VERSION "created by canmatrix"

NS_ :

BS_:

BU_: IPD

BO_ 840 FDR_ADAS_LocalCANFD3_FrP09: 64 Vector__XXX
 SG_ MRR_Obj_CRC16Checksum_17 : 7|8@0+ (1,0) [0|255] "null" IPD
 SG_ MRR_Obj_MsgCounter_17 : 11|4@0+ (1,0) [0|15] "null" IPD
 SG_ MRR_ObjMovingSts_17 : 23|4@0+ (1,0) [0|15] "null" IPD
 SG_ MRR_ObjID_17 : 31|8@0+ (1,0) [0|255] "null" IPD
 SG_ MRR_ObjObstacleProb_17 : 34|5@0+ (0.03125,0) [0.00000|0.96875] "null" IPD
 SG_ MRR_ObjExistProb_17 : 39|5@0+ (0.03125,0) [0.00000|0.96875] "null" IPD
 SG_ MRR_ObjDistY_17 : 45|14@0+ (0.0078125,-64) [-64.0000000|63.9921875] "null" IPD
 SG_ MRR_ObjDistX_17 : 63|12@0+ (0.0625,0) [0.0000|255.9375] "null" IPD
 SG_ MRR_ObjType_17 : 67|4@0+ (1,0) [0|15] "null" IPD
 SG_ MRR_ObjRelVelX_17 : 79|13@0+ (0.0312,-128) [-128.0000|127.5592] "null" IPD
 SG_ MRR_ObjAccelX_17 : 81|10@0+ (0.03125,-16) [-16.00000|15.96875] "null" IPD
 SG_ MRR_ObjRelVelY_17 : 103|13@0+ (0.0312,-128) [-128.0000|127.5592] "null" IPD
 SG_ MRR_ObjAccelY_17 : 105|10@0+ (0.03125,-16) [-16.00000|15.96875] "null" IPD
 SG_ MRR_ObjDistYStd_17 : 121|6@0+ (0.0625,0) [0.0000|3.9375] "null" IPD
 SG_ MRR_ObjDistXStd_17 : 127|6@0+ (0.0625,0) [0.0000|3.9375] "null" IPD
 SG_ MRR_ObjRelVelXStd_17 : 131|6@0+ (0.0625,0) [0.0000|3.9375] "null" IPD
 SG_ MRR_ObjRelVelYStd_17 : 141|6@0+ (0.0625,0) [0.0000|3.9375] "null" IPD
 SG_ MRR_ObjRAccelYStd_17 : 145|6@0+ (0.0625,0) [0.0000|3.9375] "null" IPD
 SG_ MRR_ObjRAccelXStd_17 : 151|6@0+ (0.0625,0) [0.0000|3.9375] "null" IPD
 SG_ MRR_ObjFolSts_17 : 154|2@0+ (1,0) [0|3] "null" IPD
 SG_ MRR_ObjFusionSig_17 : 155|1@0+ (1,0) [0|1] "null" IPD
 SG_ MRR_ObjFusionCamID_17 : 167|8@0+ (1,0) [0|255] "null" IPD
 SG_ MRR_Obj_CRC16Checksum_18 : 175|8@0+ (1,0) [0|255] "null" IPD
 SG_ MRR_Obj_MsgCounter_18 : 179|4@0+ (1,0) [0|15] "null" IPD
 SG_ MRR_ObjID_18 : 199|8@0+ (1,0) [0|255] "null" IPD
 SG_ MRR_ObjObstacleProb_18 : 202|5@0+ (0.03125,0) [0.00000|0.96875] "null" IPD
 SG_ MRR_ObjExistProb_18 : 207|5@0+ (0.03125,0) [0.00000|0.96875] "null" IPD
 SG_ MRR_ObjDistY_18 : 213|14@0+ (0.0078125,-64) [-64.0000000|63.9921875] "null" IPD
 SG_ MRR_ObjDistX_18 : 231|12@0+ (0.0625,0) [0.0000|255.9375] "null" IPD
 SG_ MRR_ObjType_18 : 235|4@0+ (1,0) [0|15] "null" IPD
 SG_ MRR_ObjRelVelX_18 : 247|13@0+ (0.0312,-128) [-128.0000|127.5592] "null" IPD
 SG_ MRR_ObjAccelX_18 : 249|10@0+ (0.03125,-16) [-16.00000|15.96875] "null" IPD
 SG_ MRR_ObjRelVelY_18 : 271|13@0+ (0.0312,-128) [-128.0000|127.5592] "null" IPD
 SG_ MRR_ObjAccelY_18 : 273|10@0+ (0.03125,-16) [-16.00000|15.96875] "null" IPD
 SG_ MRR_ObjDistYStd_18 : 289|6@0+ (0.0625,0) [0.0000|3.9375] "null" IPD
 SG_ MRR_ObjDistXStd_18 : 295|6@0+ (0.0625,0) [0.0000|3.9375] "null" IPD
 SG_ MRR_ObjRelVelXStd_18 : 299|6@0+ (0.0625,0) [0.0000|3.9375] "null" IPD
 SG_ MRR_ObjRelVelYStd_18 : 309|6@0+ (0.0625,0) [0.0000|3.9375] "null" IPD
 SG_ MRR_ObjRAccelYStd_18 : 313|6@0+ (0.0625,0) [0.0000|3.9375] "null" IPD
 SG_ MRR_ObjRAccelXStd_18 : 319|6@0+ (0.0625,0) [0.0000|3.9375] "null" IPD
 SG_ MRR_ObjFolSts_18 : 322|2@0+ (1,0) [0|3] "null" IPD
 SG_ MRR_ObjFusionSig_18 : 323|1@0+ (1,0) [0|1] "null" IPD
 SG_ MRR_ObjFusionCamID_18 : 335|8@0+ (1,0) [0|255] "null" IPD
 SG_ MRR_ObjMovingSts_18 : 339|4@0+ (1,0) [0|15] "null" IPD

BO_ 841 FDR_ADAS_LocalCANFD3_FrP10: 64 Vector__XXX
 SG_ MRR_Obj_CRC16Checksum_19 : 7|8@0+ (1,0) [0|255] "null" IPD
 SG_ MRR_Obj_MsgCounter_19 : 11|4@0+ (1,0) [0|15] "null" IPD
 SG_ MRR_ObjMovingSts_19 : 23|4@0+ (1,0) [0|15] "null" IPD
 SG_ MRR_ObjID_19 : 31|8@0+ (1,0) [0|255] "null" IPD
 SG_ MRR_ObjObstacleProb_19 : 34|5@0+ (0.03125,0) [0.00000|0.96875] "null" IPD
 SG_ MRR_ObjExistProb_19 : 39|5@0+ (0.03125,0) [0.00000|0.96875] "null" IPD
 SG_ MRR_ObjDistY_19 : 45|14@0+ (0.0078125,-64) [-64.0000000|63.9921875] "null" IPD
 SG_ MRR_ObjDistX_19 : 63|12@0+ (0.0625,0) [0.0000|255.9375] "null" IPD
 SG_ MRR_ObjType_19 : 67|4@0+ (1,0) [0|15] "null" IPD
 SG_ MRR_ObjRelVelX_19 : 79|13@0+ (0.0312,-128) [-128.0000|127.5592] "null" IPD
 SG_ MRR_ObjAccelX_19 : 81|10@0+ (0.03125,-16) [-16.00000|15.96875] "null" IPD
 SG_ MRR_ObjRelVelY_19 : 103|13@0+ (0.0312,-128) [-128.0000|127.5592] "null" IPD
 SG_ MRR_ObjAccelY_19 : 105|10@0+ (0.03125,-16) [-16.00000|15.96875] "null" IPD
 SG_ MRR_ObjDistYStd_19 : 121|6@0+ (0.0625,0) [0.0000|3.9375] "null" IPD
 SG_ MRR_ObjDistXStd_19 : 127|6@0+ (0.0625,0) [0.0000|3.9375] "null" IPD
 SG_ MRR_ObjRelVelXStd_19 : 131|6@0+ (0.0625,0) [0.0000|3.9375] "null" IPD
 SG_ MRR_ObjRelVelYStd_19 : 141|6@0+ (0.0625,0) [0.0000|3.9375] "null" IPD
 SG_ MRR_ObjRAccelYStd_19 : 145|6@0+ (0.0625,0) [0.0000|3.9375] "null" IPD
 SG_ MRR_ObjRAccelXStd_19 : 151|6@0+ (0.0625,0) [0.0000|3.9375] "null" IPD
 SG_ MRR_ObjFolSts_19 : 154|2@0+ (1,0) [0|3] "null" IPD
 SG_ MRR_ObjFusionSig_19 : 155|1@0+ (1,0) [0|1] "null" IPD
 SG_ MRR_ObjFusionCamID_19 : 167|8@0+ (1,0) [0|255] "null" IPD
 SG_ MRR_Obj_CRC16Checksum_20 : 175|8@0+ (1,0) [0|255] "null" IPD
 SG_ MRR_Obj_MsgCounter_20 : 179|4@0+ (1,0) [0|15] "null" IPD
 SG_ MRR_ObjID_20 : 199|8@0+ (1,0) [0|255] "null" IPD
 SG_ MRR_ObjObstacleProb_20 : 202|5@0+ (0.03125,0) [0.00000|0.96875] "null" IPD
 SG_ MRR_ObjExistProb_20 : 207|5@0+ (0.03125,0) [0.00000|0.96875] "null" IPD
 SG_ MRR_ObjDistY_20 : 213|14@0+ (0.0078125,-64) [-64.0000000|63.9921875] "null" IPD
 SG_ MRR_ObjDistX_20 : 231|12@0+ (0.0625,0) [0.0000|255.9375] "null" IPD
 SG_ MRR_ObjType_20 : 235|4@0+ (1,0) [0|15] "null" IPD
 SG_ MRR_ObjRelVelX_20 : 247|13@0+ (0.0312,-128) [-128.0000|127.5592] "null" IPD
 SG_ MRR_ObjAccelX_20 : 249|10@0+ (0.03125,-16) [-16.00000|15.96875] "null" IPD
 SG_ MRR_ObjRelVelY_20 : 271|13@0+ (0.0312,-128) [-128.0000|127.5592] "null" IPD
 SG_ MRR_ObjAccelY_20 : 273|10@0+ (0.03125,-16) [-16.00000|15.96875] "null" IPD
 SG_ MRR_ObjDistYStd_20 : 289|6@0+ (0.0625,0) [0.0000|3.9375] "null" IPD
 SG_ MRR_ObjDistXStd_20 : 295|6@0+ (0.0625,0) [0.0000|3.9375] "null" IPD
 SG_ MRR_ObjRelVelXStd_20 : 299|6@0+ (0.0625,0) [0.0000|3.9375] "null" IPD
 SG_ MRR_ObjRelVelYStd_20 : 309|6@0+ (0.0625,0) [0.0000|3.9375] "null" IPD
 SG_ MRR_ObjRAccelYStd_20 : 313|6@0+ (0.0625,0) [0.0000|3.9375] "null" IPD
 SG_ MRR_ObjRAccelXStd_20 : 319|6@0+ (0.0625,0) [0.0000|3.9375] "null" IPD
 SG_ MRR_ObjFolSts_20 : 322|2@0+ (1,0) [0|3] "null" IPD
 SG_ MRR_ObjFusionSig_20 : 323|1@0+ (1,0) [0|1] "null" IPD
 SG_ MRR_ObjFusionCamID_20 : 335|8@0+ (1,0) [0|255] "null" IPD
 SG_ MRR_ObjMovingSts_20 : 339|4@0+ (1,0) [0|15] "null" IPD

BO_ 842 FDR_ADAS_LocalCANFD3_FrP11: 64 Vector__XXX
 SG_ MRR_Obj_CRC16Checksum_21 : 7|8@0+ (1,0) [0|255] "null" IPD
 SG_ MRR_Obj_MsgCounter_21 : 11|4@0+ (1,0) [0|15] "null" IPD
 SG_ MRR_ObjMovingSts_21 : 23|4@0+ (1,0) [0|15] "null" IPD
 SG_ MRR_ObjID_21 : 31|8@0+ (1,0) [0|255] "null" IPD
 SG_ MRR_ObjObstacleProb_21 : 34|5@0+ (0.03125,0) [0.00000|0.96875] "null" IPD
 SG_ MRR_ObjExistProb_21 : 39|5@0+ (0.03125,0) [0.00000|0.96875] "null" IPD
 SG_ MRR_ObjDistY_21 : 45|14@0+ (0.0078125,-64) [-64.0000000|63.9921875] "null" IPD
 SG_ MRR_ObjDistX_21 : 63|12@0+ (0.0625,0) [0.0000|255.9375] "null" IPD
 SG_ MRR_ObjType_21 : 67|4@0+ (1,0) [0|15] "null" IPD
 SG_ MRR_ObjRelVelX_21 : 79|13@0+ (0.0312,-128) [-128.0000|127.5592] "null" IPD
 SG_ MRR_ObjAccelX_21 : 81|10@0+ (0.03125,-16) [-16.00000|15.96875] "null" IPD
 SG_ MRR_ObjRelVelY_21 : 103|13@0+ (0.0312,-128) [-128.0000|127.5592] "null" IPD
 SG_ MRR_ObjAccelY_21 : 105|10@0+ (0.03125,-16) [-16.00000|15.96875] "null" IPD
 SG_ MRR_ObjDistYStd_21 : 121|6@0+ (0.0625,0) [0.0000|3.9375] "null" IPD
 SG_ MRR_ObjDistXStd_21 : 127|6@0+ (0.0625,0) [0.0000|3.9375] "null" IPD
 SG_ MRR_ObjRelVelXStd_21 : 131|6@0+ (0.0625,0) [0.0000|3.9375] "null" IPD
 SG_ MRR_ObjRelVelYStd_21 : 141|6@0+ (0.0625,0) [0.0000|3.9375] "null" IPD
 SG_ MRR_ObjRAccelYStd_21 : 145|6@0+ (0.0625,0) [0.0000|3.9375] "null" IPD
 SG_ MRR_ObjRAccelXStd_21 : 151|6@0+ (0.0625,0) [0.0000|3.9375] "null" IPD
 SG_ MRR_ObjFolSts_21 : 154|2@0+ (1,0) [0|3] "null" IPD
 SG_ MRR_ObjFusionSig_21 : 155|1@0+ (1,0) [0|1] "null" IPD
 SG_ MRR_ObjFusionCamID_21 : 167|8@0+ (1,0) [0|255] "null" IPD
 SG_ MRR_Obj_CRC16Checksum_22 : 175|8@0+ (1,0) [0|255] "null" IPD
 SG_ MRR_Obj_MsgCounter_22 : 179|4@0+ (1,0) [0|15] "null" IPD
 SG_ MRR_ObjID_22 : 199|8@0+ (1,0) [0|255] "null" IPD
 SG_ MRR_ObjObstacleProb_22 : 202|5@0+ (0.03125,0) [0.00000|0.96875] "null" IPD
 SG_ MRR_ObjExistProb_22 : 207|5@0+ (0.03125,0) [0.00000|0.96875] "null" IPD
 SG_ MRR_ObjDistY_22 : 213|14@0+ (0.0078125,-64) [-64.0000000|63.9921875] "null" IPD
 SG_ MRR_ObjDistX_22 : 231|12@0+ (0.0625,0) [0.0000|255.9375] "null" IPD
 SG_ MRR_ObjType_22 : 235|4@0+ (1,0) [0|15] "null" IPD
 SG_ MRR_ObjRelVelX_22 : 247|13@0+ (0.0312,-128) [-128.0000|127.5592] "null" IPD
 SG_ MRR_ObjAccelX_22 : 249|10@0+ (0.03125,-16) [-16.00000|15.96875] "null" IPD
 SG_ MRR_ObjRelVelY_22 : 271|13@0+ (0.0312,-128) [-128.0000|127.5592] "null" IPD
 SG_ MRR_ObjAccelY_22 : 273|10@0+ (0.03125,-16) [-16.00000|15.96875] "null" IPD
 SG_ MRR_ObjDistYStd_22 : 289|6@0+ (0.0625,0) [0.0000|3.9375] "null" IPD
 SG_ MRR_ObjDistXStd_22 : 295|6@0+ (0.0625,0) [0.0000|3.9375] "null" IPD
 SG_ MRR_ObjRelVelXStd_22 : 299|6@0+ (0.0625,0) [0.0000|3.9375] "null" IPD
 SG_ MRR_ObjRelVelYStd_22 : 309|6@0+ (0.0625,0) [0.0000|3.9375] "null" IPD
 SG_ MRR_ObjRAccelYStd_22 : 313|6@0+ (0.0625,0) [0.0000|3.9375] "null" IPD
 SG_ MRR_ObjRAccelXStd_22 : 319|6@0+ (0.0625,0) [0.0000|3.9375] "null" IPD
 SG_ MRR_ObjFolSts_22 : 322|2@0+ (1,0) [0|3] "null" IPD
 SG_ MRR_ObjFusionSig_22 : 323|1@0+ (1,0) [0|1] "null" IPD
 SG_ MRR_ObjFusionCamID_22 : 335|8@0+ (1,0) [0|255] "null" IPD
 SG_ MRR_ObjMovingSts_22 : 339|4@0+ (1,0) [0|15] "null" IPD

BO_ 843 FDR_ADAS_LocalCANFD3_FrP12: 64 Vector__XXX
 SG_ MRR_Obj_CRC16Checksum_23 : 7|8@0+ (1,0) [0|255] "null" IPD
 SG_ MRR_Obj_MsgCounter_23 : 11|4@0+ (1,0) [0|15] "null" IPD
 SG_ MRR_ObjMovingSts_23 : 23|4@0+ (1,0) [0|15] "null" IPD
 SG_ MRR_ObjID_23 : 31|8@0+ (1,0) [0|255] "null" IPD
 SG_ MRR_ObjObstacleProb_23 : 34|5@0+ (0.03125,0) [0.00000|0.96875] "null" IPD
 SG_ MRR_ObjExistProb_23 : 39|5@0+ (0.03125,0) [0.00000|0.96875] "null" IPD
 SG_ MRR_ObjDistY_23 : 45|14@0+ (0.0078125,-64) [-64.0000000|63.9921875] "null" IPD
 SG_ MRR_ObjDistX_23 : 63|12@0+ (0.0625,0) [0.0000|255.9375] "null" IPD
 SG_ MRR_ObjType_23 : 67|4@0+ (1,0) [0|15] "null" IPD
 SG_ MRR_ObjRelVelX_23 : 79|13@0+ (0.0312,-128) [-128.0000|127.5592] "null" IPD
 SG_ MRR_ObjAccelX_23 : 81|10@0+ (0.03125,-16) [-16.00000|15.96875] "null" IPD
 SG_ MRR_ObjRelVelY_23 : 103|13@0+ (0.0312,-128) [-128.0000|127.5592] "null" IPD
 SG_ MRR_ObjAccelY_23 : 105|10@0+ (0.03125,-16) [-16.00000|15.96875] "null" IPD
 SG_ MRR_ObjDistYStd_23 : 121|6@0+ (0.0625,0) [0.0000|3.9375] "null" IPD
 SG_ MRR_ObjDistXStd_23 : 127|6@0+ (0.0625,0) [0.0000|3.9375] "null" IPD
 SG_ MRR_ObjRelVelXStd_23 : 131|6@0+ (0.0625,0) [0.0000|3.9375] "null" IPD
 SG_ MRR_ObjRelVelYStd_23 : 141|6@0+ (0.0625,0) [0.0000|3.9375] "null" IPD
 SG_ MRR_ObjRAccelYStd_23 : 145|6@0+ (0.0625,0) [0.0000|3.9375] "null" IPD
 SG_ MRR_ObjRAccelXStd_23 : 151|6@0+ (0.0625,0) [0.0000|3.9375] "null" IPD
 SG_ MRR_ObjFolSts_23 : 154|2@0+ (1,0) [0|3] "null" IPD
 SG_ MRR_ObjFusionSig_23 : 155|1@0+ (1,0) [0|1] "null" IPD
 SG_ MRR_ObjFusionCamID_23 : 167|8@0+ (1,0) [0|255] "null" IPD
 SG_ MRR_Obj_CRC16Checksum_24 : 175|8@0+ (1,0) [0|255] "null" IPD
 SG_ MRR_Obj_MsgCounter_24 : 179|4@0+ (1,0) [0|15] "null" IPD
 SG_ MRR_ObjID_24 : 199|8@0+ (1,0) [0|255] "null" IPD
 SG_ MRR_ObjObstacleProb_24 : 202|5@0+ (0.03125,0) [0.00000|0.96875] "null" IPD
 SG_ MRR_ObjExistProb_24 : 207|5@0+ (0.03125,0) [0.00000|0.96875] "null" IPD
 SG_ MRR_ObjDistY_24 : 213|14@0+ (0.0078125,-64) [-64.0000000|63.9921875] "null" IPD
 SG_ MRR_ObjDistX_24 : 231|12@0+ (0.0625,0) [0.0000|255.9375] "null" IPD
 SG_ MRR_ObjType_24 : 235|4@0+ (1,0) [0|15] "null" IPD
 SG_ MRR_ObjRelVelX_24 : 247|13@0+ (0.0312,-128) [-128.0000|127.5592] "null" IPD
 SG_ MRR_ObjAccelX_24 : 249|10@0+ (0.03125,-16) [-16.00000|15.96875] "null" IPD
 SG_ MRR_ObjRelVelY_24 : 271|13@0+ (0.0312,-128) [-128.0000|127.5592] "null" IPD
 SG_ MRR_ObjAccelY_24 : 273|10@0+ (0.03125,-16) [-16.00000|15.96875] "null" IPD
 SG_ MRR_ObjDistYStd_24 : 289|6@0+ (0.0625,0) [0.0000|3.9375] "null" IPD
 SG_ MRR_ObjDistXStd_24 : 295|6@0+ (0.0625,0) [0.0000|3.9375] "null" IPD
 SG_ MRR_ObjRelVelXStd_24 : 299|6@0+ (0.0625,0) [0.0000|3.9375] "null" IPD
 SG_ MRR_ObjRelVelYStd_24 : 309|6@0+ (0.0625,0) [0.0000|3.9375] "null" IPD
 SG_ MRR_ObjRAccelYStd_24 : 313|6@0+ (0.0625,0) [0.0000|3.9375] "null" IPD
 SG_ MRR_ObjRAccelXStd_24 : 319|6@0+ (0.0625,0) [0.0000|3.9375] "null" IPD
 SG_ MRR_ObjFolSts_24 : 322|2@0+ (1,0) [0|3] "null" IPD
 SG_ MRR_ObjFusionSig_24 : 323|1@0+ (1,0) [0|1] "null" IPD
 SG_ MRR_ObjFusionCamID_24 : 335|8@0+ (1,0) [0|255] "null" IPD
 SG_ MRR_ObjMovingSts_24 : 339|4@0+ (1,0) [0|15] "null" IPD

BO_ 844 FDR_ADAS_LocalCANFD3_FrP13: 64 Vector__XXX
 SG_ MRR_Obj_CRC16Checksum_25 : 7|8@0+ (1,0) [0|255] "null" IPD
 SG_ MRR_Obj_MsgCounter_25 : 11|4@0+ (1,0) [0|15] "null" IPD
 SG_ MRR_ObjMovingSts_25 : 23|4@0+ (1,0) [0|15] "null" IPD
 SG_ MRR_ObjID_25 : 31|8@0+ (1,0) [0|255] "null" IPD
 SG_ MRR_ObjObstacleProb_25 : 34|5@0+ (0.03125,0) [0.00000|0.96875] "null" IPD
 SG_ MRR_ObjExistProb_25 : 39|5@0+ (0.03125,0) [0.00000|0.96875] "null" IPD
 SG_ MRR_ObjDistY_25 : 45|14@0+ (0.0078125,-64) [-64.0000000|63.9921875] "null" IPD
 SG_ MRR_ObjDistX_25 : 63|12@0+ (0.0625,0) [0.0000|255.9375] "null" IPD
 SG_ MRR_ObjType_25 : 67|4@0+ (1,0) [0|15] "null" IPD
 SG_ MRR_ObjRelVelX_25 : 79|13@0+ (0.0312,-128) [-128.0000|127.5592] "null" IPD
 SG_ MRR_ObjAccelX_25 : 81|10@0+ (0.03125,-16) [-16.00000|15.96875] "null" IPD
 SG_ MRR_ObjRelVelY_25 : 103|13@0+ (0.0312,-128) [-128.0000|127.5592] "null" IPD
 SG_ MRR_ObjAccelY_25 : 105|10@0+ (0.03125,-16) [-16.00000|15.96875] "null" IPD
 SG_ MRR_ObjDistYStd_25 : 121|6@0+ (0.0625,0) [0.0000|3.9375] "null" IPD
 SG_ MRR_ObjDistXStd_25 : 127|6@0+ (0.0625,0) [0.0000|3.9375] "null" IPD
 SG_ MRR_ObjRelVelXStd_25 : 131|6@0+ (0.0625,0) [0.0000|3.9375] "null" IPD
 SG_ MRR_ObjRelVelYStd_25 : 141|6@0+ (0.0625,0) [0.0000|3.9375] "null" IPD
 SG_ MRR_ObjRAccelYStd_25 : 145|6@0+ (0.0625,0) [0.0000|3.9375] "null" IPD
 SG_ MRR_ObjRAccelXStd_25 : 151|6@0+ (0.0625,0) [0.0000|3.9375] "null" IPD
 SG_ MRR_ObjFolSts_25 : 154|2@0+ (1,0) [0|3] "null" IPD
 SG_ MRR_ObjFusionSig_25 : 155|1@0+ (1,0) [0|1] "null" IPD
 SG_ MRR_ObjFusionCamID_25 : 167|8@0+ (1,0) [0|255] "null" IPD
 SG_ MRR_Obj_CRC16Checksum_26 : 175|8@0+ (1,0) [0|255] "null" IPD
 SG_ MRR_Obj_MsgCounter_26 : 179|4@0+ (1,0) [0|15] "null" IPD
 SG_ MRR_ObjID_26 : 199|8@0+ (1,0) [0|255] "null" IPD
 SG_ MRR_ObjObstacleProb_26 : 202|5@0+ (0.03125,0) [0.00000|0.96875] "null" IPD
 SG_ MRR_ObjExistProb_26 : 207|5@0+ (0.03125,0) [0.00000|0.96875] "null" IPD
 SG_ MRR_ObjDistY_26 : 213|14@0+ (0.0078125,-64) [-64.0000000|63.9921875] "null" IPD
 SG_ MRR_ObjDistX_26 : 231|12@0+ (0.0625,0) [0.0000|255.9375] "null" IPD
 SG_ MRR_ObjType_26 : 235|4@0+ (1,0) [0|15] "null" IPD
 SG_ MRR_ObjRelVelX_26 : 247|13@0+ (0.0312,-128) [-128.0000|127.5592] "null" IPD
 SG_ MRR_ObjAccelX_26 : 249|10@0+ (0.03125,-16) [-16.00000|15.96875] "null" IPD
 SG_ MRR_ObjRelVelY_26 : 271|13@0+ (0.0312,-128) [-128.0000|127.5592] "null" IPD
 SG_ MRR_ObjAccelY_26 : 273|10@0+ (0.03125,-16) [-16.00000|15.96875] "null" IPD
 SG_ MRR_ObjDistYStd_26 : 289|6@0+ (0.0625,0) [0.0000|3.9375] "null" IPD
 SG_ MRR_ObjDistXStd_26 : 295|6@0+ (0.0625,0) [0.0000|3.9375] "null" IPD
 SG_ MRR_ObjRelVelXStd_26 : 299|6@0+ (0.0625,0) [0.0000|3.9375] "null" IPD
 SG_ MRR_ObjRelVelYStd_26 : 309|6@0+ (0.0625,0) [0.0000|3.9375] "null" IPD
 SG_ MRR_ObjRAccelYStd_26 : 313|6@0+ (0.0625,0) [0.0000|3.9375] "null" IPD
 SG_ MRR_ObjRAccelXStd_26 : 319|6@0+ (0.0625,0) [0.0000|3.9375] "null" IPD
 SG_ MRR_ObjFolSts_26 : 322|2@0+ (1,0) [0|3] "null" IPD
 SG_ MRR_ObjFusionSig_26 : 323|1@0+ (1,0) [0|1] "null" IPD
 SG_ MRR_ObjFusionCamID_26 : 335|8@0+ (1,0) [0|255] "null" IPD
 SG_ MRR_ObjMovingSts_26 : 339|4@0+ (1,0) [0|15] "null" IPD

BO_ 845 FDR_ADAS_LocalCANFD3_FrP14: 64 Vector__XXX
 SG_ MRR_Obj_CRC16Checksum_27 : 7|8@0+ (1,0) [0|255] "null" IPD
 SG_ MRR_Obj_MsgCounter_27 : 11|4@0+ (1,0) [0|15] "null" IPD
 SG_ MRR_ObjMovingSts_27 : 23|4@0+ (1,0) [0|15] "null" IPD
 SG_ MRR_ObjID_27 : 31|8@0+ (1,0) [0|255] "null" IPD
 SG_ MRR_ObjObstacleProb_27 : 34|5@0+ (0.03125,0) [0.00000|0.96875] "null" IPD
 SG_ MRR_ObjExistProb_27 : 39|5@0+ (0.03125,0) [0.00000|0.96875] "null" IPD
 SG_ MRR_ObjDistY_27 : 45|14@0+ (0.0078125,-64) [-64.0000000|63.9921875] "null" IPD
 SG_ MRR_ObjDistX_27 : 63|12@0+ (0.0625,0) [0.0000|255.9375] "null" IPD
 SG_ MRR_ObjType_27 : 67|4@0+ (1,0) [0|15] "null" IPD
 SG_ MRR_ObjRelVelX_27 : 79|13@0+ (0.0312,-128) [-128.0000|127.5592] "null" IPD
 SG_ MRR_ObjAccelX_27 : 81|10@0+ (0.03125,-16) [-16.00000|15.96875] "null" IPD
 SG_ MRR_ObjRelVelY_27 : 103|13@0+ (0.0312,-128) [-128.0000|127.5592] "null" IPD
 SG_ MRR_ObjAccelY_27 : 105|10@0+ (0.03125,-16) [-16.00000|15.96875] "null" IPD
 SG_ MRR_ObjDistYStd_27 : 121|6@0+ (0.0625,0) [0.0000|3.9375] "null" IPD
 SG_ MRR_ObjDistXStd_27 : 127|6@0+ (0.0625,0) [0.0000|3.9375] "null" IPD
 SG_ MRR_ObjRelVelXStd_27 : 131|6@0+ (0.0625,0) [0.0000|3.9375] "null" IPD
 SG_ MRR_ObjRelVelYStd_27 : 141|6@0+ (0.0625,0) [0.0000|3.9375] "null" IPD
 SG_ MRR_ObjRAccelYStd_27 : 145|6@0+ (0.0625,0) [0.0000|3.9375] "null" IPD
 SG_ MRR_ObjRAccelXStd_27 : 151|6@0+ (0.0625,0) [0.0000|3.9375] "null" IPD
 SG_ MRR_ObjFolSts_27 : 154|2@0+ (1,0) [0|3] "null" IPD
 SG_ MRR_ObjFusionSig_27 : 155|1@0+ (1,0) [0|1] "null" IPD
 SG_ MRR_ObjFusionCamID_27 : 167|8@0+ (1,0) [0|255] "null" IPD
 SG_ MRR_Obj_CRC16Checksum_28 : 175|8@0+ (1,0) [0|255] "null" IPD
 SG_ MRR_Obj_MsgCounter_28 : 179|4@0+ (1,0) [0|15] "null" IPD
 SG_ MRR_ObjID_28 : 199|8@0+ (1,0) [0|255] "null" IPD
 SG_ MRR_ObjObstacleProb_28 : 202|5@0+ (0.03125,0) [0.00000|0.96875] "null" IPD
 SG_ MRR_ObjExistProb_28 : 207|5@0+ (0.03125,0) [0.00000|0.96875] "null" IPD
 SG_ MRR_ObjDistY_28 : 213|14@0+ (0.0078125,-64) [-64.0000000|63.9921875] "null" IPD
 SG_ MRR_ObjDistX_28 : 231|12@0+ (0.0625,0) [0.0000|255.9375] "null" IPD
 SG_ MRR_ObjType_28 : 235|4@0+ (1,0) [0|15] "null" IPD
 SG_ MRR_ObjRelVelX_28 : 247|13@0+ (0.0312,-128) [-128.0000|127.5592] "null" IPD
 SG_ MRR_ObjAccelX_28 : 249|10@0+ (0.03125,-16) [-16.00000|15.96875] "null" IPD
 SG_ MRR_ObjRelVelY_28 : 271|13@0+ (0.0312,-128) [-128.0000|127.5592] "null" IPD
 SG_ MRR_ObjAccelY_28 : 273|10@0+ (0.03125,-16) [-16.00000|15.96875] "null" IPD
 SG_ MRR_ObjDistYStd_28 : 289|6@0+ (0.0625,0) [0.0000|3.9375] "null" IPD
 SG_ MRR_ObjDistXStd_28 : 295|6@0+ (0.0625,0) [0.0000|3.9375] "null" IPD
 SG_ MRR_ObjRelVelXStd_28 : 299|6@0+ (0.0625,0) [0.0000|3.9375] "null" IPD
 SG_ MRR_ObjRelVelYStd_28 : 309|6@0+ (0.0625,0) [0.0000|3.9375] "null" IPD
 SG_ MRR_ObjRAccelYStd_28 : 313|6@0+ (0.0625,0) [0.0000|3.9375] "null" IPD
 SG_ MRR_ObjRAccelXStd_28 : 319|6@0+ (0.0625,0) [0.0000|3.9375] "null" IPD
 SG_ MRR_ObjFolSts_28 : 322|2@0+ (1,0) [0|3] "null" IPD
 SG_ MRR_ObjFusionSig_28 : 323|1@0+ (1,0) [0|1] "null" IPD
 SG_ MRR_ObjFusionCamID_28 : 335|8@0+ (1,0) [0|255] "null" IPD
 SG_ MRR_ObjMovingSts_28 : 339|4@0+ (1,0) [0|15] "null" IPD

BO_ 846 FDR_ADAS_LocalCANFD3_FrP15: 64 Vector__XXX
 SG_ MRR_Obj_CRC16Checksum_29 : 7|8@0+ (1,0) [0|255] "null" IPD
 SG_ MRR_Obj_MsgCounter_29 : 11|4@0+ (1,0) [0|15] "null" IPD
 SG_ MRR_ObjMovingSts_29 : 23|4@0+ (1,0) [0|15] "null" IPD
 SG_ MRR_ObjID_29 : 31|8@0+ (1,0) [0|255] "null" IPD
 SG_ MRR_ObjObstacleProb_29 : 34|5@0+ (0.03125,0) [0.00000|0.96875] "null" IPD
 SG_ MRR_ObjExistProb_29 : 39|5@0+ (0.03125,0) [0.00000|0.96875] "null" IPD
 SG_ MRR_ObjDistY_29 : 45|14@0+ (0.0078125,-64) [-64.0000000|63.9921875] "null" IPD
 SG_ MRR_ObjDistX_29 : 63|12@0+ (0.0625,0) [0.0000|255.9375] "null" IPD
 SG_ MRR_ObjType_29 : 67|4@0+ (1,0) [0|15] "null" IPD
 SG_ MRR_ObjRelVelX_29 : 79|13@0+ (0.0312,-128) [-128.0000|127.5592] "null" IPD
 SG_ MRR_ObjAccelX_29 : 81|10@0+ (0.03125,-16) [-16.00000|15.96875] "null" IPD
 SG_ MRR_ObjRelVelY_29 : 103|13@0+ (0.0312,-128) [-128.0000|127.5592] "null" IPD
 SG_ MRR_ObjAccelY_29 : 105|10@0+ (0.03125,-16) [-16.00000|15.96875] "null" IPD
 SG_ MRR_ObjDistYStd_29 : 121|6@0+ (0.0625,0) [0.0000|3.9375] "null" IPD
 SG_ MRR_ObjDistXStd_29 : 127|6@0+ (0.0625,0) [0.0000|3.9375] "null" IPD
 SG_ MRR_ObjRelVelXStd_29 : 131|6@0+ (0.0625,0) [0.0000|3.9375] "null" IPD
 SG_ MRR_ObjRelVelYStd_29 : 141|6@0+ (0.0625,0) [0.0000|3.9375] "null" IPD
 SG_ MRR_ObjRAccelYStd_29 : 145|6@0+ (0.0625,0) [0.0000|3.9375] "null" IPD
 SG_ MRR_ObjRAccelXStd_29 : 151|6@0+ (0.0625,0) [0.0000|3.9375] "null" IPD
 SG_ MRR_ObjFolSts_29 : 154|2@0+ (1,0) [0|3] "null" IPD
 SG_ MRR_ObjFusionSig_29 : 155|1@0+ (1,0) [0|1] "null" IPD
 SG_ MRR_ObjFusionCamID_29 : 167|8@0+ (1,0) [0|255] "null" IPD
 SG_ MRR_Obj_CRC16Checksum_30 : 175|8@0+ (1,0) [0|255] "null" IPD
 SG_ MRR_Obj_MsgCounter_30 : 179|4@0+ (1,0) [0|15] "null" IPD
 SG_ MRR_ObjID_30 : 199|8@0+ (1,0) [0|255] "null" IPD
 SG_ MRR_ObjObstacleProb_30 : 202|5@0+ (0.03125,0) [0.00000|0.96875] "null" IPD
 SG_ MRR_ObjExistProb_30 : 207|5@0+ (0.03125,0) [0.00000|0.96875] "null" IPD
 SG_ MRR_ObjDistY_30 : 213|14@0+ (0.0078125,-64) [-64.0000000|63.9921875] "null" IPD
 SG_ MRR_ObjDistX_30 : 231|12@0+ (0.0625,0) [0.0000|255.9375] "null" IPD
 SG_ MRR_ObjType_30 : 235|4@0+ (1,0) [0|15] "null" IPD
 SG_ MRR_ObjRelVelX_30 : 247|13@0+ (0.0312,-128) [-128.0000|127.5592] "null" IPD
 SG_ MRR_ObjAccelX_30 : 249|10@0+ (0.03125,-16) [-16.00000|15.96875] "null" IPD
 SG_ MRR_ObjRelVelY_30 : 271|13@0+ (0.0312,-128) [-128.0000|127.5592] "null" IPD
 SG_ MRR_ObjAccelY_30 : 273|10@0+ (0.03125,-16) [-16.00000|15.96875] "null" IPD
 SG_ MRR_ObjDistYStd_30 : 289|6@0+ (0.0625,0) [0.0000|3.9375] "null" IPD
 SG_ MRR_ObjDistXStd_30 : 295|6@0+ (0.0625,0) [0.0000|3.9375] "null" IPD
 SG_ MRR_ObjRelVelXStd_30 : 299|6@0+ (0.0625,0) [0.0000|3.9375] "null" IPD
 SG_ MRR_ObjRelVelYStd_30 : 309|6@0+ (0.0625,0) [0.0000|3.9375] "null" IPD
 SG_ MRR_ObjRAccelYStd_30 : 313|6@0+ (0.0625,0) [0.0000|3.9375] "null" IPD
 SG_ MRR_ObjRAccelXStd_30 : 319|6@0+ (0.0625,0) [0.0000|3.9375] "null" IPD
 SG_ MRR_ObjFolSts_30 : 322|2@0+ (1,0) [0|3] "null" IPD
 SG_ MRR_ObjFusionSig_30 : 323|1@0+ (1,0) [0|1] "null" IPD
 SG_ MRR_ObjFusionCamID_30 : 335|8@0+ (1,0) [0|255] "null" IPD
 SG_ MRR_ObjMovingSts_30 : 339|4@0+ (1,0) [0|15] "null" IPD

BO_ 847 FDR_ADAS_LocalCANFD3_FrP16: 64 Vector__XXX
 SG_ MRR_Obj_CRC16Checksum_31 : 7|8@0+ (1,0) [0|255] "null" IPD
 SG_ MRR_Obj_MsgCounter_31 : 11|4@0+ (1,0) [0|15] "null" IPD
 SG_ MRR_ObjMovingSts_31 : 23|4@0+ (1,0) [0|15] "null" IPD
 SG_ MRR_ObjID_31 : 31|8@0+ (1,0) [0|255] "null" IPD
 SG_ MRR_ObjObstacleProb_31 : 34|5@0+ (0.03125,0) [0.00000|0.96875] "null" IPD
 SG_ MRR_ObjExistProb_31 : 39|5@0+ (0.03125,0) [0.00000|0.96875] "null" IPD
 SG_ MRR_ObjDistY_31 : 45|14@0+ (0.0078125,-64) [-64.0000000|63.9921875] "null" IPD
 SG_ MRR_ObjDistX_31 : 63|12@0+ (0.0625,0) [0.0000|255.9375] "null" IPD
 SG_ MRR_ObjType_31 : 67|4@0+ (1,0) [0|15] "null" IPD
 SG_ MRR_ObjRelVelX_31 : 79|13@0+ (0.0312,-128) [-128.0000|127.5592] "null" IPD
 SG_ MRR_ObjAccelX_31 : 81|10@0+ (0.03125,-16) [-16.00000|15.96875] "null" IPD
 SG_ MRR_ObjRelVelY_31 : 103|13@0+ (0.0312,-128) [-128.0000|127.5592] "null" IPD
 SG_ MRR_ObjAccelY_31 : 105|10@0+ (0.03125,-16) [-16.00000|15.96875] "null" IPD
 SG_ MRR_ObjDistYStd_31 : 121|6@0+ (0.0625,0) [0.0000|3.9375] "null" IPD
 SG_ MRR_ObjDistXStd_31 : 127|6@0+ (0.0625,0) [0.0000|3.9375] "null" IPD
 SG_ MRR_ObjRelVelXStd_31 : 131|6@0+ (0.0625,0) [0.0000|3.9375] "null" IPD
 SG_ MRR_ObjRelVelYStd_31 : 141|6@0+ (0.0625,0) [0.0000|3.9375] "null" IPD
 SG_ MRR_ObjRAccelYStd_31 : 145|6@0+ (0.0625,0) [0.0000|3.9375] "null" IPD
 SG_ MRR_ObjRAccelXStd_31 : 151|6@0+ (0.0625,0) [0.0000|3.9375] "null" IPD
 SG_ MRR_ObjFolSts_31 : 154|2@0+ (1,0) [0|3] "null" IPD
 SG_ MRR_ObjFusionSig_31 : 155|1@0+ (1,0) [0|1] "null" IPD
 SG_ MRR_ObjFusionCamID_31 : 167|8@0+ (1,0) [0|255] "null" IPD
 SG_ MRR_Obj_CRC16Checksum_32 : 175|8@0+ (1,0) [0|255] "null" IPD
 SG_ MRR_Obj_MsgCounter_32 : 179|4@0+ (1,0) [0|15] "null" IPD
 SG_ MRR_ObjID_32 : 199|8@0+ (1,0) [0|255] "null" IPD
 SG_ MRR_ObjObstacleProb_32 : 202|5@0+ (0.03125,0) [0.00000|0.96875] "null" IPD
 SG_ MRR_ObjExistProb_32 : 207|5@0+ (0.03125,0) [0.00000|0.96875] "null" IPD
 SG_ MRR_ObjDistY_32 : 213|14@0+ (0.0078125,-64) [-64.0000000|63.9921875] "null" IPD
 SG_ MRR_ObjDistX_32 : 231|12@0+ (0.0625,0) [0.0000|255.9375] "null" IPD
 SG_ MRR_ObjType_32 : 235|4@0+ (1,0) [0|15] "null" IPD
 SG_ MRR_ObjRelVelX_32 : 247|13@0+ (0.0312,-128) [-128.0000|127.5592] "null" IPD
 SG_ MRR_ObjAccelX_32 : 249|10@0+ (0.03125,-16) [-16.00000|15.96875] "null" IPD
 SG_ MRR_ObjRelVelY_32 : 271|13@0+ (0.0312,-128) [-128.0000|127.5592] "null" IPD
 SG_ MRR_ObjAccelY_32 : 273|10@0+ (0.03125,-16) [-16.00000|15.96875] "null" IPD
 SG_ MRR_ObjDistYStd_32 : 289|6@0+ (0.0625,0) [0.0000|3.9375] "null" IPD
 SG_ MRR_ObjDistXStd_32 : 295|6@0+ (0.0625,0) [0.0000|3.9375] "null" IPD
 SG_ MRR_ObjRelVelXStd_32 : 299|6@0+ (0.0625,0) [0.0000|3.9375] "null" IPD
 SG_ MRR_ObjRelVelYStd_32 : 309|6@0+ (0.0625,0) [0.0000|3.9375] "null" IPD
 SG_ MRR_ObjRAccelYStd_32 : 313|6@0+ (0.0625,0) [0.0000|3.9375] "null" IPD
 SG_ MRR_ObjRAccelXStd_32 : 319|6@0+ (0.0625,0) [0.0000|3.9375] "null" IPD
 SG_ MRR_ObjFolSts_32 : 322|2@0+ (1,0) [0|3] "null" IPD
 SG_ MRR_ObjFusionSig_32 : 323|1@0+ (1,0) [0|1] "null" IPD
 SG_ MRR_ObjFusionCamID_32 : 335|8@0+ (1,0) [0|255] "null" IPD
 SG_ MRR_ObjMovingSts_32 : 339|4@0+ (1,0) [0|15] "null" IPD

BO_ 848 FDR_ADAS_LocalCANFD3_FrP17: 16 Vector__XXX
 SG_ FDR_ADAS_LocalCANFD3_PDU17_CRC : 7|8@0+ (1,0) [0|255] "null" IPD
 SG_ FDR_ADAS_LocalCANFD3_PDU17_RC : 11|4@0+ (1,0) [0|15] "null" IPD
 SG_ FDR_ADAS_LocalCANFD3_Group33_Res0 : 15|4@0+ (1,0) [0|15] "null" IPD
 SG_ FDR_ADAS_LocalCANFD3_Group33_Res1 : 23|8@0+ (1,0) [0|255] "null" IPD
 SG_ FDR_AEB_TargDx : 31|12@0+ (0.0625,0) [0.0000|255.9375] "null" IPD
 SG_ FDR_AEB_TargAx : 35|10@0+ (0.03125,-16) [-16.00000|15.96875] "null" IPD
 SG_ FDR_AEB_TargAy : 41|10@0+ (0.03125,-16) [-16.00000|15.96875] "null" IPD
 SG_ FDR_AEB_TargVy : 60|13@0+ (0.0312,-128) [-128.0000|127.5592] "null" IPD
 SG_ FDR_ADAS_LocalCANFD3_Group33_Res2 : 63|3@0+ (1,0) [0|7] "null" IPD
 SG_ FDR_ADAS_LocalCANFD3_Group33_Res3 : 74|3@0+ (1,0) [0|7] "null" IPD
 SG_ FDR_AEB_TargExistProb : 79|5@0+ (0.03125,0) [0.00000|0.96875] "null" IPD
 SG_ FDR_AEB_TargDy : 87|11@0+ (0.0625,-64) [-64.0000|63.9375] "null" IPD
 SG_ FDR_AEB_TargVx : 92|13@0+ (0.0312,-128) [-128.0000|127.5592] "null" IPD
 SG_ FDR_ADAS_LocalCANFD3_Group33_Res4 : 111|8@0+ (1,0) [0|255] "null" IPD
 SG_ FDR_ADAS_LocalCANFD3_Group33_Res5 : 119|8@0+ (1,0) [0|255] "null" IPD
 SG_ FDR_ADAS_LocalCANFD3_Group33_Res6 : 127|8@0+ (1,0) [0|255] "null" IPD

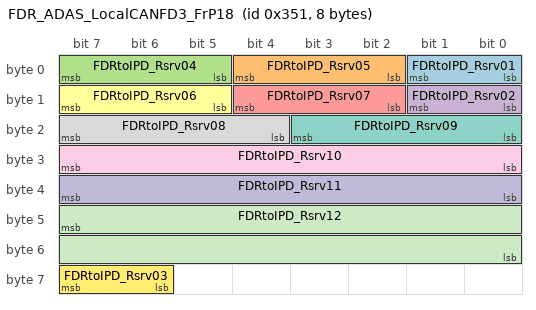
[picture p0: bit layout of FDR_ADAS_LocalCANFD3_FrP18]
BO_ 849 FDR_ADAS_LocalCANFD3_FrP18: 8 Vector__XXX
 SG_ FDRtoIPD_Rsrv01 : 1|2@0+ (1,0) [0|3] "null" IPD
 SG_ FDRtoIPD_Rsrv05 : 4|3@0+ (1,0) [0|7] "null" IPD
 SG_ FDRtoIPD_Rsrv04 : 7|3@0+ (1,0) [0|7] "null" IPD
 SG_ FDRtoIPD_Rsrv02 : 9|2@0+ (1,0) [0|3] "null" IPD
 SG_ FDRtoIPD_Rsrv07 : 12|3@0+ (1,0) [0|7] "null" IPD
 SG_ FDRtoIPD_Rsrv06 : 15|3@0+ (1,0) [0|7] "null" IPD
 SG_ FDRtoIPD_Rsrv09 : 19|4@0+ (1,0) [0|15] "null" IPD
 SG_ FDRtoIPD_Rsrv08 : 23|4@0+ (1,0) [0|15] "null" IPD
 SG_ FDRtoIPD_Rsrv10 : 31|8@0+ (1,0) [0|255] "null" IPD
 SG_ FDRtoIPD_Rsrv11 : 39|8@0+ (1,0) [0|255] "null" IPD
 SG_ FDRtoIPD_Rsrv12 : 47|16@0+ (1,0) [0|65535] "null" IPD
 SG_ FDRtoIPD_Rsrv03 : 63|2@0+ (1,0) [0|3] "null" IPD

BA_DEF_ BO_ "FrameTriggeringName" STRING;
BA_DEF_ BO_ "GenMsgCycleTime" INT 0 65535;
BA_DEF_ BO_ "GenMsgSendType" ENUM  "cyclicX","spontanX","cyclicIfActiveX","spontanWithDelay","cyclicAndSpontanX","cyclicAndSpontanWithDelay","spontanWithRepitition","cyclicIfActiveAndSpontanWD","cyclicIfActiveFast","cyclicWithRepeatOnDemand","none";
BA_DEF_ BO_ "GenMsgStartValue" STRING;
BA_DEF_ BO_ "PduName" STRING;
BA_DEF_ BO_ "VFrameFormat" ENUM  "StandardCAN","ExtendedCAN","reserved","reserved","reserved","reserved","reserved","reserved","reserved","reserved","reserved","reserved","reserved","reserved","StandardCAN_FD","ExtendedCAN_FD";
BA_DEF_ SG_ "CompuMethodName" STRING;
BA_DEF_ SG_ "GenSigStartValue" FLOAT 0 100000000000;
BA_DEF_ SG_ "ISignalName" STRING;
BA_DEF_ SG_ "LongName" STRING;
BA_DEF_ SG_ "SysSignalName" STRING;
BA_DEF_ SG_ "SystemSignalLongSymbol" STRING;
BA_ "FrameTriggeringName" BO_ 840 "FDR_ADAS_LocalCANFD3_FrP09";
BA_ "GenMsgCycleTime" BO_ 840 100;
BA_ "GenMsgSendType" BO_ 840 0;
BA_ "GenMsgStartValue" BO_ 840 "00000000000000000000000000000000000000000000000000000000000000000000000000000000000000000000000000000000000000000000000000000000";
BA_ "PduName" BO_ 840 "FDR_ADAS_LocalCANFD3_PDU09";
BA_ "VFrameFormat" BO_ 840 14;
BA_ "FrameTriggeringName" BO_ 841 "FDR_ADAS_LocalCANFD3_FrP10";
BA_ "GenMsgCycleTime" BO_ 841 100;
BA_ "GenMsgSendType" BO_ 841 0;
BA_ "GenMsgStartValue" BO_ 841 "00000000000000000000000000000000000000000000000000000000000000000000000000000000000000000000000000000000000000000000000000000000";
BA_ "PduName" BO_ 841 "FDR_ADAS_LocalCANFD3_PDU10";
BA_ "VFrameFormat" BO_ 841 14;
BA_ "FrameTriggeringName" BO_ 842 "FDR_ADAS_LocalCANFD3_FrP11";
BA_ "GenMsgCycleTime" BO_ 842 100;
BA_ "GenMsgSendType" BO_ 842 0;
BA_ "GenMsgStartValue" BO_ 842 "00000000000000000000000000000000000000000000000000000000000000000000000000000000000000000000000000000000000000000000000000000000";
BA_ "PduName" BO_ 842 "FDR_ADAS_LocalCANFD3_PDU11";
BA_ "VFrameFormat" BO_ 842 14;
BA_ "FrameTriggeringName" BO_ 843 "FDR_ADAS_LocalCANFD3_FrP12";
BA_ "GenMsgCycleTime" BO_ 843 100;
BA_ "GenMsgSendType" BO_ 843 0;
BA_ "GenMsgStartValue" BO_ 843 "00000000000000000000000000000000000000000000000000000000000000000000000000000000000000000000000000000000000000000000000000000000";
BA_ "PduName" BO_ 843 "FDR_ADAS_LocalCANFD3_PDU12";
BA_ "VFrameFormat" BO_ 843 14;
BA_ "FrameTriggeringName" BO_ 844 "FDR_ADAS_LocalCANFD3_FrP13";
BA_ "GenMsgCycleTime" BO_ 844 100;
BA_ "GenMsgSendType" BO_ 844 0;
BA_ "GenMsgStartValue" BO_ 844 "00000000000000000000000000000000000000000000000000000000000000000000000000000000000000000000000000000000000000000000000000000000";
BA_ "PduName" BO_ 844 "FDR_ADAS_LocalCANFD3_PDU13";
BA_ "VFrameFormat" BO_ 844 14;
BA_ "FrameTriggeringName" BO_ 845 "FDR_ADAS_LocalCANFD3_FrP14";
BA_ "GenMsgCycleTime" BO_ 845 100;
BA_ "GenMsgSendType" BO_ 845 0;
BA_ "GenMsgStartValue" BO_ 845 "00000000000000000000000000000000000000000000000000000000000000000000000000000000000000000000000000000000000000000000000000000000";
BA_ "PduName" BO_ 845 "FDR_ADAS_LocalCANFD3_PDU14";
BA_ "VFrameFormat" BO_ 845 14;
BA_ "FrameTriggeringName" BO_ 846 "FDR_ADAS_LocalCANFD3_FrP15";
BA_ "GenMsgCycleTime" BO_ 846 100;
BA_ "GenMsgSendType" BO_ 846 0;
BA_ "GenMsgStartValue" BO_ 846 "00000000000000000000000000000000000000000000000000000000000000000000000000000000000000000000000000000000000000000000000000000000";
BA_ "PduName" BO_ 846 "FDR_ADAS_LocalCANFD3_PDU15";
BA_ "VFrameFormat" BO_ 846 14;
BA_ "FrameTriggeringName" BO_ 847 "FDR_ADAS_LocalCANFD3_FrP16";
BA_ "GenMsgCycleTime" BO_ 847 100;
BA_ "GenMsgSendType" BO_ 847 0;
BA_ "GenMsgStartValue" BO_ 847 "00000000000000000000000000000000000000000000000000000000000000000000000000000000000000000000000000000000000000000000000000000000";
BA_ "PduName" BO_ 847 "FDR_ADAS_LocalCANFD3_PDU16";
BA_ "VFrameFormat" BO_ 847 14;
BA_ "FrameTriggeringName" BO_ 848 "FDR_ADAS_LocalCANFD3_FrP17";
BA_ "GenMsgCycleTime" BO_ 848 100;
BA_ "GenMsgSendType" BO_ 848 0;
BA_ "GenMsgStartValue" BO_ 848 "00f0ff00000000e00007000000ffffff";
BA_ "PduName" BO_ 848 "FDR_ADAS_LocalCANFD3_PDU17";
BA_ "VFrameFormat" BO_ 848 14;
BA_ "FrameTriggeringName" BO_ 849 "FDR_ADAS_LocalCANFD3_FrP18";
BA_ "GenMsgCycleTime" BO_ 849 100;
BA_ "GenMsgSendType" BO_ 849 0;
BA_ "GenMsgStartValue" BO_ 849 "0000000000000000";
BA_ "PduName" BO_ 849 "FDR_ADAS_LocalCANFD3_PDU18";
BA_ "VFrameFormat" BO_ 849 14;
BA_ "CompuMethodName" SG_ 840 MRR_Obj_CRC16Checksum_17 "MRR_Obj_CRC16Checksum_17";
BA_ "ISignalName" SG_ 840 MRR_Obj_CRC16Checksum_17 "IMRR_Obj_CRC16Checksum_17";
BA_ "LongName" SG_ 840 MRR_Obj_CRC16Checksum_17 "CRC80byte";
BA_ "SysSignalName" SG_ 840 MRR_Obj_CRC16Checksum_17 "MRR_Obj_CRC16Checksum_17";
BA_ "CompuMethodName" SG_ 840 MRR_Obj_MsgCounter_17 "MRR_Obj_MsgCounter_17";
BA_ "ISignalName" SG_ 840 MRR_Obj_MsgCounter_17 "IMRR_Obj_MsgCounter_17";
BA_ "LongName" SG_ 840 MRR_Obj_MsgCounter_17 "Alive counter 1byte4bit";
BA_ "SysSignalName" SG_ 840 MRR_Obj_MsgCounter_17 "MRR_Obj_MsgCounter_17";
BA_ "CompuMethodName" SG_ 840 MRR_ObjMovingSts_17 "MRR_ObjMovingSts_17";
BA_ "ISignalName" SG_ 840 MRR_ObjMovingSts_17 "IMRR_ObjMovingSts_17";
BA_ "LongName" SG_ 840 MRR_ObjMovingSts_17 "Object Moving Status";
BA_ "SysSignalName" SG_ 840 MRR_ObjMovingSts_17 "MRR_ObjMovingSts_17";
BA_ "CompuMethodName" SG_ 840 MRR_ObjID_17 "MRR_ObjID_17";
BA_ "ISignalName" SG_ 840 MRR_ObjID_17 "IMRR_ObjID_17";
BA_ "LongName" SG_ 840 MRR_ObjID_17 "Id Is An Identifier Number That Allows For Tracking Of Persistent Objects Over Time";
BA_ "SysSignalName" SG_ 840 MRR_ObjID_17 "MRR_ObjID_17";
BA_ "CompuMethodName" SG_ 840 MRR_ObjObstacleProb_17 "MRR_ObjObstacleProb_17";
BA_ "ISignalName" SG_ 840 MRR_ObjObstacleProb_17 "IMRR_ObjObstacleProb_17";
BA_ "LongName" SG_ 840 MRR_ObjObstacleProb_17 "The Probability Of An Object Being An Obstacle";
BA_ "SysSignalName" SG_ 840 MRR_ObjObstacleProb_17 "MRR_ObjObstacleProb_17";
BA_ "CompuMethodName" SG_ 840 MRR_ObjExistProb_17 "MRR_ObjExistProb_17";
BA_ "ISignalName" SG_ 840 MRR_ObjExistProb_17 "IMRR_ObjExistProb_17";
BA_ "LongName" SG_ 840 MRR_ObjExistProb_17 "The Probability Of An Object To Exist In Reality";
BA_ "SysSignalName" SG_ 840 MRR_ObjExistProb_17 "MRR_ObjExistProb_17";
BA_ "CompuMethodName" SG_ 840 MRR_ObjDistY_17 "MRR_ObjDistY_17";
BA_ "ISignalName" SG_ 840 MRR_ObjDistY_17 "IMRR_ObjDistY_17";
BA_ "LongName" SG_ 840 MRR_ObjDistY_17 "Position Of Target Vehicle In Y Direction";
BA_ "SysSignalName" SG_ 840 MRR_ObjDistY_17 "MRR_ObjDistY_17";
BA_ "CompuMethodName" SG_ 840 MRR_ObjDistX_17 "MRR_ObjDistX_17";
BA_ "ISignalName" SG_ 840 MRR_ObjDistX_17 "IMRR_ObjDistX_17";
BA_ "LongName" SG_ 840 MRR_ObjDistX_17 "Position Of Target Vehicle In X Direction";
BA_ "SysSignalName" SG_ 840 MRR_ObjDistX_17 "MRR_ObjDistX_17";
BA_ "CompuMethodName" SG_ 840 MRR_ObjType_17 "MRR_ObjType_17";
BA_ "ISignalName" SG_ 840 MRR_ObjType_17 "IMRR_ObjType_17";
BA_ "LongName" SG_ 840 MRR_ObjType_17 "Class Of Object Type";
BA_ "SysSignalName" SG_ 840 MRR_ObjType_17 "MRR_ObjType_17";
BA_ "CompuMethodName" SG_ 840 MRR_ObjRelVelX_17 "MRR_ObjRelVelX_17";
BA_ "ISignalName" SG_ 840 MRR_ObjRelVelX_17 "IMRR_ObjRelVelX_17";
BA_ "LongName" SG_ 840 MRR_ObjRelVelX_17 "Relative Target Object Velocity In X Direction";
BA_ "SysSignalName" SG_ 840 MRR_ObjRelVelX_17 "MRR_ObjRelVelX_17";
BA_ "CompuMethodName" SG_ 840 MRR_ObjAccelX_17 "MRR_ObjAccelX_17";
BA_ "ISignalName" SG_ 840 MRR_ObjAccelX_17 "IMRR_ObjAccelX_17";
BA_ "LongName" SG_ 840 MRR_ObjAccelX_17 "Relative Target Object Acceleration In X Direction";
BA_ "SysSignalName" SG_ 840 MRR_ObjAccelX_17 "MRR_ObjAccelX_17";
BA_ "CompuMethodName" SG_ 840 MRR_ObjRelVelY_17 "MRR_ObjRelVelY_17";
BA_ "ISignalName" SG_ 840 MRR_ObjRelVelY_17 "IMRR_ObjRelVelY_17";
BA_ "LongName" SG_ 840 MRR_ObjRelVelY_17 "Relative Target Object Velocity In Y Direction";
BA_ "SysSignalName" SG_ 840 MRR_ObjRelVelY_17 "MRR_ObjRelVelY_17";
BA_ "CompuMethodName" SG_ 840 MRR_ObjAccelY_17 "MRR_ObjAccelY_17";
BA_ "ISignalName" SG_ 840 MRR_ObjAccelY_17 "IMRR_ObjAccelY_17";
BA_ "LongName" SG_ 840 MRR_ObjAccelY_17 "Relative Target Object Acceleration In Y Direction";
BA_ "SysSignalName" SG_ 840 MRR_ObjAccelY_17 "MRR_ObjAccelY_17";
BA_ "CompuMethodName" SG_ 840 MRR_ObjDistYStd_17 "MRR_ObjDistYStd_17";
BA_ "ISignalName" SG_ 840 MRR_ObjDistYStd_17 "IMRR_ObjDistYStd_17";
BA_ "LongName" SG_ 840 MRR_ObjDistYStd_17 "Standard Deviation Of Distance Y";
BA_ "SysSignalName" SG_ 840 MRR_ObjDistYStd_17 "MRR_ObjDistYStd_17";
BA_ "CompuMethodName" SG_ 840 MRR_ObjDistXStd_17 "MRR_ObjDistXStd_17";
BA_ "ISignalName" SG_ 840 MRR_ObjDistXStd_17 "IMRR_ObjDistXStd_17";
BA_ "LongName" SG_ 840 MRR_ObjDistXStd_17 "Standard Deviation Of Distance X";
BA_ "SysSignalName" SG_ 840 MRR_ObjDistXStd_17 "MRR_ObjDistXStd_17";
BA_ "CompuMethodName" SG_ 840 MRR_ObjRelVelXStd_17 "MRR_ObjRelVelXStd_17";
BA_ "ISignalName" SG_ 840 MRR_ObjRelVelXStd_17 "IMRR_ObjRelVelXStd_17";
BA_ "LongName" SG_ 840 MRR_ObjRelVelXStd_17 "Standard Deviation Of Relative Velocity X";
BA_ "SysSignalName" SG_ 840 MRR_ObjRelVelXStd_17 "MRR_ObjRelVelXStd_17";
BA_ "CompuMethodName" SG_ 840 MRR_ObjRelVelYStd_17 "MRR_ObjRelVelYStd_17";
BA_ "ISignalName" SG_ 840 MRR_ObjRelVelYStd_17 "IMRR_ObjRelVelYStd_17";
BA_ "LongName" SG_ 840 MRR_ObjRelVelYStd_17 "Standard Deviation Of Relative Velocity Y";
BA_ "SysSignalName" SG_ 840 MRR_ObjRelVelYStd_17 "MRR_ObjRelVelYStd_17";
BA_ "CompuMethodName" SG_ 840 MRR_ObjRAccelYStd_17 "MRR_ObjRAccelYStd_17";
BA_ "ISignalName" SG_ 840 MRR_ObjRAccelYStd_17 "IMRR_ObjRAccelYStd_17";
BA_ "LongName" SG_ 840 MRR_ObjRAccelYStd_17 "Standard Deviation Of Relative Acceleration Y";
BA_ "SysSignalName" SG_ 840 MRR_ObjRAccelYStd_17 "MRR_ObjRAccelYStd_17";
BA_ "CompuMethodName" SG_ 840 MRR_ObjRAccelXStd_17 "MRR_ObjRAccelXStd_17";
BA_ "ISignalName" SG_ 840 MRR_ObjRAccelXStd_17 "IMRR_ObjRAccelXStd_17";
BA_ "LongName" SG_ 840 MRR_ObjRAccelXStd_17 "Standard Deviation Of Relative Acceleration X";
BA_ "SysSignalName" SG_ 840 MRR_ObjRAccelXStd_17 "MRR_ObjRAccelXStd_17";
BA_ "CompuMethodName" SG_ 840 MRR_ObjFolSts_17 "MRR_ObjFolSts_17";
BA_ "ISignalName" SG_ 840 MRR_ObjFolSts_17 "IMRR_ObjFolSts_17";
BA_ "LongName" SG_ 840 MRR_ObjFolSts_17 "Object tracking status";
BA_ "SysSignalName" SG_ 840 MRR_ObjFolSts_17 "MRR_ObjFolSts_17";
BA_ "CompuMethodName" SG_ 840 MRR_ObjFusionSig_17 "MRR_ObjFusionSig_17";
BA_ "ISignalName" SG_ 840 MRR_ObjFusionSig_17 "IMRR_ObjFusionSig_17";
BA_ "LongName" SG_ 840 MRR_ObjFusionSig_17 "Signal To Indicate Fusion With Camera Or Not";
BA_ "SysSignalName" SG_ 840 MRR_ObjFusionSig_17 "MRR_ObjFusionSig_17";
BA_ "CompuMethodName" SG_ 840 MRR_ObjFusionCamID_17 "MRR_ObjFusionCamID_17";
BA_ "ISignalName" SG_ 840 MRR_ObjFusionCamID_17 "IMRR_ObjFusionCamID_17";
BA_ "LongName" SG_ 840 MRR_ObjFusionCamID_17 "Camera Object Id";
BA_ "SysSignalName" SG_ 840 MRR_ObjFusionCamID_17 "MRR_ObjFusionCamID_17";
BA_ "CompuMethodName" SG_ 840 MRR_Obj_CRC16Checksum_18 "MRR_Obj_CRC16Checksum_18";
BA_ "ISignalName" SG_ 840 MRR_Obj_CRC16Checksum_18 "IMRR_Obj_CRC16Checksum_18";
BA_ "LongName" SG_ 840 MRR_Obj_CRC16Checksum_18 "CRC80byte";
BA_ "SysSignalName" SG_ 840 MRR_Obj_CRC16Checksum_18 "MRR_Obj_CRC16Checksum_18";
BA_ "CompuMethodName" SG_ 840 MRR_Obj_MsgCounter_18 "MRR_Obj_MsgCounter_18";
BA_ "ISignalName" SG_ 840 MRR_Obj_MsgCounter_18 "IMRR_Obj_MsgCounter_18";
BA_ "LongName" SG_ 840 MRR_Obj_MsgCounter_18 "Alive counter 1byte4bit";
BA_ "SysSignalName" SG_ 840 MRR_Obj_MsgCounter_18 "MRR_Obj_MsgCounter_18";
BA_ "CompuMethodName" SG_ 840 MRR_ObjID_18 "MRR_ObjID_18";
BA_ "ISignalName" SG_ 840 MRR_ObjID_18 "IMRR_ObjID_18";
BA_ "LongName" SG_ 840 MRR_ObjID_18 "Id Is An Identifier Number That Allows For Tracking Of Persistent Objects Over Time";
BA_ "SysSignalName" SG_ 840 MRR_ObjID_18 "MRR_ObjID_18";
BA_ "CompuMethodName" SG_ 840 MRR_ObjObstacleProb_18 "MRR_ObjObstacleProb_18";
BA_ "ISignalName" SG_ 840 MRR_ObjObstacleProb_18 "IMRR_ObjObstacleProb_18";
BA_ "LongName" SG_ 840 MRR_ObjObstacleProb_18 "The Probability Of An Object Being An Obstacle";
BA_ "SysSignalName" SG_ 840 MRR_ObjObstacleProb_18 "MRR_ObjObstacleProb_18";
BA_ "CompuMethodName" SG_ 840 MRR_ObjExistProb_18 "MRR_ObjExistProb_18";
BA_ "ISignalName" SG_ 840 MRR_ObjExistProb_18 "IMRR_ObjExistProb_18";
BA_ "LongName" SG_ 840 MRR_ObjExistProb_18 "The Probability Of An Object To Exist In Reality";
BA_ "SysSignalName" SG_ 840 MRR_ObjExistProb_18 "MRR_ObjExistProb_18";
BA_ "CompuMethodName" SG_ 840 MRR_ObjDistY_18 "MRR_ObjDistY_18";
BA_ "ISignalName" SG_ 840 MRR_ObjDistY_18 "IMRR_ObjDistY_18";
BA_ "LongName" SG_ 840 MRR_ObjDistY_18 "Position Of Target Vehicle In Y Direction";
BA_ "SysSignalName" SG_ 840 MRR_ObjDistY_18 "MRR_ObjDistY_18";
BA_ "CompuMethodName" SG_ 840 MRR_ObjDistX_18 "MRR_ObjDistX_18";
BA_ "ISignalName" SG_ 840 MRR_ObjDistX_18 "IMRR_ObjDistX_18";
BA_ "LongName" SG_ 840 MRR_ObjDistX_18 "Position Of Target Vehicle In X Direction";
BA_ "SysSignalName" SG_ 840 MRR_ObjDistX_18 "MRR_ObjDistX_18";
BA_ "CompuMethodName" SG_ 840 MRR_ObjType_18 "MRR_ObjType_18";
BA_ "ISignalName" SG_ 840 MRR_ObjType_18 "IMRR_ObjType_18";
BA_ "LongName" SG_ 840 MRR_ObjType_18 "Class Of Object Type";
BA_ "SysSignalName" SG_ 840 MRR_ObjType_18 "MRR_ObjType_18";
BA_ "CompuMethodName" SG_ 840 MRR_ObjRelVelX_18 "MRR_ObjRelVelX_18";
BA_ "ISignalName" SG_ 840 MRR_ObjRelVelX_18 "IMRR_ObjRelVelX_18";
BA_ "LongName" SG_ 840 MRR_ObjRelVelX_18 "Relative Target Object Velocity In X Direction";
BA_ "SysSignalName" SG_ 840 MRR_ObjRelVelX_18 "MRR_ObjRelVelX_18";
BA_ "CompuMethodName" SG_ 840 MRR_ObjAccelX_18 "MRR_ObjAccelX_18";
BA_ "ISignalName" SG_ 840 MRR_ObjAccelX_18 "IMRR_ObjAccelX_18";
BA_ "LongName" SG_ 840 MRR_ObjAccelX_18 "Relative Target Object Acceleration In X Direction";
BA_ "SysSignalName" SG_ 840 MRR_ObjAccelX_18 "MRR_ObjAccelX_18";
BA_ "CompuMethodName" SG_ 840 MRR_ObjRelVelY_18 "MRR_ObjRelVelY_18";
BA_ "ISignalName" SG_ 840 MRR_ObjRelVelY_18 "IMRR_ObjRelVelY_18";
BA_ "LongName" SG_ 840 MRR_ObjRelVelY_18 "Relative Target Object Velocity In Y Direction";
BA_ "SysSignalName" SG_ 840 MRR_ObjRelVelY_18 "MRR_ObjRelVelY_18";
BA_ "CompuMethodName" SG_ 840 MRR_ObjAccelY_18 "MRR_ObjAccelY_18";
BA_ "ISignalName" SG_ 840 MRR_ObjAccelY_18 "IMRR_ObjAccelY_18";
BA_ "LongName" SG_ 840 MRR_ObjAccelY_18 "Relative Target Object Acceleration In Y Direction";
BA_ "SysSignalName" SG_ 840 MRR_ObjAccelY_18 "MRR_ObjAccelY_18";
BA_ "CompuMethodName" SG_ 840 MRR_ObjDistYStd_18 "MRR_ObjDistYStd_18";
BA_ "ISignalName" SG_ 840 MRR_ObjDistYStd_18 "IMRR_ObjDistYStd_18";
BA_ "LongName" SG_ 840 MRR_ObjDistYStd_18 "Standard Deviation Of Distance Y";
BA_ "SysSignalName" SG_ 840 MRR_ObjDistYStd_18 "MRR_ObjDistYStd_18";
BA_ "CompuMethodName" SG_ 840 MRR_ObjDistXStd_18 "MRR_ObjDistXStd_18";
BA_ "ISignalName" SG_ 840 MRR_ObjDistXStd_18 "IMRR_ObjDistXStd_18";
BA_ "LongName" SG_ 840 MRR_ObjDistXStd_18 "Standard Deviation Of Distance X";
BA_ "SysSignalName" SG_ 840 MRR_ObjDistXStd_18 "MRR_ObjDistXStd_18";
BA_ "CompuMethodName" SG_ 840 MRR_ObjRelVelXStd_18 "MRR_ObjRelVelXStd_18";
BA_ "ISignalName" SG_ 840 MRR_ObjRelVelXStd_18 "IMRR_ObjRelVelXStd_18";
BA_ "LongName" SG_ 840 MRR_ObjRelVelXStd_18 "Standard Deviation Of Relative Velocity X";
BA_ "SysSignalName" SG_ 840 MRR_ObjRelVelXStd_18 "MRR_ObjRelVelXStd_18";
BA_ "CompuMethodName" SG_ 840 MRR_ObjRelVelYStd_18 "MRR_ObjRelVelYStd_18";
BA_ "ISignalName" SG_ 840 MRR_ObjRelVelYStd_18 "IMRR_ObjRelVelYStd_18";
BA_ "LongName" SG_ 840 MRR_ObjRelVelYStd_18 "Standard Deviation Of Relative Velocity Y";
BA_ "SysSignalName" SG_ 840 MRR_ObjRelVelYStd_18 "MRR_ObjRelVelYStd_18";
BA_ "CompuMethodName" SG_ 840 MRR_ObjRAccelYStd_18 "MRR_ObjRAccelYStd_18";
BA_ "ISignalName" SG_ 840 MRR_ObjRAccelYStd_18 "IMRR_ObjRAccelYStd_18";
BA_ "LongName" SG_ 840 MRR_ObjRAccelYStd_18 "Standard Deviation Of Relative Acceleration Y";
BA_ "SysSignalName" SG_ 840 MRR_ObjRAccelYStd_18 "MRR_ObjRAccelYStd_18";
BA_ "CompuMethodName" SG_ 840 MRR_ObjRAccelXStd_18 "MRR_ObjRAccelXStd_18";
BA_ "ISignalName" SG_ 840 MRR_ObjRAccelXStd_18 "IMRR_ObjRAccelXStd_18";
BA_ "LongName" SG_ 840 MRR_ObjRAccelXStd_18 "Standard Deviation Of Relative Acceleration X";
BA_ "SysSignalName" SG_ 840 MRR_ObjRAccelXStd_18 "MRR_ObjRAccelXStd_18";
BA_ "CompuMethodName" SG_ 840 MRR_ObjFolSts_18 "MRR_ObjFolSts_18";
BA_ "ISignalName" SG_ 840 MRR_ObjFolSts_18 "IMRR_ObjFolSts_18";
BA_ "LongName" SG_ 840 MRR_ObjFolSts_18 "Object tracking status";
BA_ "SysSignalName" SG_ 840 MRR_ObjFolSts_18 "MRR_ObjFolSts_18";
BA_ "CompuMethodName" SG_ 840 MRR_ObjFusionSig_18 "MRR_ObjFusionSig_18";
BA_ "ISignalName" SG_ 840 MRR_ObjFusionSig_18 "IMRR_ObjFusionSig_18";
BA_ "LongName" SG_ 840 MRR_ObjFusionSig_18 "Signal To Indicate Fusion With Camera Or Not";
BA_ "SysSignalName" SG_ 840 MRR_ObjFusionSig_18 "MRR_ObjFusionSig_18";
BA_ "CompuMethodName" SG_ 840 MRR_ObjFusionCamID_18 "MRR_ObjFusionCamID_18";
BA_ "ISignalName" SG_ 840 MRR_ObjFusionCamID_18 "IMRR_ObjFusionCamID_18";
BA_ "LongName" SG_ 840 MRR_ObjFusionCamID_18 "Camera Object Id";
BA_ "SysSignalName" SG_ 840 MRR_ObjFusionCamID_18 "MRR_ObjFusionCamID_18";
BA_ "CompuMethodName" SG_ 840 MRR_ObjMovingSts_18 "MRR_ObjMovingSts_18";
BA_ "ISignalName" SG_ 840 MRR_ObjMovingSts_18 "IMRR_ObjMovingSts_18";
BA_ "LongName" SG_ 840 MRR_ObjMovingSts_18 "Object Moving Status";
BA_ "SysSignalName" SG_ 840 MRR_ObjMovingSts_18 "MRR_ObjMovingSts_18";
BA_ "CompuMethodName" SG_ 841 MRR_Obj_CRC16Checksum_19 "MRR_Obj_CRC16Checksum_19";
BA_ "ISignalName" SG_ 841 MRR_Obj_CRC16Checksum_19 "IMRR_Obj_CRC16Checksum_19";
BA_ "LongName" SG_ 841 MRR_Obj_CRC16Checksum_19 "CRC80byte";
BA_ "SysSignalName" SG_ 841 MRR_Obj_CRC16Checksum_19 "MRR_Obj_CRC16Checksum_19";
BA_ "CompuMethodName" SG_ 841 MRR_Obj_MsgCounter_19 "MRR_Obj_MsgCounter_19";
BA_ "ISignalName" SG_ 841 MRR_Obj_MsgCounter_19 "IMRR_Obj_MsgCounter_19";
BA_ "LongName" SG_ 841 MRR_Obj_MsgCounter_19 "Alive counter 1byte4bit";
BA_ "SysSignalName" SG_ 841 MRR_Obj_MsgCounter_19 "MRR_Obj_MsgCounter_19";
BA_ "CompuMethodName" SG_ 841 MRR_ObjMovingSts_19 "MRR_ObjMovingSts_19";
BA_ "ISignalName" SG_ 841 MRR_ObjMovingSts_19 "IMRR_ObjMovingSts_19";
BA_ "LongName" SG_ 841 MRR_ObjMovingSts_19 "Object Moving Status";
BA_ "SysSignalName" SG_ 841 MRR_ObjMovingSts_19 "MRR_ObjMovingSts_19";
BA_ "CompuMethodName" SG_ 841 MRR_ObjID_19 "MRR_ObjID_19";
BA_ "ISignalName" SG_ 841 MRR_ObjID_19 "IMRR_ObjID_19";
BA_ "LongName" SG_ 841 MRR_ObjID_19 "Id Is An Identifier Number That Allows For Tracking Of Persistent Objects Over Time";
BA_ "SysSignalName" SG_ 841 MRR_ObjID_19 "MRR_ObjID_19";
BA_ "CompuMethodName" SG_ 841 MRR_ObjObstacleProb_19 "MRR_ObjObstacleProb_19";
BA_ "ISignalName" SG_ 841 MRR_ObjObstacleProb_19 "IMRR_ObjObstacleProb_19";
BA_ "LongName" SG_ 841 MRR_ObjObstacleProb_19 "The Probability Of An Object Being An Obstacle";
BA_ "SysSignalName" SG_ 841 MRR_ObjObstacleProb_19 "MRR_ObjObstacleProb_19";
BA_ "CompuMethodName" SG_ 841 MRR_ObjExistProb_19 "MRR_ObjExistProb_19";
BA_ "ISignalName" SG_ 841 MRR_ObjExistProb_19 "IMRR_ObjExistProb_19";
BA_ "LongName" SG_ 841 MRR_ObjExistProb_19 "The Probability Of An Object To Exist In Reality";
BA_ "SysSignalName" SG_ 841 MRR_ObjExistProb_19 "MRR_ObjExistProb_19";
BA_ "CompuMethodName" SG_ 841 MRR_ObjDistY_19 "MRR_ObjDistY_19";
BA_ "ISignalName" SG_ 841 MRR_ObjDistY_19 "IMRR_ObjDistY_19";
BA_ "LongName" SG_ 841 MRR_ObjDistY_19 "Position Of Target Vehicle In Y Direction";
BA_ "SysSignalName" SG_ 841 MRR_ObjDistY_19 "MRR_ObjDistY_19";
BA_ "CompuMethodName" SG_ 841 MRR_ObjDistX_19 "MRR_ObjDistX_19";
BA_ "ISignalName" SG_ 841 MRR_ObjDistX_19 "IMRR_ObjDistX_19";
BA_ "LongName" SG_ 841 MRR_ObjDistX_19 "Position Of Target Vehicle In X Direction";
BA_ "SysSignalName" SG_ 841 MRR_ObjDistX_19 "MRR_ObjDistX_19";
BA_ "CompuMethodName" SG_ 841 MRR_ObjType_19 "MRR_ObjType_19";
BA_ "ISignalName" SG_ 841 MRR_ObjType_19 "IMRR_ObjType_19";
BA_ "LongName" SG_ 841 MRR_ObjType_19 "Class Of Object Type";
BA_ "SysSignalName" SG_ 841 MRR_ObjType_19 "MRR_ObjType_19";
BA_ "CompuMethodName" SG_ 841 MRR_ObjRelVelX_19 "MRR_ObjRelVelX_19";
BA_ "ISignalName" SG_ 841 MRR_ObjRelVelX_19 "IMRR_ObjRelVelX_19";
BA_ "LongName" SG_ 841 MRR_ObjRelVelX_19 "Relative Target Object Velocity In X Direction";
BA_ "SysSignalName" SG_ 841 MRR_ObjRelVelX_19 "MRR_ObjRelVelX_19";
BA_ "CompuMethodName" SG_ 841 MRR_ObjAccelX_19 "MRR_ObjAccelX_19";
BA_ "ISignalName" SG_ 841 MRR_ObjAccelX_19 "IMRR_ObjAccelX_19";
BA_ "LongName" SG_ 841 MRR_ObjAccelX_19 "Relative Target Object Acceleration In X Direction";
BA_ "SysSignalName" SG_ 841 MRR_ObjAccelX_19 "MRR_ObjAccelX_19";
BA_ "CompuMethodName" SG_ 841 MRR_ObjRelVelY_19 "MRR_ObjRelVelY_19";
BA_ "ISignalName" SG_ 841 MRR_ObjRelVelY_19 "IMRR_ObjRelVelY_19";
BA_ "LongName" SG_ 841 MRR_ObjRelVelY_19 "Relative Target Object Velocity In Y Direction";
BA_ "SysSignalName" SG_ 841 MRR_ObjRelVelY_19 "MRR_ObjRelVelY_19";
BA_ "CompuMethodName" SG_ 841 MRR_ObjAccelY_19 "MRR_ObjAccelY_19";
BA_ "ISignalName" SG_ 841 MRR_ObjAccelY_19 "IMRR_ObjAccelY_19";
BA_ "LongName" SG_ 841 MRR_ObjAccelY_19 "Relative Target Object Acceleration In Y Direction";
BA_ "SysSignalName" SG_ 841 MRR_ObjAccelY_19 "MRR_ObjAccelY_19";
BA_ "CompuMethodName" SG_ 841 MRR_ObjDistYStd_19 "MRR_ObjDistYStd_19";
BA_ "ISignalName" SG_ 841 MRR_ObjDistYStd_19 "IMRR_ObjDistYStd_19";
BA_ "LongName" SG_ 841 MRR_ObjDistYStd_19 "Standard Deviation Of Distance Y";
BA_ "SysSignalName" SG_ 841 MRR_ObjDistYStd_19 "MRR_ObjDistYStd_19";
BA_ "CompuMethodName" SG_ 841 MRR_ObjDistXStd_19 "MRR_ObjDistXStd_19";
BA_ "ISignalName" SG_ 841 MRR_ObjDistXStd_19 "IMRR_ObjDistXStd_19";
BA_ "LongName" SG_ 841 MRR_ObjDistXStd_19 "Standard Deviation Of Distance X";
BA_ "SysSignalName" SG_ 841 MRR_ObjDistXStd_19 "MRR_ObjDistXStd_19";
BA_ "CompuMethodName" SG_ 841 MRR_ObjRelVelXStd_19 "MRR_ObjRelVelXStd_19";
BA_ "ISignalName" SG_ 841 MRR_ObjRelVelXStd_19 "IMRR_ObjRelVelXStd_19";
BA_ "LongName" SG_ 841 MRR_ObjRelVelXStd_19 "Standard Deviation Of Relative Velocity X";
BA_ "SysSignalName" SG_ 841 MRR_ObjRelVelXStd_19 "MRR_ObjRelVelXStd_19";
BA_ "CompuMethodName" SG_ 841 MRR_ObjRelVelYStd_19 "MRR_ObjRelVelYStd_19";
BA_ "ISignalName" SG_ 841 MRR_ObjRelVelYStd_19 "IMRR_ObjRelVelYStd_19";
BA_ "LongName" SG_ 841 MRR_ObjRelVelYStd_19 "Standard Deviation Of Relative Velocity Y";
BA_ "SysSignalName" SG_ 841 MRR_ObjRelVelYStd_19 "MRR_ObjRelVelYStd_19";
BA_ "CompuMethodName" SG_ 841 MRR_ObjRAccelYStd_19 "MRR_ObjRAccelYStd_19";
BA_ "ISignalName" SG_ 841 MRR_ObjRAccelYStd_19 "IMRR_ObjRAccelYStd_19";
BA_ "LongName" SG_ 841 MRR_ObjRAccelYStd_19 "Standard Deviation Of Relative Acceleration Y";
BA_ "SysSignalName" SG_ 841 MRR_ObjRAccelYStd_19 "MRR_ObjRAccelYStd_19";
BA_ "CompuMethodName" SG_ 841 MRR_ObjRAccelXStd_19 "MRR_ObjRAccelXStd_19";
BA_ "ISignalName" SG_ 841 MRR_ObjRAccelXStd_19 "IMRR_ObjRAccelXStd_19";
BA_ "LongName" SG_ 841 MRR_ObjRAccelXStd_19 "Standard Deviation Of Relative Acceleration X";
BA_ "SysSignalName" SG_ 841 MRR_ObjRAccelXStd_19 "MRR_ObjRAccelXStd_19";
BA_ "CompuMethodName" SG_ 841 MRR_ObjFolSts_19 "MRR_ObjFolSts_19";
BA_ "ISignalName" SG_ 841 MRR_ObjFolSts_19 "IMRR_ObjFolSts_19";
BA_ "LongName" SG_ 841 MRR_ObjFolSts_19 "Object tracking status";
BA_ "SysSignalName" SG_ 841 MRR_ObjFolSts_19 "MRR_ObjFolSts_19";
BA_ "CompuMethodName" SG_ 841 MRR_ObjFusionSig_19 "MRR_ObjFusionSig_19";
BA_ "ISignalName" SG_ 841 MRR_ObjFusionSig_19 "IMRR_ObjFusionSig_19";
BA_ "LongName" SG_ 841 MRR_ObjFusionSig_19 "Signal To Indicate Fusion With Camera Or Not";
BA_ "SysSignalName" SG_ 841 MRR_ObjFusionSig_19 "MRR_ObjFusionSig_19";
BA_ "CompuMethodName" SG_ 841 MRR_ObjFusionCamID_19 "MRR_ObjFusionCamID_19";
BA_ "ISignalName" SG_ 841 MRR_ObjFusionCamID_19 "IMRR_ObjFusionCamID_19";
BA_ "LongName" SG_ 841 MRR_ObjFusionCamID_19 "Camera Object Id";
BA_ "SysSignalName" SG_ 841 MRR_ObjFusionCamID_19 "MRR_ObjFusionCamID_19";
BA_ "CompuMethodName" SG_ 841 MRR_Obj_CRC16Checksum_20 "MRR_Obj_CRC16Checksum_20";
BA_ "ISignalName" SG_ 841 MRR_Obj_CRC16Checksum_20 "IMRR_Obj_CRC16Checksum_20";
BA_ "LongName" SG_ 841 MRR_Obj_CRC16Checksum_20 "CRC80byte";
BA_ "SysSignalName" SG_ 841 MRR_Obj_CRC16Checksum_20 "MRR_Obj_CRC16Checksum_20";
BA_ "CompuMethodName" SG_ 841 MRR_Obj_MsgCounter_20 "MRR_Obj_MsgCounter_20";
BA_ "ISignalName" SG_ 841 MRR_Obj_MsgCounter_20 "IMRR_Obj_MsgCounter_20";
BA_ "LongName" SG_ 841 MRR_Obj_MsgCounter_20 "Alive counter 1byte4bit";
BA_ "SysSignalName" SG_ 841 MRR_Obj_MsgCounter_20 "MRR_Obj_MsgCounter_20";
BA_ "CompuMethodName" SG_ 841 MRR_ObjID_20 "MRR_ObjID_20";
BA_ "ISignalName" SG_ 841 MRR_ObjID_20 "IMRR_ObjID_20";
BA_ "LongName" SG_ 841 MRR_ObjID_20 "Id Is An Identifier Number That Allows For Tracking Of Persistent Objects Over Time";
BA_ "SysSignalName" SG_ 841 MRR_ObjID_20 "MRR_ObjID_20";
BA_ "CompuMethodName" SG_ 841 MRR_ObjObstacleProb_20 "MRR_ObjObstacleProb_20";
BA_ "ISignalName" SG_ 841 MRR_ObjObstacleProb_20 "IMRR_ObjObstacleProb_20";
BA_ "LongName" SG_ 841 MRR_ObjObstacleProb_20 "The Probability Of An Object Being An Obstacle";
BA_ "SysSignalName" SG_ 841 MRR_ObjObstacleProb_20 "MRR_ObjObstacleProb_20";
BA_ "CompuMethodName" SG_ 841 MRR_ObjExistProb_20 "MRR_ObjExistProb_20";
BA_ "ISignalName" SG_ 841 MRR_ObjExistProb_20 "IMRR_ObjExistProb_20";
BA_ "LongName" SG_ 841 MRR_ObjExistProb_20 "The Probability Of An Object To Exist In Reality";
BA_ "SysSignalName" SG_ 841 MRR_ObjExistProb_20 "MRR_ObjExistProb_20";
BA_ "CompuMethodName" SG_ 841 MRR_ObjDistY_20 "MRR_ObjDistY_20";
BA_ "ISignalName" SG_ 841 MRR_ObjDistY_20 "IMRR_ObjDistY_20";
BA_ "LongName" SG_ 841 MRR_ObjDistY_20 "Position Of Target Vehicle In Y Direction";
BA_ "SysSignalName" SG_ 841 MRR_ObjDistY_20 "MRR_ObjDistY_20";
BA_ "CompuMethodName" SG_ 841 MRR_ObjDistX_20 "MRR_ObjDistX_20";
BA_ "ISignalName" SG_ 841 MRR_ObjDistX_20 "IMRR_ObjDistX_20";
BA_ "LongName" SG_ 841 MRR_ObjDistX_20 "Position Of Target Vehicle In X Direction";
BA_ "SysSignalName" SG_ 841 MRR_ObjDistX_20 "MRR_ObjDistX_20";
BA_ "CompuMethodName" SG_ 841 MRR_ObjType_20 "MRR_ObjType_20";
BA_ "ISignalName" SG_ 841 MRR_ObjType_20 "IMRR_ObjType_20";
BA_ "LongName" SG_ 841 MRR_ObjType_20 "Class Of Object Type";
BA_ "SysSignalName" SG_ 841 MRR_ObjType_20 "MRR_ObjType_20";
BA_ "CompuMethodName" SG_ 841 MRR_ObjRelVelX_20 "MRR_ObjRelVelX_20";
BA_ "ISignalName" SG_ 841 MRR_ObjRelVelX_20 "IMRR_ObjRelVelX_20";
BA_ "LongName" SG_ 841 MRR_ObjRelVelX_20 "Relative Target Object Velocity In X Direction";
BA_ "SysSignalName" SG_ 841 MRR_ObjRelVelX_20 "MRR_ObjRelVelX_20";
BA_ "CompuMethodName" SG_ 841 MRR_ObjAccelX_20 "MRR_ObjAccelX_20";
BA_ "ISignalName" SG_ 841 MRR_ObjAccelX_20 "IMRR_ObjAccelX_20";
BA_ "LongName" SG_ 841 MRR_ObjAccelX_20 "Relative Target Object Acceleration In X Direction";
BA_ "SysSignalName" SG_ 841 MRR_ObjAccelX_20 "MRR_ObjAccelX_20";
BA_ "CompuMethodName" SG_ 841 MRR_ObjRelVelY_20 "MRR_ObjRelVelY_20";
BA_ "ISignalName" SG_ 841 MRR_ObjRelVelY_20 "IMRR_ObjRelVelY_20";
BA_ "LongName" SG_ 841 MRR_ObjRelVelY_20 "Relative Target Object Velocity In Y Direction";
BA_ "SysSignalName" SG_ 841 MRR_ObjRelVelY_20 "MRR_ObjRelVelY_20";
BA_ "CompuMethodName" SG_ 841 MRR_ObjAccelY_20 "MRR_ObjAccelY_20";
BA_ "ISignalName" SG_ 841 MRR_ObjAccelY_20 "IMRR_ObjAccelY_20";
BA_ "LongName" SG_ 841 MRR_ObjAccelY_20 "Relative Target Object Acceleration In Y Direction";
BA_ "SysSignalName" SG_ 841 MRR_ObjAccelY_20 "MRR_ObjAccelY_20";
BA_ "CompuMethodName" SG_ 841 MRR_ObjDistYStd_20 "MRR_ObjDistYStd_20";
BA_ "ISignalName" SG_ 841 MRR_ObjDistYStd_20 "IMRR_ObjDistYStd_20";
BA_ "LongName" SG_ 841 MRR_ObjDistYStd_20 "Standard Deviation Of Distance Y";
BA_ "SysSignalName" SG_ 841 MRR_ObjDistYStd_20 "MRR_ObjDistYStd_20";
BA_ "CompuMethodName" SG_ 841 MRR_ObjDistXStd_20 "MRR_ObjDistXStd_20";
BA_ "ISignalName" SG_ 841 MRR_ObjDistXStd_20 "IMRR_ObjDistXStd_20";
BA_ "LongName" SG_ 841 MRR_ObjDistXStd_20 "Standard Deviation Of Distance X";
BA_ "SysSignalName" SG_ 841 MRR_ObjDistXStd_20 "MRR_ObjDistXStd_20";
BA_ "CompuMethodName" SG_ 841 MRR_ObjRelVelXStd_20 "MRR_ObjRelVelXStd_20";
BA_ "ISignalName" SG_ 841 MRR_ObjRelVelXStd_20 "IMRR_ObjRelVelXStd_20";
BA_ "LongName" SG_ 841 MRR_ObjRelVelXStd_20 "Standard Deviation Of Relative Velocity X";
BA_ "SysSignalName" SG_ 841 MRR_ObjRelVelXStd_20 "MRR_ObjRelVelXStd_20";
BA_ "CompuMethodName" SG_ 841 MRR_ObjRelVelYStd_20 "MRR_ObjRelVelYStd_20";
BA_ "ISignalName" SG_ 841 MRR_ObjRelVelYStd_20 "IMRR_ObjRelVelYStd_20";
BA_ "LongName" SG_ 841 MRR_ObjRelVelYStd_20 "Standard Deviation Of Relative Velocity Y";
BA_ "SysSignalName" SG_ 841 MRR_ObjRelVelYStd_20 "MRR_ObjRelVelYStd_20";
BA_ "CompuMethodName" SG_ 841 MRR_ObjRAccelYStd_20 "MRR_ObjRAccelYStd_20";
BA_ "ISignalName" SG_ 841 MRR_ObjRAccelYStd_20 "IMRR_ObjRAccelYStd_20";
BA_ "LongName" SG_ 841 MRR_ObjRAccelYStd_20 "Standard Deviation Of Relative Acceleration Y";
BA_ "SysSignalName" SG_ 841 MRR_ObjRAccelYStd_20 "MRR_ObjRAccelYStd_20";
BA_ "CompuMethodName" SG_ 841 MRR_ObjRAccelXStd_20 "MRR_ObjRAccelXStd_20";
BA_ "ISignalName" SG_ 841 MRR_ObjRAccelXStd_20 "IMRR_ObjRAccelXStd_20";
BA_ "LongName" SG_ 841 MRR_ObjRAccelXStd_20 "Standard Deviation Of Relative Acceleration X";
BA_ "SysSignalName" SG_ 841 MRR_ObjRAccelXStd_20 "MRR_ObjRAccelXStd_20";
BA_ "CompuMethodName" SG_ 841 MRR_ObjFolSts_20 "MRR_ObjFolSts_20";
BA_ "ISignalName" SG_ 841 MRR_ObjFolSts_20 "IMRR_ObjFolSts_20";
BA_ "LongName" SG_ 841 MRR_ObjFolSts_20 "Object tracking status";
BA_ "SysSignalName" SG_ 841 MRR_ObjFolSts_20 "MRR_ObjFolSts_20";
BA_ "CompuMethodName" SG_ 841 MRR_ObjFusionSig_20 "MRR_ObjFusionSig_20";
BA_ "ISignalName" SG_ 841 MRR_ObjFusionSig_20 "IMRR_ObjFusionSig_20";
BA_ "LongName" SG_ 841 MRR_ObjFusionSig_20 "Signal To Indicate Fusion With Camera Or Not";
BA_ "SysSignalName" SG_ 841 MRR_ObjFusionSig_20 "MRR_ObjFusionSig_20";
BA_ "CompuMethodName" SG_ 841 MRR_ObjFusionCamID_20 "MRR_ObjFusionCamID_20";
BA_ "ISignalName" SG_ 841 MRR_ObjFusionCamID_20 "IMRR_ObjFusionCamID_20";
BA_ "LongName" SG_ 841 MRR_ObjFusionCamID_20 "Camera Object Id";
BA_ "SysSignalName" SG_ 841 MRR_ObjFusionCamID_20 "MRR_ObjFusionCamID_20";
BA_ "CompuMethodName" SG_ 841 MRR_ObjMovingSts_20 "MRR_ObjMovingSts_20";
BA_ "ISignalName" SG_ 841 MRR_ObjMovingSts_20 "IMRR_ObjMovingSts_20";
BA_ "LongName" SG_ 841 MRR_ObjMovingSts_20 "Object Moving Status";
BA_ "SysSignalName" SG_ 841 MRR_ObjMovingSts_20 "MRR_ObjMovingSts_20";
BA_ "CompuMethodName" SG_ 842 MRR_Obj_CRC16Checksum_21 "MRR_Obj_CRC16Checksum_21";
BA_ "ISignalName" SG_ 842 MRR_Obj_CRC16Checksum_21 "IMRR_Obj_CRC16Checksum_21";
BA_ "LongName" SG_ 842 MRR_Obj_CRC16Checksum_21 "CRC80byte";
BA_ "SysSignalName" SG_ 842 MRR_Obj_CRC16Checksum_21 "MRR_Obj_CRC16Checksum_21";
BA_ "CompuMethodName" SG_ 842 MRR_Obj_MsgCounter_21 "MRR_Obj_MsgCounter_21";
BA_ "ISignalName" SG_ 842 MRR_Obj_MsgCounter_21 "IMRR_Obj_MsgCounter_21";
BA_ "LongName" SG_ 842 MRR_Obj_MsgCounter_21 "Alive counter 1byte4bit";
BA_ "SysSignalName" SG_ 842 MRR_Obj_MsgCounter_21 "MRR_Obj_MsgCounter_21";
BA_ "CompuMethodName" SG_ 842 MRR_ObjMovingSts_21 "MRR_ObjMovingSts_21";
BA_ "ISignalName" SG_ 842 MRR_ObjMovingSts_21 "IMRR_ObjMovingSts_21";
BA_ "LongName" SG_ 842 MRR_ObjMovingSts_21 "Object Moving Status";
BA_ "SysSignalName" SG_ 842 MRR_ObjMovingSts_21 "MRR_ObjMovingSts_21";
BA_ "CompuMethodName" SG_ 842 MRR_ObjID_21 "MRR_ObjID_21";
BA_ "ISignalName" SG_ 842 MRR_ObjID_21 "IMRR_ObjID_21";
BA_ "LongName" SG_ 842 MRR_ObjID_21 "Id Is An Identifier Number That Allows For Tracking Of Persistent Objects Over Time";
BA_ "SysSignalName" SG_ 842 MRR_ObjID_21 "MRR_ObjID_21";
BA_ "CompuMethodName" SG_ 842 MRR_ObjObstacleProb_21 "MRR_ObjObstacleProb_21";
BA_ "ISignalName" SG_ 842 MRR_ObjObstacleProb_21 "IMRR_ObjObstacleProb_21";
BA_ "LongName" SG_ 842 MRR_ObjObstacleProb_21 "The Probability Of An Object Being An Obstacle";
BA_ "SysSignalName" SG_ 842 MRR_ObjObstacleProb_21 "MRR_ObjObstacleProb_21";
BA_ "CompuMethodName" SG_ 842 MRR_ObjExistProb_21 "MRR_ObjExistProb_21";
BA_ "ISignalName" SG_ 842 MRR_ObjExistProb_21 "IMRR_ObjExistProb_21";
BA_ "LongName" SG_ 842 MRR_ObjExistProb_21 "The Probability Of An Object To Exist In Reality";
BA_ "SysSignalName" SG_ 842 MRR_ObjExistProb_21 "MRR_ObjExistProb_21";
BA_ "CompuMethodName" SG_ 842 MRR_ObjDistY_21 "MRR_ObjDistY_21";
BA_ "ISignalName" SG_ 842 MRR_ObjDistY_21 "IMRR_ObjDistY_21";
BA_ "LongName" SG_ 842 MRR_ObjDistY_21 "Position Of Target Vehicle In Y Direction";
BA_ "SysSignalName" SG_ 842 MRR_ObjDistY_21 "MRR_ObjDistY_21";
BA_ "CompuMethodName" SG_ 842 MRR_ObjDistX_21 "MRR_ObjDistX_21";
BA_ "ISignalName" SG_ 842 MRR_ObjDistX_21 "IMRR_ObjDistX_21";
BA_ "LongName" SG_ 842 MRR_ObjDistX_21 "Position Of Target Vehicle In X Direction";
BA_ "SysSignalName" SG_ 842 MRR_ObjDistX_21 "MRR_ObjDistX_21";
BA_ "CompuMethodName" SG_ 842 MRR_ObjType_21 "MRR_ObjType_21";
BA_ "ISignalName" SG_ 842 MRR_ObjType_21 "IMRR_ObjType_21";
BA_ "LongName" SG_ 842 MRR_ObjType_21 "Class Of Object Type";
BA_ "SysSignalName" SG_ 842 MRR_ObjType_21 "MRR_ObjType_21";
BA_ "CompuMethodName" SG_ 842 MRR_ObjRelVelX_21 "MRR_ObjRelVelX_21";
BA_ "ISignalName" SG_ 842 MRR_ObjRelVelX_21 "IMRR_ObjRelVelX_21";
BA_ "LongName" SG_ 842 MRR_ObjRelVelX_21 "Relative Target Object Velocity In X Direction";
BA_ "SysSignalName" SG_ 842 MRR_ObjRelVelX_21 "MRR_ObjRelVelX_21";
BA_ "CompuMethodName" SG_ 842 MRR_ObjAccelX_21 "MRR_ObjAccelX_21";
BA_ "ISignalName" SG_ 842 MRR_ObjAccelX_21 "IMRR_ObjAccelX_21";
BA_ "LongName" SG_ 842 MRR_ObjAccelX_21 "Relative Target Object Acceleration In X Direction";
BA_ "SysSignalName" SG_ 842 MRR_ObjAccelX_21 "MRR_ObjAccelX_21";
BA_ "CompuMethodName" SG_ 842 MRR_ObjRelVelY_21 "MRR_ObjRelVelY_21";
BA_ "ISignalName" SG_ 842 MRR_ObjRelVelY_21 "IMRR_ObjRelVelY_21";
BA_ "LongName" SG_ 842 MRR_ObjRelVelY_21 "Relative Target Object Velocity In Y Direction";
BA_ "SysSignalName" SG_ 842 MRR_ObjRelVelY_21 "MRR_ObjRelVelY_21";
BA_ "CompuMethodName" SG_ 842 MRR_ObjAccelY_21 "MRR_ObjAccelY_21";
BA_ "ISignalName" SG_ 842 MRR_ObjAccelY_21 "IMRR_ObjAccelY_21";
BA_ "LongName" SG_ 842 MRR_ObjAccelY_21 "Relative Target Object Acceleration In Y Direction";
BA_ "SysSignalName" SG_ 842 MRR_ObjAccelY_21 "MRR_ObjAccelY_21";
BA_ "CompuMethodName" SG_ 842 MRR_ObjDistYStd_21 "MRR_ObjDistYStd_21";
BA_ "ISignalName" SG_ 842 MRR_ObjDistYStd_21 "IMRR_ObjDistYStd_21";
BA_ "LongName" SG_ 842 MRR_ObjDistYStd_21 "Standard Deviation Of Distance Y";
BA_ "SysSignalName" SG_ 842 MRR_ObjDistYStd_21 "MRR_ObjDistYStd_21";
BA_ "CompuMethodName" SG_ 842 MRR_ObjDistXStd_21 "MRR_ObjDistXStd_21";
BA_ "ISignalName" SG_ 842 MRR_ObjDistXStd_21 "IMRR_ObjDistXStd_21";
BA_ "LongName" SG_ 842 MRR_ObjDistXStd_21 "Standard Deviation Of Distance X";
BA_ "SysSignalName" SG_ 842 MRR_ObjDistXStd_21 "MRR_ObjDistXStd_21";
BA_ "CompuMethodName" SG_ 842 MRR_ObjRelVelXStd_21 "MRR_ObjRelVelXStd_21";
BA_ "ISignalName" SG_ 842 MRR_ObjRelVelXStd_21 "IMRR_ObjRelVelXStd_21";
BA_ "LongName" SG_ 842 MRR_ObjRelVelXStd_21 "Standard Deviation Of Relative Velocity X";
BA_ "SysSignalName" SG_ 842 MRR_ObjRelVelXStd_21 "MRR_ObjRelVelXStd_21";
BA_ "CompuMethodName" SG_ 842 MRR_ObjRelVelYStd_21 "MRR_ObjRelVelYStd_21";
BA_ "ISignalName" SG_ 842 MRR_ObjRelVelYStd_21 "IMRR_ObjRelVelYStd_21";
BA_ "LongName" SG_ 842 MRR_ObjRelVelYStd_21 "Standard Deviation Of Relative Velocity Y";
BA_ "SysSignalName" SG_ 842 MRR_ObjRelVelYStd_21 "MRR_ObjRelVelYStd_21";
BA_ "CompuMethodName" SG_ 842 MRR_ObjRAccelYStd_21 "MRR_ObjRAccelYStd_21";
BA_ "ISignalName" SG_ 842 MRR_ObjRAccelYStd_21 "IMRR_ObjRAccelYStd_21";
BA_ "LongName" SG_ 842 MRR_ObjRAccelYStd_21 "Standard Deviation Of Relative Acceleration Y";
BA_ "SysSignalName" SG_ 842 MRR_ObjRAccelYStd_21 "MRR_ObjRAccelYStd_21";
BA_ "CompuMethodName" SG_ 842 MRR_ObjRAccelXStd_21 "MRR_ObjRAccelXStd_21";
BA_ "ISignalName" SG_ 842 MRR_ObjRAccelXStd_21 "IMRR_ObjRAccelXStd_21";
BA_ "LongName" SG_ 842 MRR_ObjRAccelXStd_21 "Standard Deviation Of Relative Acceleration X";
BA_ "SysSignalName" SG_ 842 MRR_ObjRAccelXStd_21 "MRR_ObjRAccelXStd_21";
BA_ "CompuMethodName" SG_ 842 MRR_ObjFolSts_21 "MRR_ObjFolSts_21";
BA_ "ISignalName" SG_ 842 MRR_ObjFolSts_21 "IMRR_ObjFolSts_21";
BA_ "LongName" SG_ 842 MRR_ObjFolSts_21 "Object tracking status";
BA_ "SysSignalName" SG_ 842 MRR_ObjFolSts_21 "MRR_ObjFolSts_21";
BA_ "CompuMethodName" SG_ 842 MRR_ObjFusionSig_21 "MRR_ObjFusionSig_21";
BA_ "ISignalName" SG_ 842 MRR_ObjFusionSig_21 "IMRR_ObjFusionSig_21";
BA_ "LongName" SG_ 842 MRR_ObjFusionSig_21 "Signal To Indicate Fusion With Camera Or Not";
BA_ "SysSignalName" SG_ 842 MRR_ObjFusionSig_21 "MRR_ObjFusionSig_21";
BA_ "CompuMethodName" SG_ 842 MRR_ObjFusionCamID_21 "MRR_ObjFusionCamID_21";
BA_ "ISignalName" SG_ 842 MRR_ObjFusionCamID_21 "IMRR_ObjFusionCamID_21";
BA_ "LongName" SG_ 842 MRR_ObjFusionCamID_21 "Camera Object Id";
BA_ "SysSignalName" SG_ 842 MRR_ObjFusionCamID_21 "MRR_ObjFusionCamID_21";
BA_ "CompuMethodName" SG_ 842 MRR_Obj_CRC16Checksum_22 "MRR_Obj_CRC16Checksum_22";
BA_ "ISignalName" SG_ 842 MRR_Obj_CRC16Checksum_22 "IMRR_Obj_CRC16Checksum_22";
BA_ "LongName" SG_ 842 MRR_Obj_CRC16Checksum_22 "CRC80byte";
BA_ "SysSignalName" SG_ 842 MRR_Obj_CRC16Checksum_22 "MRR_Obj_CRC16Checksum_22";
BA_ "CompuMethodName" SG_ 842 MRR_Obj_MsgCounter_22 "MRR_Obj_MsgCounter_22";
BA_ "ISignalName" SG_ 842 MRR_Obj_MsgCounter_22 "IMRR_Obj_MsgCounter_22";
BA_ "LongName" SG_ 842 MRR_Obj_MsgCounter_22 "Alive counter 1byte4bit";
BA_ "SysSignalName" SG_ 842 MRR_Obj_MsgCounter_22 "MRR_Obj_MsgCounter_22";
BA_ "CompuMethodName" SG_ 842 MRR_ObjID_22 "MRR_ObjID_22";
BA_ "ISignalName" SG_ 842 MRR_ObjID_22 "IMRR_ObjID_22";
BA_ "LongName" SG_ 842 MRR_ObjID_22 "Id Is An Identifier Number That Allows For Tracking Of Persistent Objects Over Time";
BA_ "SysSignalName" SG_ 842 MRR_ObjID_22 "MRR_ObjID_22";
BA_ "CompuMethodName" SG_ 842 MRR_ObjObstacleProb_22 "MRR_ObjObstacleProb_22";
BA_ "ISignalName" SG_ 842 MRR_ObjObstacleProb_22 "IMRR_ObjObstacleProb_22";
BA_ "LongName" SG_ 842 MRR_ObjObstacleProb_22 "The Probability Of An Object Being An Obstacle";
BA_ "SysSignalName" SG_ 842 MRR_ObjObstacleProb_22 "MRR_ObjObstacleProb_22";
BA_ "CompuMethodName" SG_ 842 MRR_ObjExistProb_22 "MRR_ObjExistProb_22";
BA_ "ISignalName" SG_ 842 MRR_ObjExistProb_22 "IMRR_ObjExistProb_22";
BA_ "LongName" SG_ 842 MRR_ObjExistProb_22 "The Probability Of An Object To Exist In Reality";
BA_ "SysSignalName" SG_ 842 MRR_ObjExistProb_22 "MRR_ObjExistProb_22";
BA_ "CompuMethodName" SG_ 842 MRR_ObjDistY_22 "MRR_ObjDistY_22";
BA_ "ISignalName" SG_ 842 MRR_ObjDistY_22 "IMRR_ObjDistY_22";
BA_ "LongName" SG_ 842 MRR_ObjDistY_22 "Position Of Target Vehicle In Y Direction";
BA_ "SysSignalName" SG_ 842 MRR_ObjDistY_22 "MRR_ObjDistY_22";
BA_ "CompuMethodName" SG_ 842 MRR_ObjDistX_22 "MRR_ObjDistX_22";
BA_ "ISignalName" SG_ 842 MRR_ObjDistX_22 "IMRR_ObjDistX_22";
BA_ "LongName" SG_ 842 MRR_ObjDistX_22 "Position Of Target Vehicle In X Direction";
BA_ "SysSignalName" SG_ 842 MRR_ObjDistX_22 "MRR_ObjDistX_22";
BA_ "CompuMethodName" SG_ 842 MRR_ObjType_22 "MRR_ObjType_22";
BA_ "ISignalName" SG_ 842 MRR_ObjType_22 "IMRR_ObjType_22";
BA_ "LongName" SG_ 842 MRR_ObjType_22 "Class Of Object Type";
BA_ "SysSignalName" SG_ 842 MRR_ObjType_22 "MRR_ObjType_22";
BA_ "CompuMethodName" SG_ 842 MRR_ObjRelVelX_22 "MRR_ObjRelVelX_22";
BA_ "ISignalName" SG_ 842 MRR_ObjRelVelX_22 "IMRR_ObjRelVelX_22";
BA_ "LongName" SG_ 842 MRR_ObjRelVelX_22 "Relative Target Object Velocity In X Direction";
BA_ "SysSignalName" SG_ 842 MRR_ObjRelVelX_22 "MRR_ObjRelVelX_22";
BA_ "CompuMethodName" SG_ 842 MRR_ObjAccelX_22 "MRR_ObjAccelX_22";
BA_ "ISignalName" SG_ 842 MRR_ObjAccelX_22 "IMRR_ObjAccelX_22";
BA_ "LongName" SG_ 842 MRR_ObjAccelX_22 "Relative Target Object Acceleration In X Direction";
BA_ "SysSignalName" SG_ 842 MRR_ObjAccelX_22 "MRR_ObjAccelX_22";
BA_ "CompuMethodName" SG_ 842 MRR_ObjRelVelY_22 "MRR_ObjRelVelY_22";
BA_ "ISignalName" SG_ 842 MRR_ObjRelVelY_22 "IMRR_ObjRelVelY_22";
BA_ "LongName" SG_ 842 MRR_ObjRelVelY_22 "Relative Target Object Velocity In Y Direction";
BA_ "SysSignalName" SG_ 842 MRR_ObjRelVelY_22 "MRR_ObjRelVelY_22";
BA_ "CompuMethodName" SG_ 842 MRR_ObjAccelY_22 "MRR_ObjAccelY_22";
BA_ "ISignalName" SG_ 842 MRR_ObjAccelY_22 "IMRR_ObjAccelY_22";
BA_ "LongName" SG_ 842 MRR_ObjAccelY_22 "Relative Target Object Acceleration In Y Direction";
BA_ "SysSignalName" SG_ 842 MRR_ObjAccelY_22 "MRR_ObjAccelY_22";
BA_ "CompuMethodName" SG_ 842 MRR_ObjDistYStd_22 "MRR_ObjDistYStd_22";
BA_ "ISignalName" SG_ 842 MRR_ObjDistYStd_22 "IMRR_ObjDistYStd_22";
BA_ "LongName" SG_ 842 MRR_ObjDistYStd_22 "Standard Deviation Of Distance Y";
BA_ "SysSignalName" SG_ 842 MRR_ObjDistYStd_22 "MRR_ObjDistYStd_22";
BA_ "CompuMethodName" SG_ 842 MRR_ObjDistXStd_22 "MRR_ObjDistXStd_22";
BA_ "ISignalName" SG_ 842 MRR_ObjDistXStd_22 "IMRR_ObjDistXStd_22";
BA_ "LongName" SG_ 842 MRR_ObjDistXStd_22 "Standard Deviation Of Distance X";
BA_ "SysSignalName" SG_ 842 MRR_ObjDistXStd_22 "MRR_ObjDistXStd_22";
BA_ "CompuMethodName" SG_ 842 MRR_ObjRelVelXStd_22 "MRR_ObjRelVelXStd_22";
BA_ "ISignalName" SG_ 842 MRR_ObjRelVelXStd_22 "IMRR_ObjRelVelXStd_22";
BA_ "LongName" SG_ 842 MRR_ObjRelVelXStd_22 "Standard Deviation Of Relative Velocity X";
BA_ "SysSignalName" SG_ 842 MRR_ObjRelVelXStd_22 "MRR_ObjRelVelXStd_22";
BA_ "CompuMethodName" SG_ 842 MRR_ObjRelVelYStd_22 "MRR_ObjRelVelYStd_22";
BA_ "ISignalName" SG_ 842 MRR_ObjRelVelYStd_22 "IMRR_ObjRelVelYStd_22";
BA_ "LongName" SG_ 842 MRR_ObjRelVelYStd_22 "Standard Deviation Of Relative Velocity Y";
BA_ "SysSignalName" SG_ 842 MRR_ObjRelVelYStd_22 "MRR_ObjRelVelYStd_22";
BA_ "CompuMethodName" SG_ 842 MRR_ObjRAccelYStd_22 "MRR_ObjRAccelYStd_22";
BA_ "ISignalName" SG_ 842 MRR_ObjRAccelYStd_22 "IMRR_ObjRAccelYStd_22";
BA_ "LongName" SG_ 842 MRR_ObjRAccelYStd_22 "Standard Deviation Of Relative Acceleration Y";
BA_ "SysSignalName" SG_ 842 MRR_ObjRAccelYStd_22 "MRR_ObjRAccelYStd_22";
BA_ "CompuMethodName" SG_ 842 MRR_ObjRAccelXStd_22 "MRR_ObjRAccelXStd_22";
BA_ "ISignalName" SG_ 842 MRR_ObjRAccelXStd_22 "IMRR_ObjRAccelXStd_22";
BA_ "LongName" SG_ 842 MRR_ObjRAccelXStd_22 "Standard Deviation Of Relative Acceleration X";
BA_ "SysSignalName" SG_ 842 MRR_ObjRAccelXStd_22 "MRR_ObjRAccelXStd_22";
BA_ "CompuMethodName" SG_ 842 MRR_ObjFolSts_22 "MRR_ObjFolSts_22";
BA_ "ISignalName" SG_ 842 MRR_ObjFolSts_22 "IMRR_ObjFolSts_22";
BA_ "LongName" SG_ 842 MRR_ObjFolSts_22 "Object tracking status";
BA_ "SysSignalName" SG_ 842 MRR_ObjFolSts_22 "MRR_ObjFolSts_22";
BA_ "CompuMethodName" SG_ 842 MRR_ObjFusionSig_22 "MRR_ObjFusionSig_22";
BA_ "ISignalName" SG_ 842 MRR_ObjFusionSig_22 "IMRR_ObjFusionSig_22";
BA_ "LongName" SG_ 842 MRR_ObjFusionSig_22 "Signal To Indicate Fusion With Camera Or Not";
BA_ "SysSignalName" SG_ 842 MRR_ObjFusionSig_22 "MRR_ObjFusionSig_22";
BA_ "CompuMethodName" SG_ 842 MRR_ObjFusionCamID_22 "MRR_ObjFusionCamID_22";
BA_ "ISignalName" SG_ 842 MRR_ObjFusionCamID_22 "IMRR_ObjFusionCamID_22";
BA_ "LongName" SG_ 842 MRR_ObjFusionCamID_22 "Camera Object Id";
BA_ "SysSignalName" SG_ 842 MRR_ObjFusionCamID_22 "MRR_ObjFusionCamID_22";
BA_ "CompuMethodName" SG_ 842 MRR_ObjMovingSts_22 "MRR_ObjMovingSts_22";
BA_ "ISignalName" SG_ 842 MRR_ObjMovingSts_22 "IMRR_ObjMovingSts_22";
BA_ "LongName" SG_ 842 MRR_ObjMovingSts_22 "Object Moving Status";
BA_ "SysSignalName" SG_ 842 MRR_ObjMovingSts_22 "MRR_ObjMovingSts_22";
BA_ "CompuMethodName" SG_ 843 MRR_Obj_CRC16Checksum_23 "MRR_Obj_CRC16Checksum_23";
BA_ "ISignalName" SG_ 843 MRR_Obj_CRC16Checksum_23 "IMRR_Obj_CRC16Checksum_23";
BA_ "LongName" SG_ 843 MRR_Obj_CRC16Checksum_23 "CRC80byte";
BA_ "SysSignalName" SG_ 843 MRR_Obj_CRC16Checksum_23 "MRR_Obj_CRC16Checksum_23";
BA_ "CompuMethodName" SG_ 843 MRR_Obj_MsgCounter_23 "MRR_Obj_MsgCounter_23";
BA_ "ISignalName" SG_ 843 MRR_Obj_MsgCounter_23 "IMRR_Obj_MsgCounter_23";
BA_ "LongName" SG_ 843 MRR_Obj_MsgCounter_23 "Alive counter 1byte4bit";
BA_ "SysSignalName" SG_ 843 MRR_Obj_MsgCounter_23 "MRR_Obj_MsgCounter_23";
BA_ "CompuMethodName" SG_ 843 MRR_ObjMovingSts_23 "MRR_ObjMovingSts_23";
BA_ "ISignalName" SG_ 843 MRR_ObjMovingSts_23 "IMRR_ObjMovingSts_23";
BA_ "LongName" SG_ 843 MRR_ObjMovingSts_23 "Object Moving Status";
BA_ "SysSignalName" SG_ 843 MRR_ObjMovingSts_23 "MRR_ObjMovingSts_23";
BA_ "CompuMethodName" SG_ 843 MRR_ObjID_23 "MRR_ObjID_23";
BA_ "ISignalName" SG_ 843 MRR_ObjID_23 "IMRR_ObjID_23";
BA_ "LongName" SG_ 843 MRR_ObjID_23 "Id Is An Identifier Number That Allows For Tracking Of Persistent Objects Over Time";
BA_ "SysSignalName" SG_ 843 MRR_ObjID_23 "MRR_ObjID_23";
BA_ "CompuMethodName" SG_ 843 MRR_ObjObstacleProb_23 "MRR_ObjObstacleProb_23";
BA_ "ISignalName" SG_ 843 MRR_ObjObstacleProb_23 "IMRR_ObjObstacleProb_23";
BA_ "LongName" SG_ 843 MRR_ObjObstacleProb_23 "The Probability Of An Object Being An Obstacle";
BA_ "SysSignalName" SG_ 843 MRR_ObjObstacleProb_23 "MRR_ObjObstacleProb_23";
BA_ "CompuMethodName" SG_ 843 MRR_ObjExistProb_23 "MRR_ObjExistProb_23";
BA_ "ISignalName" SG_ 843 MRR_ObjExistProb_23 "IMRR_ObjExistProb_23";
BA_ "LongName" SG_ 843 MRR_ObjExistProb_23 "The Probability Of An Object To Exist In Reality";
BA_ "SysSignalName" SG_ 843 MRR_ObjExistProb_23 "MRR_ObjExistProb_23";
BA_ "CompuMethodName" SG_ 843 MRR_ObjDistY_23 "MRR_ObjDistY_23";
BA_ "ISignalName" SG_ 843 MRR_ObjDistY_23 "IMRR_ObjDistY_23";
BA_ "LongName" SG_ 843 MRR_ObjDistY_23 "Position Of Target Vehicle In Y Direction";
BA_ "SysSignalName" SG_ 843 MRR_ObjDistY_23 "MRR_ObjDistY_23";
BA_ "CompuMethodName" SG_ 843 MRR_ObjDistX_23 "MRR_ObjDistX_23";
BA_ "ISignalName" SG_ 843 MRR_ObjDistX_23 "IMRR_ObjDistX_23";
BA_ "LongName" SG_ 843 MRR_ObjDistX_23 "Position Of Target Vehicle In X Direction";
BA_ "SysSignalName" SG_ 843 MRR_ObjDistX_23 "MRR_ObjDistX_23";
BA_ "CompuMethodName" SG_ 843 MRR_ObjType_23 "MRR_ObjType_23";
BA_ "ISignalName" SG_ 843 MRR_ObjType_23 "IMRR_ObjType_23";
BA_ "LongName" SG_ 843 MRR_ObjType_23 "Class Of Object Type";
BA_ "SysSignalName" SG_ 843 MRR_ObjType_23 "MRR_ObjType_23";
BA_ "CompuMethodName" SG_ 843 MRR_ObjRelVelX_23 "MRR_ObjRelVelX_23";
BA_ "ISignalName" SG_ 843 MRR_ObjRelVelX_23 "IMRR_ObjRelVelX_23";
BA_ "LongName" SG_ 843 MRR_ObjRelVelX_23 "Relative Target Object Velocity In X Direction";
BA_ "SysSignalName" SG_ 843 MRR_ObjRelVelX_23 "MRR_ObjRelVelX_23";
BA_ "CompuMethodName" SG_ 843 MRR_ObjAccelX_23 "MRR_ObjAccelX_23";
BA_ "ISignalName" SG_ 843 MRR_ObjAccelX_23 "IMRR_ObjAccelX_23";
BA_ "LongName" SG_ 843 MRR_ObjAccelX_23 "Relative Target Object Acceleration In X Direction";
BA_ "SysSignalName" SG_ 843 MRR_ObjAccelX_23 "MRR_ObjAccelX_23";
BA_ "CompuMethodName" SG_ 843 MRR_ObjRelVelY_23 "MRR_ObjRelVelY_23";
BA_ "ISignalName" SG_ 843 MRR_ObjRelVelY_23 "IMRR_ObjRelVelY_23";
BA_ "LongName" SG_ 843 MRR_ObjRelVelY_23 "Relative Target Object Velocity In Y Direction";
BA_ "SysSignalName" SG_ 843 MRR_ObjRelVelY_23 "MRR_ObjRelVelY_23";
BA_ "CompuMethodName" SG_ 843 MRR_ObjAccelY_23 "MRR_ObjAccelY_23";
BA_ "ISignalName" SG_ 843 MRR_ObjAccelY_23 "IMRR_ObjAccelY_23";
BA_ "LongName" SG_ 843 MRR_ObjAccelY_23 "Relative Target Object Acceleration In Y Direction";
BA_ "SysSignalName" SG_ 843 MRR_ObjAccelY_23 "MRR_ObjAccelY_23";
BA_ "CompuMethodName" SG_ 843 MRR_ObjDistYStd_23 "MRR_ObjDistYStd_23";
BA_ "ISignalName" SG_ 843 MRR_ObjDistYStd_23 "IMRR_ObjDistYStd_23";
BA_ "LongName" SG_ 843 MRR_ObjDistYStd_23 "Standard Deviation Of Distance Y";
BA_ "SysSignalName" SG_ 843 MRR_ObjDistYStd_23 "MRR_ObjDistYStd_23";
BA_ "CompuMethodName" SG_ 843 MRR_ObjDistXStd_23 "MRR_ObjDistXStd_23";
BA_ "ISignalName" SG_ 843 MRR_ObjDistXStd_23 "IMRR_ObjDistXStd_23";
BA_ "LongName" SG_ 843 MRR_ObjDistXStd_23 "Standard Deviation Of Distance X";
BA_ "SysSignalName" SG_ 843 MRR_ObjDistXStd_23 "MRR_ObjDistXStd_23";
BA_ "CompuMethodName" SG_ 843 MRR_ObjRelVelXStd_23 "MRR_ObjRelVelXStd_23";
BA_ "ISignalName" SG_ 843 MRR_ObjRelVelXStd_23 "IMRR_ObjRelVelXStd_23";
BA_ "LongName" SG_ 843 MRR_ObjRelVelXStd_23 "Standard Deviation Of Relative Velocity X";
BA_ "SysSignalName" SG_ 843 MRR_ObjRelVelXStd_23 "MRR_ObjRelVelXStd_23";
BA_ "CompuMethodName" SG_ 843 MRR_ObjRelVelYStd_23 "MRR_ObjRelVelYStd_23";
BA_ "ISignalName" SG_ 843 MRR_ObjRelVelYStd_23 "IMRR_ObjRelVelYStd_23";
BA_ "LongName" SG_ 843 MRR_ObjRelVelYStd_23 "Standard Deviation Of Relative Velocity Y";
BA_ "SysSignalName" SG_ 843 MRR_ObjRelVelYStd_23 "MRR_ObjRelVelYStd_23";
BA_ "CompuMethodName" SG_ 843 MRR_ObjRAccelYStd_23 "MRR_ObjRAccelYStd_23";
BA_ "ISignalName" SG_ 843 MRR_ObjRAccelYStd_23 "IMRR_ObjRAccelYStd_23";
BA_ "LongName" SG_ 843 MRR_ObjRAccelYStd_23 "Standard Deviation Of Relative Acceleration Y";
BA_ "SysSignalName" SG_ 843 MRR_ObjRAccelYStd_23 "MRR_ObjRAccelYStd_23";
BA_ "CompuMethodName" SG_ 843 MRR_ObjRAccelXStd_23 "MRR_ObjRAccelXStd_23";
BA_ "ISignalName" SG_ 843 MRR_ObjRAccelXStd_23 "IMRR_ObjRAccelXStd_23";
BA_ "LongName" SG_ 843 MRR_ObjRAccelXStd_23 "Standard Deviation Of Relative Acceleration X";
BA_ "SysSignalName" SG_ 843 MRR_ObjRAccelXStd_23 "MRR_ObjRAccelXStd_23";
BA_ "CompuMethodName" SG_ 843 MRR_ObjFolSts_23 "MRR_ObjFolSts_23";
BA_ "ISignalName" SG_ 843 MRR_ObjFolSts_23 "IMRR_ObjFolSts_23";
BA_ "LongName" SG_ 843 MRR_ObjFolSts_23 "Object tracking status";
BA_ "SysSignalName" SG_ 843 MRR_ObjFolSts_23 "MRR_ObjFolSts_23";
BA_ "CompuMethodName" SG_ 843 MRR_ObjFusionSig_23 "MRR_ObjFusionSig_23";
BA_ "ISignalName" SG_ 843 MRR_ObjFusionSig_23 "IMRR_ObjFusionSig_23";
BA_ "LongName" SG_ 843 MRR_ObjFusionSig_23 "Signal To Indicate Fusion With Camera Or Not";
BA_ "SysSignalName" SG_ 843 MRR_ObjFusionSig_23 "MRR_ObjFusionSig_23";
BA_ "CompuMethodName" SG_ 843 MRR_ObjFusionCamID_23 "MRR_ObjFusionCamID_23";
BA_ "ISignalName" SG_ 843 MRR_ObjFusionCamID_23 "IMRR_ObjFusionCamID_23";
BA_ "LongName" SG_ 843 MRR_ObjFusionCamID_23 "Camera Object Id";
BA_ "SysSignalName" SG_ 843 MRR_ObjFusionCamID_23 "MRR_ObjFusionCamID_23";
BA_ "CompuMethodName" SG_ 843 MRR_Obj_CRC16Checksum_24 "MRR_Obj_CRC16Checksum_24";
BA_ "ISignalName" SG_ 843 MRR_Obj_CRC16Checksum_24 "IMRR_Obj_CRC16Checksum_24";
BA_ "LongName" SG_ 843 MRR_Obj_CRC16Checksum_24 "CRC80byte";
BA_ "SysSignalName" SG_ 843 MRR_Obj_CRC16Checksum_24 "MRR_Obj_CRC16Checksum_24";
BA_ "CompuMethodName" SG_ 843 MRR_Obj_MsgCounter_24 "MRR_Obj_MsgCounter_24";
BA_ "ISignalName" SG_ 843 MRR_Obj_MsgCounter_24 "IMRR_Obj_MsgCounter_24";
BA_ "LongName" SG_ 843 MRR_Obj_MsgCounter_24 "Alive counter 1byte4bit";
BA_ "SysSignalName" SG_ 843 MRR_Obj_MsgCounter_24 "MRR_Obj_MsgCounter_24";
BA_ "CompuMethodName" SG_ 843 MRR_ObjID_24 "MRR_ObjID_24";
BA_ "ISignalName" SG_ 843 MRR_ObjID_24 "IMRR_ObjID_24";
BA_ "LongName" SG_ 843 MRR_ObjID_24 "Id Is An Identifier Number That Allows For Tracking Of Persistent Objects Over Time";
BA_ "SysSignalName" SG_ 843 MRR_ObjID_24 "MRR_ObjID_24";
BA_ "CompuMethodName" SG_ 843 MRR_ObjObstacleProb_24 "MRR_ObjObstacleProb_24";
BA_ "ISignalName" SG_ 843 MRR_ObjObstacleProb_24 "IMRR_ObjObstacleProb_24";
BA_ "LongName" SG_ 843 MRR_ObjObstacleProb_24 "The Probability Of An Object Being An Obstacle";
BA_ "SysSignalName" SG_ 843 MRR_ObjObstacleProb_24 "MRR_ObjObstacleProb_24";
BA_ "CompuMethodName" SG_ 843 MRR_ObjExistProb_24 "MRR_ObjExistProb_24";
BA_ "ISignalName" SG_ 843 MRR_ObjExistProb_24 "IMRR_ObjExistProb_24";
BA_ "LongName" SG_ 843 MRR_ObjExistProb_24 "The Probability Of An Object To Exist In Reality";
BA_ "SysSignalName" SG_ 843 MRR_ObjExistProb_24 "MRR_ObjExistProb_24";
BA_ "CompuMethodName" SG_ 843 MRR_ObjDistY_24 "MRR_ObjDistY_24";
BA_ "ISignalName" SG_ 843 MRR_ObjDistY_24 "IMRR_ObjDistY_24";
BA_ "LongName" SG_ 843 MRR_ObjDistY_24 "Position Of Target Vehicle In Y Direction";
BA_ "SysSignalName" SG_ 843 MRR_ObjDistY_24 "MRR_ObjDistY_24";
BA_ "CompuMethodName" SG_ 843 MRR_ObjDistX_24 "MRR_ObjDistX_24";
BA_ "ISignalName" SG_ 843 MRR_ObjDistX_24 "IMRR_ObjDistX_24";
BA_ "LongName" SG_ 843 MRR_ObjDistX_24 "Position Of Target Vehicle In X Direction";
BA_ "SysSignalName" SG_ 843 MRR_ObjDistX_24 "MRR_ObjDistX_24";
BA_ "CompuMethodName" SG_ 843 MRR_ObjType_24 "MRR_ObjType_24";
BA_ "ISignalName" SG_ 843 MRR_ObjType_24 "IMRR_ObjType_24";
BA_ "LongName" SG_ 843 MRR_ObjType_24 "Class Of Object Type";
BA_ "SysSignalName" SG_ 843 MRR_ObjType_24 "MRR_ObjType_24";
BA_ "CompuMethodName" SG_ 843 MRR_ObjRelVelX_24 "MRR_ObjRelVelX_24";
BA_ "ISignalName" SG_ 843 MRR_ObjRelVelX_24 "IMRR_ObjRelVelX_24";
BA_ "LongName" SG_ 843 MRR_ObjRelVelX_24 "Relative Target Object Velocity In X Direction";
BA_ "SysSignalName" SG_ 843 MRR_ObjRelVelX_24 "MRR_ObjRelVelX_24";
BA_ "CompuMethodName" SG_ 843 MRR_ObjAccelX_24 "MRR_ObjAccelX_24";
BA_ "ISignalName" SG_ 843 MRR_ObjAccelX_24 "IMRR_ObjAccelX_24";
BA_ "LongName" SG_ 843 MRR_ObjAccelX_24 "Relative Target Object Acceleration In X Direction";
BA_ "SysSignalName" SG_ 843 MRR_ObjAccelX_24 "MRR_ObjAccelX_24";
BA_ "CompuMethodName" SG_ 843 MRR_ObjRelVelY_24 "MRR_ObjRelVelY_24";
BA_ "ISignalName" SG_ 843 MRR_ObjRelVelY_24 "IMRR_ObjRelVelY_24";
BA_ "LongName" SG_ 843 MRR_ObjRelVelY_24 "Relative Target Object Velocity In Y Direction";
BA_ "SysSignalName" SG_ 843 MRR_ObjRelVelY_24 "MRR_ObjRelVelY_24";
BA_ "CompuMethodName" SG_ 843 MRR_ObjAccelY_24 "MRR_ObjAccelY_24";
BA_ "ISignalName" SG_ 843 MRR_ObjAccelY_24 "IMRR_ObjAccelY_24";
BA_ "LongName" SG_ 843 MRR_ObjAccelY_24 "Relative Target Object Acceleration In Y Direction";
BA_ "SysSignalName" SG_ 843 MRR_ObjAccelY_24 "MRR_ObjAccelY_24";
BA_ "CompuMethodName" SG_ 843 MRR_ObjDistYStd_24 "MRR_ObjDistYStd_24";
BA_ "ISignalName" SG_ 843 MRR_ObjDistYStd_24 "IMRR_ObjDistYStd_24";
BA_ "LongName" SG_ 843 MRR_ObjDistYStd_24 "Standard Deviation Of Distance Y";
BA_ "SysSignalName" SG_ 843 MRR_ObjDistYStd_24 "MRR_ObjDistYStd_24";
BA_ "CompuMethodName" SG_ 843 MRR_ObjDistXStd_24 "MRR_ObjDistXStd_24";
BA_ "ISignalName" SG_ 843 MRR_ObjDistXStd_24 "IMRR_ObjDistXStd_24";
BA_ "LongName" SG_ 843 MRR_ObjDistXStd_24 "Standard Deviation Of Distance X";
BA_ "SysSignalName" SG_ 843 MRR_ObjDistXStd_24 "MRR_ObjDistXStd_24";
BA_ "CompuMethodName" SG_ 843 MRR_ObjRelVelXStd_24 "MRR_ObjRelVelXStd_24";
BA_ "ISignalName" SG_ 843 MRR_ObjRelVelXStd_24 "IMRR_ObjRelVelXStd_24";
BA_ "LongName" SG_ 843 MRR_ObjRelVelXStd_24 "Standard Deviation Of Relative Velocity X";
BA_ "SysSignalName" SG_ 843 MRR_ObjRelVelXStd_24 "MRR_ObjRelVelXStd_24";
BA_ "CompuMethodName" SG_ 843 MRR_ObjRelVelYStd_24 "MRR_ObjRelVelYStd_24";
BA_ "ISignalName" SG_ 843 MRR_ObjRelVelYStd_24 "IMRR_ObjRelVelYStd_24";
BA_ "LongName" SG_ 843 MRR_ObjRelVelYStd_24 "Standard Deviation Of Relative Velocity Y";
BA_ "SysSignalName" SG_ 843 MRR_ObjRelVelYStd_24 "MRR_ObjRelVelYStd_24";
BA_ "CompuMethodName" SG_ 843 MRR_ObjRAccelYStd_24 "MRR_ObjRAccelYStd_24";
BA_ "ISignalName" SG_ 843 MRR_ObjRAccelYStd_24 "IMRR_ObjRAccelYStd_24";
BA_ "LongName" SG_ 843 MRR_ObjRAccelYStd_24 "Standard Deviation Of Relative Acceleration Y";
BA_ "SysSignalName" SG_ 843 MRR_ObjRAccelYStd_24 "MRR_ObjRAccelYStd_24";
BA_ "CompuMethodName" SG_ 843 MRR_ObjRAccelXStd_24 "MRR_ObjRAccelXStd_24";
BA_ "ISignalName" SG_ 843 MRR_ObjRAccelXStd_24 "IMRR_ObjRAccelXStd_24";
BA_ "LongName" SG_ 843 MRR_ObjRAccelXStd_24 "Standard Deviation Of Relative Acceleration X";
BA_ "SysSignalName" SG_ 843 MRR_ObjRAccelXStd_24 "MRR_ObjRAccelXStd_24";
BA_ "CompuMethodName" SG_ 843 MRR_ObjFolSts_24 "MRR_ObjFolSts_24";
BA_ "ISignalName" SG_ 843 MRR_ObjFolSts_24 "IMRR_ObjFolSts_24";
BA_ "LongName" SG_ 843 MRR_ObjFolSts_24 "Object tracking status";
BA_ "SysSignalName" SG_ 843 MRR_ObjFolSts_24 "MRR_ObjFolSts_24";
BA_ "CompuMethodName" SG_ 843 MRR_ObjFusionSig_24 "MRR_ObjFusionSig_24";
BA_ "ISignalName" SG_ 843 MRR_ObjFusionSig_24 "IMRR_ObjFusionSig_24";
BA_ "LongName" SG_ 843 MRR_ObjFusionSig_24 "Signal To Indicate Fusion With Camera Or Not";
BA_ "SysSignalName" SG_ 843 MRR_ObjFusionSig_24 "MRR_ObjFusionSig_24";
BA_ "CompuMethodName" SG_ 843 MRR_ObjFusionCamID_24 "MRR_ObjFusionCamID_24";
BA_ "ISignalName" SG_ 843 MRR_ObjFusionCamID_24 "IMRR_ObjFusionCamID_24";
BA_ "LongName" SG_ 843 MRR_ObjFusionCamID_24 "Camera Object Id";
BA_ "SysSignalName" SG_ 843 MRR_ObjFusionCamID_24 "MRR_ObjFusionCamID_24";
BA_ "CompuMethodName" SG_ 843 MRR_ObjMovingSts_24 "MRR_ObjMovingSts_24";
BA_ "ISignalName" SG_ 843 MRR_ObjMovingSts_24 "IMRR_ObjMovingSts_24";
BA_ "LongName" SG_ 843 MRR_ObjMovingSts_24 "Object Moving Status";
BA_ "SysSignalName" SG_ 843 MRR_ObjMovingSts_24 "MRR_ObjMovingSts_24";
BA_ "CompuMethodName" SG_ 844 MRR_Obj_CRC16Checksum_25 "MRR_Obj_CRC16Checksum_25";
BA_ "ISignalName" SG_ 844 MRR_Obj_CRC16Checksum_25 "IMRR_Obj_CRC16Checksum_25";
BA_ "LongName" SG_ 844 MRR_Obj_CRC16Checksum_25 "CRC80byte";
BA_ "SysSignalName" SG_ 844 MRR_Obj_CRC16Checksum_25 "MRR_Obj_CRC16Checksum_25";
BA_ "CompuMethodName" SG_ 844 MRR_Obj_MsgCounter_25 "MRR_Obj_MsgCounter_25";
BA_ "ISignalName" SG_ 844 MRR_Obj_MsgCounter_25 "IMRR_Obj_MsgCounter_25";
BA_ "LongName" SG_ 844 MRR_Obj_MsgCounter_25 "Alive counter 1byte4bit";
BA_ "SysSignalName" SG_ 844 MRR_Obj_MsgCounter_25 "MRR_Obj_MsgCounter_25";
BA_ "CompuMethodName" SG_ 844 MRR_ObjMovingSts_25 "MRR_ObjMovingSts_25";
BA_ "ISignalName" SG_ 844 MRR_ObjMovingSts_25 "IMRR_ObjMovingSts_25";
BA_ "LongName" SG_ 844 MRR_ObjMovingSts_25 "Object Moving Status";
BA_ "SysSignalName" SG_ 844 MRR_ObjMovingSts_25 "MRR_ObjMovingSts_25";
BA_ "CompuMethodName" SG_ 844 MRR_ObjID_25 "MRR_ObjID_25";
BA_ "ISignalName" SG_ 844 MRR_ObjID_25 "IMRR_ObjID_25";
BA_ "LongName" SG_ 844 MRR_ObjID_25 "Id Is An Identifier Number That Allows For Tracking Of Persistent Objects Over Time";
BA_ "SysSignalName" SG_ 844 MRR_ObjID_25 "MRR_ObjID_25";
BA_ "CompuMethodName" SG_ 844 MRR_ObjObstacleProb_25 "MRR_ObjObstacleProb_25";
BA_ "ISignalName" SG_ 844 MRR_ObjObstacleProb_25 "IMRR_ObjObstacleProb_25";
BA_ "LongName" SG_ 844 MRR_ObjObstacleProb_25 "The Probability Of An Object Being An Obstacle";
BA_ "SysSignalName" SG_ 844 MRR_ObjObstacleProb_25 "MRR_ObjObstacleProb_25";
BA_ "CompuMethodName" SG_ 844 MRR_ObjExistProb_25 "MRR_ObjExistProb_25";
BA_ "ISignalName" SG_ 844 MRR_ObjExistProb_25 "IMRR_ObjExistProb_25";
BA_ "LongName" SG_ 844 MRR_ObjExistProb_25 "The Probability Of An Object To Exist In Reality";
BA_ "SysSignalName" SG_ 844 MRR_ObjExistProb_25 "MRR_ObjExistProb_25";
BA_ "CompuMethodName" SG_ 844 MRR_ObjDistY_25 "MRR_ObjDistY_25";
BA_ "ISignalName" SG_ 844 MRR_ObjDistY_25 "IMRR_ObjDistY_25";
BA_ "LongName" SG_ 844 MRR_ObjDistY_25 "Position Of Target Vehicle In Y Direction";
BA_ "SysSignalName" SG_ 844 MRR_ObjDistY_25 "MRR_ObjDistY_25";
BA_ "CompuMethodName" SG_ 844 MRR_ObjDistX_25 "MRR_ObjDistX_25";
BA_ "ISignalName" SG_ 844 MRR_ObjDistX_25 "IMRR_ObjDistX_25";
BA_ "LongName" SG_ 844 MRR_ObjDistX_25 "Position Of Target Vehicle In X Direction";
BA_ "SysSignalName" SG_ 844 MRR_ObjDistX_25 "MRR_ObjDistX_25";
BA_ "CompuMethodName" SG_ 844 MRR_ObjType_25 "MRR_ObjType_25";
BA_ "ISignalName" SG_ 844 MRR_ObjType_25 "IMRR_ObjType_25";
BA_ "LongName" SG_ 844 MRR_ObjType_25 "Class Of Object Type";
BA_ "SysSignalName" SG_ 844 MRR_ObjType_25 "MRR_ObjType_25";
BA_ "CompuMethodName" SG_ 844 MRR_ObjRelVelX_25 "MRR_ObjRelVelX_25";
BA_ "ISignalName" SG_ 844 MRR_ObjRelVelX_25 "IMRR_ObjRelVelX_25";
BA_ "LongName" SG_ 844 MRR_ObjRelVelX_25 "Relative Target Object Velocity In X Direction";
BA_ "SysSignalName" SG_ 844 MRR_ObjRelVelX_25 "MRR_ObjRelVelX_25";
BA_ "CompuMethodName" SG_ 844 MRR_ObjAccelX_25 "MRR_ObjAccelX_25";
BA_ "ISignalName" SG_ 844 MRR_ObjAccelX_25 "IMRR_ObjAccelX_25";
BA_ "LongName" SG_ 844 MRR_ObjAccelX_25 "Relative Target Object Acceleration In X Direction";
BA_ "SysSignalName" SG_ 844 MRR_ObjAccelX_25 "MRR_ObjAccelX_25";
BA_ "CompuMethodName" SG_ 844 MRR_ObjRelVelY_25 "MRR_ObjRelVelY_25";
BA_ "ISignalName" SG_ 844 MRR_ObjRelVelY_25 "IMRR_ObjRelVelY_25";
BA_ "LongName" SG_ 844 MRR_ObjRelVelY_25 "Relative Target Object Velocity In Y Direction";
BA_ "SysSignalName" SG_ 844 MRR_ObjRelVelY_25 "MRR_ObjRelVelY_25";
BA_ "CompuMethodName" SG_ 844 MRR_ObjAccelY_25 "MRR_ObjAccelY_25";
BA_ "ISignalName" SG_ 844 MRR_ObjAccelY_25 "IMRR_ObjAccelY_25";
BA_ "LongName" SG_ 844 MRR_ObjAccelY_25 "Relative Target Object Acceleration In Y Direction";
BA_ "SysSignalName" SG_ 844 MRR_ObjAccelY_25 "MRR_ObjAccelY_25";
BA_ "CompuMethodName" SG_ 844 MRR_ObjDistYStd_25 "MRR_ObjDistYStd_25";
BA_ "ISignalName" SG_ 844 MRR_ObjDistYStd_25 "IMRR_ObjDistYStd_25";
BA_ "LongName" SG_ 844 MRR_ObjDistYStd_25 "Standard Deviation Of Distance Y";
BA_ "SysSignalName" SG_ 844 MRR_ObjDistYStd_25 "MRR_ObjDistYStd_25";
BA_ "CompuMethodName" SG_ 844 MRR_ObjDistXStd_25 "MRR_ObjDistXStd_25";
BA_ "ISignalName" SG_ 844 MRR_ObjDistXStd_25 "IMRR_ObjDistXStd_25";
BA_ "LongName" SG_ 844 MRR_ObjDistXStd_25 "Standard Deviation Of Distance X";
BA_ "SysSignalName" SG_ 844 MRR_ObjDistXStd_25 "MRR_ObjDistXStd_25";
BA_ "CompuMethodName" SG_ 844 MRR_ObjRelVelXStd_25 "MRR_ObjRelVelXStd_25";
BA_ "ISignalName" SG_ 844 MRR_ObjRelVelXStd_25 "IMRR_ObjRelVelXStd_25";
BA_ "LongName" SG_ 844 MRR_ObjRelVelXStd_25 "Standard Deviation Of Relative Velocity X";
BA_ "SysSignalName" SG_ 844 MRR_ObjRelVelXStd_25 "MRR_ObjRelVelXStd_25";
BA_ "CompuMethodName" SG_ 844 MRR_ObjRelVelYStd_25 "MRR_ObjRelVelYStd_25";
BA_ "ISignalName" SG_ 844 MRR_ObjRelVelYStd_25 "IMRR_ObjRelVelYStd_25";
BA_ "LongName" SG_ 844 MRR_ObjRelVelYStd_25 "Standard Deviation Of Relative Velocity Y";
BA_ "SysSignalName" SG_ 844 MRR_ObjRelVelYStd_25 "MRR_ObjRelVelYStd_25";
BA_ "CompuMethodName" SG_ 844 MRR_ObjRAccelYStd_25 "MRR_ObjRAccelYStd_25";
BA_ "ISignalName" SG_ 844 MRR_ObjRAccelYStd_25 "IMRR_ObjRAccelYStd_25";
BA_ "LongName" SG_ 844 MRR_ObjRAccelYStd_25 "Standard Deviation Of Relative Acceleration Y";
BA_ "SysSignalName" SG_ 844 MRR_ObjRAccelYStd_25 "MRR_ObjRAccelYStd_25";
BA_ "CompuMethodName" SG_ 844 MRR_ObjRAccelXStd_25 "MRR_ObjRAccelXStd_25";
BA_ "ISignalName" SG_ 844 MRR_ObjRAccelXStd_25 "IMRR_ObjRAccelXStd_25";
BA_ "LongName" SG_ 844 MRR_ObjRAccelXStd_25 "Standard Deviation Of Relative Acceleration X";
BA_ "SysSignalName" SG_ 844 MRR_ObjRAccelXStd_25 "MRR_ObjRAccelXStd_25";
BA_ "CompuMethodName" SG_ 844 MRR_ObjFolSts_25 "MRR_ObjFolSts_25";
BA_ "ISignalName" SG_ 844 MRR_ObjFolSts_25 "IMRR_ObjFolSts_25";
BA_ "LongName" SG_ 844 MRR_ObjFolSts_25 "Object tracking status";
BA_ "SysSignalName" SG_ 844 MRR_ObjFolSts_25 "MRR_ObjFolSts_25";
BA_ "CompuMethodName" SG_ 844 MRR_ObjFusionSig_25 "MRR_ObjFusionSig_25";
BA_ "ISignalName" SG_ 844 MRR_ObjFusionSig_25 "IMRR_ObjFusionSig_25";
BA_ "LongName" SG_ 844 MRR_ObjFusionSig_25 "Signal To Indicate Fusion With Camera Or Not";
BA_ "SysSignalName" SG_ 844 MRR_ObjFusionSig_25 "MRR_ObjFusionSig_25";
BA_ "CompuMethodName" SG_ 844 MRR_ObjFusionCamID_25 "MRR_ObjFusionCamID_25";
BA_ "ISignalName" SG_ 844 MRR_ObjFusionCamID_25 "IMRR_ObjFusionCamID_25";
BA_ "LongName" SG_ 844 MRR_ObjFusionCamID_25 "Camera Object Id";
BA_ "SysSignalName" SG_ 844 MRR_ObjFusionCamID_25 "MRR_ObjFusionCamID_25";
BA_ "CompuMethodName" SG_ 844 MRR_Obj_CRC16Checksum_26 "MRR_Obj_CRC16Checksum_26";
BA_ "ISignalName" SG_ 844 MRR_Obj_CRC16Checksum_26 "IMRR_Obj_CRC16Checksum_26";
BA_ "LongName" SG_ 844 MRR_Obj_CRC16Checksum_26 "CRC80byte";
BA_ "SysSignalName" SG_ 844 MRR_Obj_CRC16Checksum_26 "MRR_Obj_CRC16Checksum_26";
BA_ "CompuMethodName" SG_ 844 MRR_Obj_MsgCounter_26 "MRR_Obj_MsgCounter_26";
BA_ "ISignalName" SG_ 844 MRR_Obj_MsgCounter_26 "IMRR_Obj_MsgCounter_26";
BA_ "LongName" SG_ 844 MRR_Obj_MsgCounter_26 "Alive counter 1byte4bit";
BA_ "SysSignalName" SG_ 844 MRR_Obj_MsgCounter_26 "MRR_Obj_MsgCounter_26";
BA_ "CompuMethodName" SG_ 844 MRR_ObjID_26 "MRR_ObjID_26";
BA_ "ISignalName" SG_ 844 MRR_ObjID_26 "IMRR_ObjID_26";
BA_ "LongName" SG_ 844 MRR_ObjID_26 "Id Is An Identifier Number That Allows For Tracking Of Persistent Objects Over Time";
BA_ "SysSignalName" SG_ 844 MRR_ObjID_26 "MRR_ObjID_26";
BA_ "CompuMethodName" SG_ 844 MRR_ObjObstacleProb_26 "MRR_ObjObstacleProb_26";
BA_ "ISignalName" SG_ 844 MRR_ObjObstacleProb_26 "IMRR_ObjObstacleProb_26";
BA_ "LongName" SG_ 844 MRR_ObjObstacleProb_26 "The Probability Of An Object Being An Obstacle";
BA_ "SysSignalName" SG_ 844 MRR_ObjObstacleProb_26 "MRR_ObjObstacleProb_26";
BA_ "CompuMethodName" SG_ 844 MRR_ObjExistProb_26 "MRR_ObjExistProb_26";
BA_ "ISignalName" SG_ 844 MRR_ObjExistProb_26 "IMRR_ObjExistProb_26";
BA_ "LongName" SG_ 844 MRR_ObjExistProb_26 "The Probability Of An Object To Exist In Reality";
BA_ "SysSignalName" SG_ 844 MRR_ObjExistProb_26 "MRR_ObjExistProb_26";
BA_ "CompuMethodName" SG_ 844 MRR_ObjDistY_26 "MRR_ObjDistY_26";
BA_ "ISignalName" SG_ 844 MRR_ObjDistY_26 "IMRR_ObjDistY_26";
BA_ "LongName" SG_ 844 MRR_ObjDistY_26 "Position Of Target Vehicle In Y Direction";
BA_ "SysSignalName" SG_ 844 MRR_ObjDistY_26 "MRR_ObjDistY_26";
BA_ "CompuMethodName" SG_ 844 MRR_ObjDistX_26 "MRR_ObjDistX_26";
BA_ "ISignalName" SG_ 844 MRR_ObjDistX_26 "IMRR_ObjDistX_26";
BA_ "LongName" SG_ 844 MRR_ObjDistX_26 "Position Of Target Vehicle In X Direction";
BA_ "SysSignalName" SG_ 844 MRR_ObjDistX_26 "MRR_ObjDistX_26";
BA_ "CompuMethodName" SG_ 844 MRR_ObjType_26 "MRR_ObjType_26";
BA_ "ISignalName" SG_ 844 MRR_ObjType_26 "IMRR_ObjType_26";
BA_ "LongName" SG_ 844 MRR_ObjType_26 "Class Of Object Type";
BA_ "SysSignalName" SG_ 844 MRR_ObjType_26 "MRR_ObjType_26";
BA_ "CompuMethodName" SG_ 844 MRR_ObjRelVelX_26 "MRR_ObjRelVelX_26";
BA_ "ISignalName" SG_ 844 MRR_ObjRelVelX_26 "IMRR_ObjRelVelX_26";
BA_ "LongName" SG_ 844 MRR_ObjRelVelX_26 "Relative Target Object Velocity In X Direction";
BA_ "SysSignalName" SG_ 844 MRR_ObjRelVelX_26 "MRR_ObjRelVelX_26";
BA_ "CompuMethodName" SG_ 844 MRR_ObjAccelX_26 "MRR_ObjAccelX_26";
BA_ "ISignalName" SG_ 844 MRR_ObjAccelX_26 "IMRR_ObjAccelX_26";
BA_ "LongName" SG_ 844 MRR_ObjAccelX_26 "Relative Target Object Acceleration In X Direction";
BA_ "SysSignalName" SG_ 844 MRR_ObjAccelX_26 "MRR_ObjAccelX_26";
BA_ "CompuMethodName" SG_ 844 MRR_ObjRelVelY_26 "MRR_ObjRelVelY_26";
BA_ "ISignalName" SG_ 844 MRR_ObjRelVelY_26 "IMRR_ObjRelVelY_26";
BA_ "LongName" SG_ 844 MRR_ObjRelVelY_26 "Relative Target Object Velocity In Y Direction";
BA_ "SysSignalName" SG_ 844 MRR_ObjRelVelY_26 "MRR_ObjRelVelY_26";
BA_ "CompuMethodName" SG_ 844 MRR_ObjAccelY_26 "MRR_ObjAccelY_26";
BA_ "ISignalName" SG_ 844 MRR_ObjAccelY_26 "IMRR_ObjAccelY_26";
BA_ "LongName" SG_ 844 MRR_ObjAccelY_26 "Relative Target Object Acceleration In Y Direction";
BA_ "SysSignalName" SG_ 844 MRR_ObjAccelY_26 "MRR_ObjAccelY_26";
BA_ "CompuMethodName" SG_ 844 MRR_ObjDistYStd_26 "MRR_ObjDistYStd_26";
BA_ "ISignalName" SG_ 844 MRR_ObjDistYStd_26 "IMRR_ObjDistYStd_26";
BA_ "LongName" SG_ 844 MRR_ObjDistYStd_26 "Standard Deviation Of Distance Y";
BA_ "SysSignalName" SG_ 844 MRR_ObjDistYStd_26 "MRR_ObjDistYStd_26";
BA_ "CompuMethodName" SG_ 844 MRR_ObjDistXStd_26 "MRR_ObjDistXStd_26";
BA_ "ISignalName" SG_ 844 MRR_ObjDistXStd_26 "IMRR_ObjDistXStd_26";
BA_ "LongName" SG_ 844 MRR_ObjDistXStd_26 "Standard Deviation Of Distance X";
BA_ "SysSignalName" SG_ 844 MRR_ObjDistXStd_26 "MRR_ObjDistXStd_26";
BA_ "CompuMethodName" SG_ 844 MRR_ObjRelVelXStd_26 "MRR_ObjRelVelXStd_26";
BA_ "ISignalName" SG_ 844 MRR_ObjRelVelXStd_26 "IMRR_ObjRelVelXStd_26";
BA_ "LongName" SG_ 844 MRR_ObjRelVelXStd_26 "Standard Deviation Of Relative Velocity X";
BA_ "SysSignalName" SG_ 844 MRR_ObjRelVelXStd_26 "MRR_ObjRelVelXStd_26";
BA_ "CompuMethodName" SG_ 844 MRR_ObjRelVelYStd_26 "MRR_ObjRelVelYStd_26";
BA_ "ISignalName" SG_ 844 MRR_ObjRelVelYStd_26 "IMRR_ObjRelVelYStd_26";
BA_ "LongName" SG_ 844 MRR_ObjRelVelYStd_26 "Standard Deviation Of Relative Velocity Y";
BA_ "SysSignalName" SG_ 844 MRR_ObjRelVelYStd_26 "MRR_ObjRelVelYStd_26";
BA_ "CompuMethodName" SG_ 844 MRR_ObjRAccelYStd_26 "MRR_ObjRAccelYStd_26";
BA_ "ISignalName" SG_ 844 MRR_ObjRAccelYStd_26 "IMRR_ObjRAccelYStd_26";
BA_ "LongName" SG_ 844 MRR_ObjRAccelYStd_26 "Standard Deviation Of Relative Acceleration Y";
BA_ "SysSignalName" SG_ 844 MRR_ObjRAccelYStd_26 "MRR_ObjRAccelYStd_26";
BA_ "CompuMethodName" SG_ 844 MRR_ObjRAccelXStd_26 "MRR_ObjRAccelXStd_26";
BA_ "ISignalName" SG_ 844 MRR_ObjRAccelXStd_26 "IMRR_ObjRAccelXStd_26";
BA_ "LongName" SG_ 844 MRR_ObjRAccelXStd_26 "Standard Deviation Of Relative Acceleration X";
BA_ "SysSignalName" SG_ 844 MRR_ObjRAccelXStd_26 "MRR_ObjRAccelXStd_26";
BA_ "CompuMethodName" SG_ 844 MRR_ObjFolSts_26 "MRR_ObjFolSts_26";
BA_ "ISignalName" SG_ 844 MRR_ObjFolSts_26 "IMRR_ObjFolSts_26";
BA_ "LongName" SG_ 844 MRR_ObjFolSts_26 "Object tracking status";
BA_ "SysSignalName" SG_ 844 MRR_ObjFolSts_26 "MRR_ObjFolSts_26";
BA_ "CompuMethodName" SG_ 844 MRR_ObjFusionSig_26 "MRR_ObjFusionSig_26";
BA_ "ISignalName" SG_ 844 MRR_ObjFusionSig_26 "IMRR_ObjFusionSig_26";
BA_ "LongName" SG_ 844 MRR_ObjFusionSig_26 "Signal To Indicate Fusion With Camera Or Not";
BA_ "SysSignalName" SG_ 844 MRR_ObjFusionSig_26 "MRR_ObjFusionSig_26";
BA_ "CompuMethodName" SG_ 844 MRR_ObjFusionCamID_26 "MRR_ObjFusionCamID_26";
BA_ "ISignalName" SG_ 844 MRR_ObjFusionCamID_26 "IMRR_ObjFusionCamID_26";
BA_ "LongName" SG_ 844 MRR_ObjFusionCamID_26 "Camera Object Id";
BA_ "SysSignalName" SG_ 844 MRR_ObjFusionCamID_26 "MRR_ObjFusionCamID_26";
BA_ "CompuMethodName" SG_ 844 MRR_ObjMovingSts_26 "MRR_ObjMovingSts_26";
BA_ "ISignalName" SG_ 844 MRR_ObjMovingSts_26 "IMRR_ObjMovingSts_26";
BA_ "LongName" SG_ 844 MRR_ObjMovingSts_26 "Object Moving Status";
BA_ "SysSignalName" SG_ 844 MRR_ObjMovingSts_26 "MRR_ObjMovingSts_26";
BA_ "CompuMethodName" SG_ 845 MRR_Obj_CRC16Checksum_27 "MRR_Obj_CRC16Checksum_27";
BA_ "ISignalName" SG_ 845 MRR_Obj_CRC16Checksum_27 "IMRR_Obj_CRC16Checksum_27";
BA_ "LongName" SG_ 845 MRR_Obj_CRC16Checksum_27 "CRC80byte";
BA_ "SysSignalName" SG_ 845 MRR_Obj_CRC16Checksum_27 "MRR_Obj_CRC16Checksum_27";
BA_ "CompuMethodName" SG_ 845 MRR_Obj_MsgCounter_27 "MRR_Obj_MsgCounter_27";
BA_ "ISignalName" SG_ 845 MRR_Obj_MsgCounter_27 "IMRR_Obj_MsgCounter_27";
BA_ "LongName" SG_ 845 MRR_Obj_MsgCounter_27 "Alive counter 1byte4bit";
BA_ "SysSignalName" SG_ 845 MRR_Obj_MsgCounter_27 "MRR_Obj_MsgCounter_27";
BA_ "CompuMethodName" SG_ 845 MRR_ObjMovingSts_27 "MRR_ObjMovingSts_27";
BA_ "ISignalName" SG_ 845 MRR_ObjMovingSts_27 "IMRR_ObjMovingSts_27";
BA_ "LongName" SG_ 845 MRR_ObjMovingSts_27 "Object Moving Status";
BA_ "SysSignalName" SG_ 845 MRR_ObjMovingSts_27 "MRR_ObjMovingSts_27";
BA_ "CompuMethodName" SG_ 845 MRR_ObjID_27 "MRR_ObjID_27";
BA_ "ISignalName" SG_ 845 MRR_ObjID_27 "IMRR_ObjID_27";
BA_ "LongName" SG_ 845 MRR_ObjID_27 "Id Is An Identifier Number That Allows For Tracking Of Persistent Objects Over Time";
BA_ "SysSignalName" SG_ 845 MRR_ObjID_27 "MRR_ObjID_27";
BA_ "CompuMethodName" SG_ 845 MRR_ObjObstacleProb_27 "MRR_ObjObstacleProb_27";
BA_ "ISignalName" SG_ 845 MRR_ObjObstacleProb_27 "IMRR_ObjObstacleProb_27";
BA_ "LongName" SG_ 845 MRR_ObjObstacleProb_27 "The Probability Of An Object Being An Obstacle";
BA_ "SysSignalName" SG_ 845 MRR_ObjObstacleProb_27 "MRR_ObjObstacleProb_27";
BA_ "CompuMethodName" SG_ 845 MRR_ObjExistProb_27 "MRR_ObjExistProb_27";
BA_ "ISignalName" SG_ 845 MRR_ObjExistProb_27 "IMRR_ObjExistProb_27";
BA_ "LongName" SG_ 845 MRR_ObjExistProb_27 "The Probability Of An Object To Exist In Reality";
BA_ "SysSignalName" SG_ 845 MRR_ObjExistProb_27 "MRR_ObjExistProb_27";
BA_ "CompuMethodName" SG_ 845 MRR_ObjDistY_27 "MRR_ObjDistY_27";
BA_ "ISignalName" SG_ 845 MRR_ObjDistY_27 "IMRR_ObjDistY_27";
BA_ "LongName" SG_ 845 MRR_ObjDistY_27 "Position Of Target Vehicle In Y Direction";
BA_ "SysSignalName" SG_ 845 MRR_ObjDistY_27 "MRR_ObjDistY_27";
BA_ "CompuMethodName" SG_ 845 MRR_ObjDistX_27 "MRR_ObjDistX_27";
BA_ "ISignalName" SG_ 845 MRR_ObjDistX_27 "IMRR_ObjDistX_27";
BA_ "LongName" SG_ 845 MRR_ObjDistX_27 "Position Of Target Vehicle In X Direction";
BA_ "SysSignalName" SG_ 845 MRR_ObjDistX_27 "MRR_ObjDistX_27";
BA_ "CompuMethodName" SG_ 845 MRR_ObjType_27 "MRR_ObjType_27";
BA_ "ISignalName" SG_ 845 MRR_ObjType_27 "IMRR_ObjType_27";
BA_ "LongName" SG_ 845 MRR_ObjType_27 "Class Of Object Type";
BA_ "SysSignalName" SG_ 845 MRR_ObjType_27 "MRR_ObjType_27";
BA_ "CompuMethodName" SG_ 845 MRR_ObjRelVelX_27 "MRR_ObjRelVelX_27";
BA_ "ISignalName" SG_ 845 MRR_ObjRelVelX_27 "IMRR_ObjRelVelX_27";
BA_ "LongName" SG_ 845 MRR_ObjRelVelX_27 "Relative Target Object Velocity In X Direction";
BA_ "SysSignalName" SG_ 845 MRR_ObjRelVelX_27 "MRR_ObjRelVelX_27";
BA_ "CompuMethodName" SG_ 845 MRR_ObjAccelX_27 "MRR_ObjAccelX_27";
BA_ "ISignalName" SG_ 845 MRR_ObjAccelX_27 "IMRR_ObjAccelX_27";
BA_ "LongName" SG_ 845 MRR_ObjAccelX_27 "Relative Target Object Acceleration In X Direction";
BA_ "SysSignalName" SG_ 845 MRR_ObjAccelX_27 "MRR_ObjAccelX_27";
BA_ "CompuMethodName" SG_ 845 MRR_ObjRelVelY_27 "MRR_ObjRelVelY_27";
BA_ "ISignalName" SG_ 845 MRR_ObjRelVelY_27 "IMRR_ObjRelVelY_27";
BA_ "LongName" SG_ 845 MRR_ObjRelVelY_27 "Relative Target Object Velocity In Y Direction";
BA_ "SysSignalName" SG_ 845 MRR_ObjRelVelY_27 "MRR_ObjRelVelY_27";
BA_ "CompuMethodName" SG_ 845 MRR_ObjAccelY_27 "MRR_ObjAccelY_27";
BA_ "ISignalName" SG_ 845 MRR_ObjAccelY_27 "IMRR_ObjAccelY_27";
BA_ "LongName" SG_ 845 MRR_ObjAccelY_27 "Relative Target Object Acceleration In Y Direction";
BA_ "SysSignalName" SG_ 845 MRR_ObjAccelY_27 "MRR_ObjAccelY_27";
BA_ "CompuMethodName" SG_ 845 MRR_ObjDistYStd_27 "MRR_ObjDistYStd_27";
BA_ "ISignalName" SG_ 845 MRR_ObjDistYStd_27 "IMRR_ObjDistYStd_27";
BA_ "LongName" SG_ 845 MRR_ObjDistYStd_27 "Standard Deviation Of Distance Y";
BA_ "SysSignalName" SG_ 845 MRR_ObjDistYStd_27 "MRR_ObjDistYStd_27";
BA_ "CompuMethodName" SG_ 845 MRR_ObjDistXStd_27 "MRR_ObjDistXStd_27";
BA_ "ISignalName" SG_ 845 MRR_ObjDistXStd_27 "IMRR_ObjDistXStd_27";
BA_ "LongName" SG_ 845 MRR_ObjDistXStd_27 "Standard Deviation Of Distance X";
BA_ "SysSignalName" SG_ 845 MRR_ObjDistXStd_27 "MRR_ObjDistXStd_27";
BA_ "CompuMethodName" SG_ 845 MRR_ObjRelVelXStd_27 "MRR_ObjRelVelXStd_27";
BA_ "ISignalName" SG_ 845 MRR_ObjRelVelXStd_27 "IMRR_ObjRelVelXStd_27";
BA_ "LongName" SG_ 845 MRR_ObjRelVelXStd_27 "Standard Deviation Of Relative Velocity X";
BA_ "SysSignalName" SG_ 845 MRR_ObjRelVelXStd_27 "MRR_ObjRelVelXStd_27";
BA_ "CompuMethodName" SG_ 845 MRR_ObjRelVelYStd_27 "MRR_ObjRelVelYStd_27";
BA_ "ISignalName" SG_ 845 MRR_ObjRelVelYStd_27 "IMRR_ObjRelVelYStd_27";
BA_ "LongName" SG_ 845 MRR_ObjRelVelYStd_27 "Standard Deviation Of Relative Velocity Y";
BA_ "SysSignalName" SG_ 845 MRR_ObjRelVelYStd_27 "MRR_ObjRelVelYStd_27";
BA_ "CompuMethodName" SG_ 845 MRR_ObjRAccelYStd_27 "MRR_ObjRAccelYStd_27";
BA_ "ISignalName" SG_ 845 MRR_ObjRAccelYStd_27 "IMRR_ObjRAccelYStd_27";
BA_ "LongName" SG_ 845 MRR_ObjRAccelYStd_27 "Standard Deviation Of Relative Acceleration Y";
BA_ "SysSignalName" SG_ 845 MRR_ObjRAccelYStd_27 "MRR_ObjRAccelYStd_27";
BA_ "CompuMethodName" SG_ 845 MRR_ObjRAccelXStd_27 "MRR_ObjRAccelXStd_27";
BA_ "ISignalName" SG_ 845 MRR_ObjRAccelXStd_27 "IMRR_ObjRAccelXStd_27";
BA_ "LongName" SG_ 845 MRR_ObjRAccelXStd_27 "Standard Deviation Of Relative Acceleration X";
BA_ "SysSignalName" SG_ 845 MRR_ObjRAccelXStd_27 "MRR_ObjRAccelXStd_27";
BA_ "CompuMethodName" SG_ 845 MRR_ObjFolSts_27 "MRR_ObjFolSts_27";
BA_ "ISignalName" SG_ 845 MRR_ObjFolSts_27 "IMRR_ObjFolSts_27";
BA_ "LongName" SG_ 845 MRR_ObjFolSts_27 "Object tracking status";
BA_ "SysSignalName" SG_ 845 MRR_ObjFolSts_27 "MRR_ObjFolSts_27";
BA_ "CompuMethodName" SG_ 845 MRR_ObjFusionSig_27 "MRR_ObjFusionSig_27";
BA_ "ISignalName" SG_ 845 MRR_ObjFusionSig_27 "IMRR_ObjFusionSig_27";
BA_ "LongName" SG_ 845 MRR_ObjFusionSig_27 "Signal To Indicate Fusion With Camera Or Not";
BA_ "SysSignalName" SG_ 845 MRR_ObjFusionSig_27 "MRR_ObjFusionSig_27";
BA_ "CompuMethodName" SG_ 845 MRR_ObjFusionCamID_27 "MRR_ObjFusionCamID_27";
BA_ "ISignalName" SG_ 845 MRR_ObjFusionCamID_27 "IMRR_ObjFusionCamID_27";
BA_ "LongName" SG_ 845 MRR_ObjFusionCamID_27 "Camera Object Id";
BA_ "SysSignalName" SG_ 845 MRR_ObjFusionCamID_27 "MRR_ObjFusionCamID_27";
BA_ "CompuMethodName" SG_ 845 MRR_Obj_CRC16Checksum_28 "MRR_Obj_CRC16Checksum_28";
BA_ "ISignalName" SG_ 845 MRR_Obj_CRC16Checksum_28 "IMRR_Obj_CRC16Checksum_28";
BA_ "LongName" SG_ 845 MRR_Obj_CRC16Checksum_28 "CRC80byte";
BA_ "SysSignalName" SG_ 845 MRR_Obj_CRC16Checksum_28 "MRR_Obj_CRC16Checksum_28";
BA_ "CompuMethodName" SG_ 845 MRR_Obj_MsgCounter_28 "MRR_Obj_MsgCounter_28";
BA_ "ISignalName" SG_ 845 MRR_Obj_MsgCounter_28 "IMRR_Obj_MsgCounter_28";
BA_ "LongName" SG_ 845 MRR_Obj_MsgCounter_28 "Alive counter 1byte4bit";
BA_ "SysSignalName" SG_ 845 MRR_Obj_MsgCounter_28 "MRR_Obj_MsgCounter_28";
BA_ "CompuMethodName" SG_ 845 MRR_ObjID_28 "MRR_ObjID_28";
BA_ "ISignalName" SG_ 845 MRR_ObjID_28 "IMRR_ObjID_28";
BA_ "LongName" SG_ 845 MRR_ObjID_28 "Id Is An Identifier Number That Allows For Tracking Of Persistent Objects Over Time";
BA_ "SysSignalName" SG_ 845 MRR_ObjID_28 "MRR_ObjID_28";
BA_ "CompuMethodName" SG_ 845 MRR_ObjObstacleProb_28 "MRR_ObjObstacleProb_28";
BA_ "ISignalName" SG_ 845 MRR_ObjObstacleProb_28 "IMRR_ObjObstacleProb_28";
BA_ "LongName" SG_ 845 MRR_ObjObstacleProb_28 "The Probability Of An Object Being An Obstacle";
BA_ "SysSignalName" SG_ 845 MRR_ObjObstacleProb_28 "MRR_ObjObstacleProb_28";
BA_ "CompuMethodName" SG_ 845 MRR_ObjExistProb_28 "MRR_ObjExistProb_28";
BA_ "ISignalName" SG_ 845 MRR_ObjExistProb_28 "IMRR_ObjExistProb_28";
BA_ "LongName" SG_ 845 MRR_ObjExistProb_28 "The Probability Of An Object To Exist In Reality";
BA_ "SysSignalName" SG_ 845 MRR_ObjExistProb_28 "MRR_ObjExistProb_28";
BA_ "CompuMethodName" SG_ 845 MRR_ObjDistY_28 "MRR_ObjDistY_28";
BA_ "ISignalName" SG_ 845 MRR_ObjDistY_28 "IMRR_ObjDistY_28";
BA_ "LongName" SG_ 845 MRR_ObjDistY_28 "Position Of Target Vehicle In Y Direction";
BA_ "SysSignalName" SG_ 845 MRR_ObjDistY_28 "MRR_ObjDistY_28";
BA_ "CompuMethodName" SG_ 845 MRR_ObjDistX_28 "MRR_ObjDistX_28";
BA_ "ISignalName" SG_ 845 MRR_ObjDistX_28 "IMRR_ObjDistX_28";
BA_ "LongName" SG_ 845 MRR_ObjDistX_28 "Position Of Target Vehicle In X Direction";
BA_ "SysSignalName" SG_ 845 MRR_ObjDistX_28 "MRR_ObjDistX_28";
BA_ "CompuMethodName" SG_ 845 MRR_ObjType_28 "MRR_ObjType_28";
BA_ "ISignalName" SG_ 845 MRR_ObjType_28 "IMRR_ObjType_28";
BA_ "LongName" SG_ 845 MRR_ObjType_28 "Class Of Object Type";
BA_ "SysSignalName" SG_ 845 MRR_ObjType_28 "MRR_ObjType_28";
BA_ "CompuMethodName" SG_ 845 MRR_ObjRelVelX_28 "MRR_ObjRelVelX_28";
BA_ "ISignalName" SG_ 845 MRR_ObjRelVelX_28 "IMRR_ObjRelVelX_28";
BA_ "LongName" SG_ 845 MRR_ObjRelVelX_28 "Relative Target Object Velocity In X Direction";
BA_ "SysSignalName" SG_ 845 MRR_ObjRelVelX_28 "MRR_ObjRelVelX_28";
BA_ "CompuMethodName" SG_ 845 MRR_ObjAccelX_28 "MRR_ObjAccelX_28";
BA_ "ISignalName" SG_ 845 MRR_ObjAccelX_28 "IMRR_ObjAccelX_28";
BA_ "LongName" SG_ 845 MRR_ObjAccelX_28 "Relative Target Object Acceleration In X Direction";
BA_ "SysSignalName" SG_ 845 MRR_ObjAccelX_28 "MRR_ObjAccelX_28";
BA_ "CompuMethodName" SG_ 845 MRR_ObjRelVelY_28 "MRR_ObjRelVelY_28";
BA_ "ISignalName" SG_ 845 MRR_ObjRelVelY_28 "IMRR_ObjRelVelY_28";
BA_ "LongName" SG_ 845 MRR_ObjRelVelY_28 "Relative Target Object Velocity In Y Direction";
BA_ "SysSignalName" SG_ 845 MRR_ObjRelVelY_28 "MRR_ObjRelVelY_28";
BA_ "CompuMethodName" SG_ 845 MRR_ObjAccelY_28 "MRR_ObjAccelY_28";
BA_ "ISignalName" SG_ 845 MRR_ObjAccelY_28 "IMRR_ObjAccelY_28";
BA_ "LongName" SG_ 845 MRR_ObjAccelY_28 "Relative Target Object Acceleration In Y Direction";
BA_ "SysSignalName" SG_ 845 MRR_ObjAccelY_28 "MRR_ObjAccelY_28";
BA_ "CompuMethodName" SG_ 845 MRR_ObjDistYStd_28 "MRR_ObjDistYStd_28";
BA_ "ISignalName" SG_ 845 MRR_ObjDistYStd_28 "IMRR_ObjDistYStd_28";
BA_ "LongName" SG_ 845 MRR_ObjDistYStd_28 "Standard Deviation Of Distance Y";
BA_ "SysSignalName" SG_ 845 MRR_ObjDistYStd_28 "MRR_ObjDistYStd_28";
BA_ "CompuMethodName" SG_ 845 MRR_ObjDistXStd_28 "MRR_ObjDistXStd_28";
BA_ "ISignalName" SG_ 845 MRR_ObjDistXStd_28 "IMRR_ObjDistXStd_28";
BA_ "LongName" SG_ 845 MRR_ObjDistXStd_28 "Standard Deviation Of Distance X";
BA_ "SysSignalName" SG_ 845 MRR_ObjDistXStd_28 "MRR_ObjDistXStd_28";
BA_ "CompuMethodName" SG_ 845 MRR_ObjRelVelXStd_28 "MRR_ObjRelVelXStd_28";
BA_ "ISignalName" SG_ 845 MRR_ObjRelVelXStd_28 "IMRR_ObjRelVelXStd_28";
BA_ "LongName" SG_ 845 MRR_ObjRelVelXStd_28 "Standard Deviation Of Relative Velocity X";
BA_ "SysSignalName" SG_ 845 MRR_ObjRelVelXStd_28 "MRR_ObjRelVelXStd_28";
BA_ "CompuMethodName" SG_ 845 MRR_ObjRelVelYStd_28 "MRR_ObjRelVelYStd_28";
BA_ "ISignalName" SG_ 845 MRR_ObjRelVelYStd_28 "IMRR_ObjRelVelYStd_28";
BA_ "LongName" SG_ 845 MRR_ObjRelVelYStd_28 "Standard Deviation Of Relative Velocity Y";
BA_ "SysSignalName" SG_ 845 MRR_ObjRelVelYStd_28 "MRR_ObjRelVelYStd_28";
BA_ "CompuMethodName" SG_ 845 MRR_ObjRAccelYStd_28 "MRR_ObjRAccelYStd_28";
BA_ "ISignalName" SG_ 845 MRR_ObjRAccelYStd_28 "IMRR_ObjRAccelYStd_28";
BA_ "LongName" SG_ 845 MRR_ObjRAccelYStd_28 "Standard Deviation Of Relative Acceleration Y";
BA_ "SysSignalName" SG_ 845 MRR_ObjRAccelYStd_28 "MRR_ObjRAccelYStd_28";
BA_ "CompuMethodName" SG_ 845 MRR_ObjRAccelXStd_28 "MRR_ObjRAccelXStd_28";
BA_ "ISignalName" SG_ 845 MRR_ObjRAccelXStd_28 "IMRR_ObjRAccelXStd_28";
BA_ "LongName" SG_ 845 MRR_ObjRAccelXStd_28 "Standard Deviation Of Relative Acceleration X";
BA_ "SysSignalName" SG_ 845 MRR_ObjRAccelXStd_28 "MRR_ObjRAccelXStd_28";
BA_ "CompuMethodName" SG_ 845 MRR_ObjFolSts_28 "MRR_ObjFolSts_28";
BA_ "ISignalName" SG_ 845 MRR_ObjFolSts_28 "IMRR_ObjFolSts_28";
BA_ "LongName" SG_ 845 MRR_ObjFolSts_28 "Object tracking status";
BA_ "SysSignalName" SG_ 845 MRR_ObjFolSts_28 "MRR_ObjFolSts_28";
BA_ "CompuMethodName" SG_ 845 MRR_ObjFusionSig_28 "MRR_ObjFusionSig_28";
BA_ "ISignalName" SG_ 845 MRR_ObjFusionSig_28 "IMRR_ObjFusionSig_28";
BA_ "LongName" SG_ 845 MRR_ObjFusionSig_28 "Signal To Indicate Fusion With Camera Or Not";
BA_ "SysSignalName" SG_ 845 MRR_ObjFusionSig_28 "MRR_ObjFusionSig_28";
BA_ "CompuMethodName" SG_ 845 MRR_ObjFusionCamID_28 "MRR_ObjFusionCamID_28";
BA_ "ISignalName" SG_ 845 MRR_ObjFusionCamID_28 "IMRR_ObjFusionCamID_28";
BA_ "LongName" SG_ 845 MRR_ObjFusionCamID_28 "Camera Object Id";
BA_ "SysSignalName" SG_ 845 MRR_ObjFusionCamID_28 "MRR_ObjFusionCamID_28";
BA_ "CompuMethodName" SG_ 845 MRR_ObjMovingSts_28 "MRR_ObjMovingSts_28";
BA_ "ISignalName" SG_ 845 MRR_ObjMovingSts_28 "IMRR_ObjMovingSts_28";
BA_ "LongName" SG_ 845 MRR_ObjMovingSts_28 "Object Moving Status";
BA_ "SysSignalName" SG_ 845 MRR_ObjMovingSts_28 "MRR_ObjMovingSts_28";
BA_ "CompuMethodName" SG_ 846 MRR_Obj_CRC16Checksum_29 "MRR_Obj_CRC16Checksum_29";
BA_ "ISignalName" SG_ 846 MRR_Obj_CRC16Checksum_29 "IMRR_Obj_CRC16Checksum_29";
BA_ "LongName" SG_ 846 MRR_Obj_CRC16Checksum_29 "CRC80byte";
BA_ "SysSignalName" SG_ 846 MRR_Obj_CRC16Checksum_29 "MRR_Obj_CRC16Checksum_29";
BA_ "CompuMethodName" SG_ 846 MRR_Obj_MsgCounter_29 "MRR_Obj_MsgCounter_29";
BA_ "ISignalName" SG_ 846 MRR_Obj_MsgCounter_29 "IMRR_Obj_MsgCounter_29";
BA_ "LongName" SG_ 846 MRR_Obj_MsgCounter_29 "Alive counter 1byte4bit";
BA_ "SysSignalName" SG_ 846 MRR_Obj_MsgCounter_29 "MRR_Obj_MsgCounter_29";
BA_ "CompuMethodName" SG_ 846 MRR_ObjMovingSts_29 "MRR_ObjMovingSts_29";
BA_ "ISignalName" SG_ 846 MRR_ObjMovingSts_29 "IMRR_ObjMovingSts_29";
BA_ "LongName" SG_ 846 MRR_ObjMovingSts_29 "Object Moving Status";
BA_ "SysSignalName" SG_ 846 MRR_ObjMovingSts_29 "MRR_ObjMovingSts_29";
BA_ "CompuMethodName" SG_ 846 MRR_ObjID_29 "MRR_ObjID_29";
BA_ "ISignalName" SG_ 846 MRR_ObjID_29 "IMRR_ObjID_29";
BA_ "LongName" SG_ 846 MRR_ObjID_29 "Id Is An Identifier Number That Allows For Tracking Of Persistent Objects Over Time";
BA_ "SysSignalName" SG_ 846 MRR_ObjID_29 "MRR_ObjID_29";
BA_ "CompuMethodName" SG_ 846 MRR_ObjObstacleProb_29 "MRR_ObjObstacleProb_29";
BA_ "ISignalName" SG_ 846 MRR_ObjObstacleProb_29 "IMRR_ObjObstacleProb_29";
BA_ "LongName" SG_ 846 MRR_ObjObstacleProb_29 "The Probability Of An Object Being An Obstacle";
BA_ "SysSignalName" SG_ 846 MRR_ObjObstacleProb_29 "MRR_ObjObstacleProb_29";
BA_ "CompuMethodName" SG_ 846 MRR_ObjExistProb_29 "MRR_ObjExistProb_29";
BA_ "ISignalName" SG_ 846 MRR_ObjExistProb_29 "IMRR_ObjExistProb_29";
BA_ "LongName" SG_ 846 MRR_ObjExistProb_29 "The Probability Of An Object To Exist In Reality";
BA_ "SysSignalName" SG_ 846 MRR_ObjExistProb_29 "MRR_ObjExistProb_29";
BA_ "CompuMethodName" SG_ 846 MRR_ObjDistY_29 "MRR_ObjDistY_29";
BA_ "ISignalName" SG_ 846 MRR_ObjDistY_29 "IMRR_ObjDistY_29";
BA_ "LongName" SG_ 846 MRR_ObjDistY_29 "Position Of Target Vehicle In Y Direction";
BA_ "SysSignalName" SG_ 846 MRR_ObjDistY_29 "MRR_ObjDistY_29";
BA_ "CompuMethodName" SG_ 846 MRR_ObjDistX_29 "MRR_ObjDistX_29";
BA_ "ISignalName" SG_ 846 MRR_ObjDistX_29 "IMRR_ObjDistX_29";
BA_ "LongName" SG_ 846 MRR_ObjDistX_29 "Position Of Target Vehicle In X Direction";
BA_ "SysSignalName" SG_ 846 MRR_ObjDistX_29 "MRR_ObjDistX_29";
BA_ "CompuMethodName" SG_ 846 MRR_ObjType_29 "MRR_ObjType_29";
BA_ "ISignalName" SG_ 846 MRR_ObjType_29 "IMRR_ObjType_29";
BA_ "LongName" SG_ 846 MRR_ObjType_29 "Class Of Object Type";
BA_ "SysSignalName" SG_ 846 MRR_ObjType_29 "MRR_ObjType_29";
BA_ "CompuMethodName" SG_ 846 MRR_ObjRelVelX_29 "MRR_ObjRelVelX_29";
BA_ "ISignalName" SG_ 846 MRR_ObjRelVelX_29 "IMRR_ObjRelVelX_29";
BA_ "LongName" SG_ 846 MRR_ObjRelVelX_29 "Relative Target Object Velocity In X Direction";
BA_ "SysSignalName" SG_ 846 MRR_ObjRelVelX_29 "MRR_ObjRelVelX_29";
BA_ "CompuMethodName" SG_ 846 MRR_ObjAccelX_29 "MRR_ObjAccelX_29";
BA_ "ISignalName" SG_ 846 MRR_ObjAccelX_29 "IMRR_ObjAccelX_29";
BA_ "LongName" SG_ 846 MRR_ObjAccelX_29 "Relative Target Object Acceleration In X Direction";
BA_ "SysSignalName" SG_ 846 MRR_ObjAccelX_29 "MRR_ObjAccelX_29";
BA_ "CompuMethodName" SG_ 846 MRR_ObjRelVelY_29 "MRR_ObjRelVelY_29";
BA_ "ISignalName" SG_ 846 MRR_ObjRelVelY_29 "IMRR_ObjRelVelY_29";
BA_ "LongName" SG_ 846 MRR_ObjRelVelY_29 "Relative Target Object Velocity In Y Direction";
BA_ "SysSignalName" SG_ 846 MRR_ObjRelVelY_29 "MRR_ObjRelVelY_29";
BA_ "CompuMethodName" SG_ 846 MRR_ObjAccelY_29 "MRR_ObjAccelY_29";
BA_ "ISignalName" SG_ 846 MRR_ObjAccelY_29 "IMRR_ObjAccelY_29";
BA_ "LongName" SG_ 846 MRR_ObjAccelY_29 "Relative Target Object Acceleration In Y Direction";
BA_ "SysSignalName" SG_ 846 MRR_ObjAccelY_29 "MRR_ObjAccelY_29";
BA_ "CompuMethodName" SG_ 846 MRR_ObjDistYStd_29 "MRR_ObjDistYStd_29";
BA_ "ISignalName" SG_ 846 MRR_ObjDistYStd_29 "IMRR_ObjDistYStd_29";
BA_ "LongName" SG_ 846 MRR_ObjDistYStd_29 "Standard Deviation Of Distance Y";
BA_ "SysSignalName" SG_ 846 MRR_ObjDistYStd_29 "MRR_ObjDistYStd_29";
BA_ "CompuMethodName" SG_ 846 MRR_ObjDistXStd_29 "MRR_ObjDistXStd_29";
BA_ "ISignalName" SG_ 846 MRR_ObjDistXStd_29 "IMRR_ObjDistXStd_29";
BA_ "LongName" SG_ 846 MRR_ObjDistXStd_29 "Standard Deviation Of Distance X";
BA_ "SysSignalName" SG_ 846 MRR_ObjDistXStd_29 "MRR_ObjDistXStd_29";
BA_ "CompuMethodName" SG_ 846 MRR_ObjRelVelXStd_29 "MRR_ObjRelVelXStd_29";
BA_ "ISignalName" SG_ 846 MRR_ObjRelVelXStd_29 "IMRR_ObjRelVelXStd_29";
BA_ "LongName" SG_ 846 MRR_ObjRelVelXStd_29 "Standard Deviation Of Relative Velocity X";
BA_ "SysSignalName" SG_ 846 MRR_ObjRelVelXStd_29 "MRR_ObjRelVelXStd_29";
BA_ "CompuMethodName" SG_ 846 MRR_ObjRelVelYStd_29 "MRR_ObjRelVelYStd_29";
BA_ "ISignalName" SG_ 846 MRR_ObjRelVelYStd_29 "IMRR_ObjRelVelYStd_29";
BA_ "LongName" SG_ 846 MRR_ObjRelVelYStd_29 "Standard Deviation Of Relative Velocity Y";
BA_ "SysSignalName" SG_ 846 MRR_ObjRelVelYStd_29 "MRR_ObjRelVelYStd_29";
BA_ "CompuMethodName" SG_ 846 MRR_ObjRAccelYStd_29 "MRR_ObjRAccelYStd_29";
BA_ "ISignalName" SG_ 846 MRR_ObjRAccelYStd_29 "IMRR_ObjRAccelYStd_29";
BA_ "LongName" SG_ 846 MRR_ObjRAccelYStd_29 "Standard Deviation Of Relative Acceleration Y";
BA_ "SysSignalName" SG_ 846 MRR_ObjRAccelYStd_29 "MRR_ObjRAccelYStd_29";
BA_ "CompuMethodName" SG_ 846 MRR_ObjRAccelXStd_29 "MRR_ObjRAccelXStd_29";
BA_ "ISignalName" SG_ 846 MRR_ObjRAccelXStd_29 "IMRR_ObjRAccelXStd_29";
BA_ "LongName" SG_ 846 MRR_ObjRAccelXStd_29 "Standard Deviation Of Relative Acceleration X";
BA_ "SysSignalName" SG_ 846 MRR_ObjRAccelXStd_29 "MRR_ObjRAccelXStd_29";
BA_ "CompuMethodName" SG_ 846 MRR_ObjFolSts_29 "MRR_ObjFolSts_29";
BA_ "ISignalName" SG_ 846 MRR_ObjFolSts_29 "IMRR_ObjFolSts_29";
BA_ "LongName" SG_ 846 MRR_ObjFolSts_29 "Object tracking status";
BA_ "SysSignalName" SG_ 846 MRR_ObjFolSts_29 "MRR_ObjFolSts_29";
BA_ "CompuMethodName" SG_ 846 MRR_ObjFusionSig_29 "MRR_ObjFusionSig_29";
BA_ "ISignalName" SG_ 846 MRR_ObjFusionSig_29 "IMRR_ObjFusionSig_29";
BA_ "LongName" SG_ 846 MRR_ObjFusionSig_29 "Signal To Indicate Fusion With Camera Or Not";
BA_ "SysSignalName" SG_ 846 MRR_ObjFusionSig_29 "MRR_ObjFusionSig_29";
BA_ "CompuMethodName" SG_ 846 MRR_ObjFusionCamID_29 "MRR_ObjFusionCamID_29";
BA_ "ISignalName" SG_ 846 MRR_ObjFusionCamID_29 "IMRR_ObjFusionCamID_29";
BA_ "LongName" SG_ 846 MRR_ObjFusionCamID_29 "Camera Object Id";
BA_ "SysSignalName" SG_ 846 MRR_ObjFusionCamID_29 "MRR_ObjFusionCamID_29";
BA_ "CompuMethodName" SG_ 846 MRR_Obj_CRC16Checksum_30 "MRR_Obj_CRC16Checksum_30";
BA_ "ISignalName" SG_ 846 MRR_Obj_CRC16Checksum_30 "IMRR_Obj_CRC16Checksum_30";
BA_ "LongName" SG_ 846 MRR_Obj_CRC16Checksum_30 "CRC80byte";
BA_ "SysSignalName" SG_ 846 MRR_Obj_CRC16Checksum_30 "MRR_Obj_CRC16Checksum_30";
BA_ "CompuMethodName" SG_ 846 MRR_Obj_MsgCounter_30 "MRR_Obj_MsgCounter_30";
BA_ "ISignalName" SG_ 846 MRR_Obj_MsgCounter_30 "IMRR_Obj_MsgCounter_30";
BA_ "LongName" SG_ 846 MRR_Obj_MsgCounter_30 "Alive counter 1byte4bit";
BA_ "SysSignalName" SG_ 846 MRR_Obj_MsgCounter_30 "MRR_Obj_MsgCounter_30";
BA_ "CompuMethodName" SG_ 846 MRR_ObjID_30 "MRR_ObjID_30";
BA_ "ISignalName" SG_ 846 MRR_ObjID_30 "IMRR_ObjID_30";
BA_ "LongName" SG_ 846 MRR_ObjID_30 "Id Is An Identifier Number That Allows For Tracking Of Persistent Objects Over Time";
BA_ "SysSignalName" SG_ 846 MRR_ObjID_30 "MRR_ObjID_30";
BA_ "CompuMethodName" SG_ 846 MRR_ObjObstacleProb_30 "MRR_ObjObstacleProb_30";
BA_ "ISignalName" SG_ 846 MRR_ObjObstacleProb_30 "IMRR_ObjObstacleProb_30";
BA_ "LongName" SG_ 846 MRR_ObjObstacleProb_30 "The Probability Of An Object Being An Obstacle";
BA_ "SysSignalName" SG_ 846 MRR_ObjObstacleProb_30 "MRR_ObjObstacleProb_30";
BA_ "CompuMethodName" SG_ 846 MRR_ObjExistProb_30 "MRR_ObjExistProb_30";
BA_ "ISignalName" SG_ 846 MRR_ObjExistProb_30 "IMRR_ObjExistProb_30";
BA_ "LongName" SG_ 846 MRR_ObjExistProb_30 "The Probability Of An Object To Exist In Reality";
BA_ "SysSignalName" SG_ 846 MRR_ObjExistProb_30 "MRR_ObjExistProb_30";
BA_ "CompuMethodName" SG_ 846 MRR_ObjDistY_30 "MRR_ObjDistY_30";
BA_ "ISignalName" SG_ 846 MRR_ObjDistY_30 "IMRR_ObjDistY_30";
BA_ "LongName" SG_ 846 MRR_ObjDistY_30 "Position Of Target Vehicle In Y Direction";
BA_ "SysSignalName" SG_ 846 MRR_ObjDistY_30 "MRR_ObjDistY_30";
BA_ "CompuMethodName" SG_ 846 MRR_ObjDistX_30 "MRR_ObjDistX_30";
BA_ "ISignalName" SG_ 846 MRR_ObjDistX_30 "IMRR_ObjDistX_30";
BA_ "LongName" SG_ 846 MRR_ObjDistX_30 "Position Of Target Vehicle In X Direction";
BA_ "SysSignalName" SG_ 846 MRR_ObjDistX_30 "MRR_ObjDistX_30";
BA_ "CompuMethodName" SG_ 846 MRR_ObjType_30 "MRR_ObjType_30";
BA_ "ISignalName" SG_ 846 MRR_ObjType_30 "IMRR_ObjType_30";
BA_ "LongName" SG_ 846 MRR_ObjType_30 "Class Of Object Type";
BA_ "SysSignalName" SG_ 846 MRR_ObjType_30 "MRR_ObjType_30";
BA_ "CompuMethodName" SG_ 846 MRR_ObjRelVelX_30 "MRR_ObjRelVelX_30";
BA_ "ISignalName" SG_ 846 MRR_ObjRelVelX_30 "IMRR_ObjRelVelX_30";
BA_ "LongName" SG_ 846 MRR_ObjRelVelX_30 "Relative Target Object Velocity In X Direction";
BA_ "SysSignalName" SG_ 846 MRR_ObjRelVelX_30 "MRR_ObjRelVelX_30";
BA_ "CompuMethodName" SG_ 846 MRR_ObjAccelX_30 "MRR_ObjAccelX_30";
BA_ "ISignalName" SG_ 846 MRR_ObjAccelX_30 "IMRR_ObjAccelX_30";
BA_ "LongName" SG_ 846 MRR_ObjAccelX_30 "Relative Target Object Acceleration In X Direction";
BA_ "SysSignalName" SG_ 846 MRR_ObjAccelX_30 "MRR_ObjAccelX_30";
BA_ "CompuMethodName" SG_ 846 MRR_ObjRelVelY_30 "MRR_ObjRelVelY_30";
BA_ "ISignalName" SG_ 846 MRR_ObjRelVelY_30 "IMRR_ObjRelVelY_30";
BA_ "LongName" SG_ 846 MRR_ObjRelVelY_30 "Relative Target Object Velocity In Y Direction";
BA_ "SysSignalName" SG_ 846 MRR_ObjRelVelY_30 "MRR_ObjRelVelY_30";
BA_ "CompuMethodName" SG_ 846 MRR_ObjAccelY_30 "MRR_ObjAccelY_30";
BA_ "ISignalName" SG_ 846 MRR_ObjAccelY_30 "IMRR_ObjAccelY_30";
BA_ "LongName" SG_ 846 MRR_ObjAccelY_30 "Relative Target Object Acceleration In Y Direction";
BA_ "SysSignalName" SG_ 846 MRR_ObjAccelY_30 "MRR_ObjAccelY_30";
BA_ "CompuMethodName" SG_ 846 MRR_ObjDistYStd_30 "MRR_ObjDistYStd_30";
BA_ "ISignalName" SG_ 846 MRR_ObjDistYStd_30 "IMRR_ObjDistYStd_30";
BA_ "LongName" SG_ 846 MRR_ObjDistYStd_30 "Standard Deviation Of Distance Y";
BA_ "SysSignalName" SG_ 846 MRR_ObjDistYStd_30 "MRR_ObjDistYStd_30";
BA_ "CompuMethodName" SG_ 846 MRR_ObjDistXStd_30 "MRR_ObjDistXStd_30";
BA_ "ISignalName" SG_ 846 MRR_ObjDistXStd_30 "IMRR_ObjDistXStd_30";
BA_ "LongName" SG_ 846 MRR_ObjDistXStd_30 "Standard Deviation Of Distance X";
BA_ "SysSignalName" SG_ 846 MRR_ObjDistXStd_30 "MRR_ObjDistXStd_30";
BA_ "CompuMethodName" SG_ 846 MRR_ObjRelVelXStd_30 "MRR_ObjRelVelXStd_30";
BA_ "ISignalName" SG_ 846 MRR_ObjRelVelXStd_30 "IMRR_ObjRelVelXStd_30";
BA_ "LongName" SG_ 846 MRR_ObjRelVelXStd_30 "Standard Deviation Of Relative Velocity X";
BA_ "SysSignalName" SG_ 846 MRR_ObjRelVelXStd_30 "MRR_ObjRelVelXStd_30";
BA_ "CompuMethodName" SG_ 846 MRR_ObjRelVelYStd_30 "MRR_ObjRelVelYStd_30";
BA_ "ISignalName" SG_ 846 MRR_ObjRelVelYStd_30 "IMRR_ObjRelVelYStd_30";
BA_ "LongName" SG_ 846 MRR_ObjRelVelYStd_30 "Standard Deviation Of Relative Velocity Y";
BA_ "SysSignalName" SG_ 846 MRR_ObjRelVelYStd_30 "MRR_ObjRelVelYStd_30";
BA_ "CompuMethodName" SG_ 846 MRR_ObjRAccelYStd_30 "MRR_ObjRAccelYStd_30";
BA_ "ISignalName" SG_ 846 MRR_ObjRAccelYStd_30 "IMRR_ObjRAccelYStd_30";
BA_ "LongName" SG_ 846 MRR_ObjRAccelYStd_30 "Standard Deviation Of Relative Acceleration Y";
BA_ "SysSignalName" SG_ 846 MRR_ObjRAccelYStd_30 "MRR_ObjRAccelYStd_30";
BA_ "CompuMethodName" SG_ 846 MRR_ObjRAccelXStd_30 "MRR_ObjRAccelXStd_30";
BA_ "ISignalName" SG_ 846 MRR_ObjRAccelXStd_30 "IMRR_ObjRAccelXStd_30";
BA_ "LongName" SG_ 846 MRR_ObjRAccelXStd_30 "Standard Deviation Of Relative Acceleration X";
BA_ "SysSignalName" SG_ 846 MRR_ObjRAccelXStd_30 "MRR_ObjRAccelXStd_30";
BA_ "CompuMethodName" SG_ 846 MRR_ObjFolSts_30 "MRR_ObjFolSts_30";
BA_ "ISignalName" SG_ 846 MRR_ObjFolSts_30 "IMRR_ObjFolSts_30";
BA_ "LongName" SG_ 846 MRR_ObjFolSts_30 "Object tracking status";
BA_ "SysSignalName" SG_ 846 MRR_ObjFolSts_30 "MRR_ObjFolSts_30";
BA_ "CompuMethodName" SG_ 846 MRR_ObjFusionSig_30 "MRR_ObjFusionSig_30";
BA_ "ISignalName" SG_ 846 MRR_ObjFusionSig_30 "IMRR_ObjFusionSig_30";
BA_ "LongName" SG_ 846 MRR_ObjFusionSig_30 "Signal To Indicate Fusion With Camera Or Not";
BA_ "SysSignalName" SG_ 846 MRR_ObjFusionSig_30 "MRR_ObjFusionSig_30";
BA_ "CompuMethodName" SG_ 846 MRR_ObjFusionCamID_30 "MRR_ObjFusionCamID_30";
BA_ "ISignalName" SG_ 846 MRR_ObjFusionCamID_30 "IMRR_ObjFusionCamID_30";
BA_ "LongName" SG_ 846 MRR_ObjFusionCamID_30 "Camera Object Id";
BA_ "SysSignalName" SG_ 846 MRR_ObjFusionCamID_30 "MRR_ObjFusionCamID_30";
BA_ "CompuMethodName" SG_ 846 MRR_ObjMovingSts_30 "MRR_ObjMovingSts_30";
BA_ "ISignalName" SG_ 846 MRR_ObjMovingSts_30 "IMRR_ObjMovingSts_30";
BA_ "LongName" SG_ 846 MRR_ObjMovingSts_30 "Object Moving Status";
BA_ "SysSignalName" SG_ 846 MRR_ObjMovingSts_30 "MRR_ObjMovingSts_30";
BA_ "CompuMethodName" SG_ 847 MRR_Obj_CRC16Checksum_31 "MRR_Obj_CRC16Checksum_31";
BA_ "ISignalName" SG_ 847 MRR_Obj_CRC16Checksum_31 "IMRR_Obj_CRC16Checksum_31";
BA_ "LongName" SG_ 847 MRR_Obj_CRC16Checksum_31 "CRC80byte";
BA_ "SysSignalName" SG_ 847 MRR_Obj_CRC16Checksum_31 "MRR_Obj_CRC16Checksum_31";
BA_ "CompuMethodName" SG_ 847 MRR_Obj_MsgCounter_31 "MRR_Obj_MsgCounter_31";
BA_ "ISignalName" SG_ 847 MRR_Obj_MsgCounter_31 "IMRR_Obj_MsgCounter_31";
BA_ "LongName" SG_ 847 MRR_Obj_MsgCounter_31 "Alive counter 1byte4bit";
BA_ "SysSignalName" SG_ 847 MRR_Obj_MsgCounter_31 "MRR_Obj_MsgCounter_31";
BA_ "CompuMethodName" SG_ 847 MRR_ObjMovingSts_31 "MRR_ObjMovingSts_31";
BA_ "ISignalName" SG_ 847 MRR_ObjMovingSts_31 "IMRR_ObjMovingSts_31";
BA_ "LongName" SG_ 847 MRR_ObjMovingSts_31 "Object Moving Status";
BA_ "SysSignalName" SG_ 847 MRR_ObjMovingSts_31 "MRR_ObjMovingSts_31";
BA_ "CompuMethodName" SG_ 847 MRR_ObjID_31 "MRR_ObjID_31";
BA_ "ISignalName" SG_ 847 MRR_ObjID_31 "IMRR_ObjID_31";
BA_ "LongName" SG_ 847 MRR_ObjID_31 "Id Is An Identifier Number That Allows For Tracking Of Persistent Objects Over Time";
BA_ "SysSignalName" SG_ 847 MRR_ObjID_31 "MRR_ObjID_31";
BA_ "CompuMethodName" SG_ 847 MRR_ObjObstacleProb_31 "MRR_ObjObstacleProb_31";
BA_ "ISignalName" SG_ 847 MRR_ObjObstacleProb_31 "IMRR_ObjObstacleProb_31";
BA_ "LongName" SG_ 847 MRR_ObjObstacleProb_31 "The Probability Of An Object Being An Obstacle";
BA_ "SysSignalName" SG_ 847 MRR_ObjObstacleProb_31 "MRR_ObjObstacleProb_31";
BA_ "CompuMethodName" SG_ 847 MRR_ObjExistProb_31 "MRR_ObjExistProb_31";
BA_ "ISignalName" SG_ 847 MRR_ObjExistProb_31 "IMRR_ObjExistProb_31";
BA_ "LongName" SG_ 847 MRR_ObjExistProb_31 "The Probability Of An Object To Exist In Reality";
BA_ "SysSignalName" SG_ 847 MRR_ObjExistProb_31 "MRR_ObjExistProb_31";
BA_ "CompuMethodName" SG_ 847 MRR_ObjDistY_31 "MRR_ObjDistY_31";
BA_ "ISignalName" SG_ 847 MRR_ObjDistY_31 "IMRR_ObjDistY_31";
BA_ "LongName" SG_ 847 MRR_ObjDistY_31 "Position Of Target Vehicle In Y Direction";
BA_ "SysSignalName" SG_ 847 MRR_ObjDistY_31 "MRR_ObjDistY_31";
BA_ "CompuMethodName" SG_ 847 MRR_ObjDistX_31 "MRR_ObjDistX_31";
BA_ "ISignalName" SG_ 847 MRR_ObjDistX_31 "IMRR_ObjDistX_31";
BA_ "LongName" SG_ 847 MRR_ObjDistX_31 "Position Of Target Vehicle In X Direction";
BA_ "SysSignalName" SG_ 847 MRR_ObjDistX_31 "MRR_ObjDistX_31";
BA_ "CompuMethodName" SG_ 847 MRR_ObjType_31 "MRR_ObjType_31";
BA_ "ISignalName" SG_ 847 MRR_ObjType_31 "IMRR_ObjType_31";
BA_ "LongName" SG_ 847 MRR_ObjType_31 "Class Of Object Type";
BA_ "SysSignalName" SG_ 847 MRR_ObjType_31 "MRR_ObjType_31";
BA_ "CompuMethodName" SG_ 847 MRR_ObjRelVelX_31 "MRR_ObjRelVelX_31";
BA_ "ISignalName" SG_ 847 MRR_ObjRelVelX_31 "IMRR_ObjRelVelX_31";
BA_ "LongName" SG_ 847 MRR_ObjRelVelX_31 "Relative Target Object Velocity In X Direction";
BA_ "SysSignalName" SG_ 847 MRR_ObjRelVelX_31 "MRR_ObjRelVelX_31";
BA_ "CompuMethodName" SG_ 847 MRR_ObjAccelX_31 "MRR_ObjAccelX_31";
BA_ "ISignalName" SG_ 847 MRR_ObjAccelX_31 "IMRR_ObjAccelX_31";
BA_ "LongName" SG_ 847 MRR_ObjAccelX_31 "Relative Target Object Acceleration In X Direction";
BA_ "SysSignalName" SG_ 847 MRR_ObjAccelX_31 "MRR_ObjAccelX_31";
BA_ "CompuMethodName" SG_ 847 MRR_ObjRelVelY_31 "MRR_ObjRelVelY_31";
BA_ "ISignalName" SG_ 847 MRR_ObjRelVelY_31 "IMRR_ObjRelVelY_31";
BA_ "LongName" SG_ 847 MRR_ObjRelVelY_31 "Relative Target Object Velocity In Y Direction";
BA_ "SysSignalName" SG_ 847 MRR_ObjRelVelY_31 "MRR_ObjRelVelY_31";
BA_ "CompuMethodName" SG_ 847 MRR_ObjAccelY_31 "MRR_ObjAccelY_31";
BA_ "ISignalName" SG_ 847 MRR_ObjAccelY_31 "IMRR_ObjAccelY_31";
BA_ "LongName" SG_ 847 MRR_ObjAccelY_31 "Relative Target Object Acceleration In Y Direction";
BA_ "SysSignalName" SG_ 847 MRR_ObjAccelY_31 "MRR_ObjAccelY_31";
BA_ "CompuMethodName" SG_ 847 MRR_ObjDistYStd_31 "MRR_ObjDistYStd_31";
BA_ "ISignalName" SG_ 847 MRR_ObjDistYStd_31 "IMRR_ObjDistYStd_31";
BA_ "LongName" SG_ 847 MRR_ObjDistYStd_31 "Standard Deviation Of Distance Y";
BA_ "SysSignalName" SG_ 847 MRR_ObjDistYStd_31 "MRR_ObjDistYStd_31";
BA_ "CompuMethodName" SG_ 847 MRR_ObjDistXStd_31 "MRR_ObjDistXStd_31";
BA_ "ISignalName" SG_ 847 MRR_ObjDistXStd_31 "IMRR_ObjDistXStd_31";
BA_ "LongName" SG_ 847 MRR_ObjDistXStd_31 "Standard Deviation Of Distance X";
BA_ "SysSignalName" SG_ 847 MRR_ObjDistXStd_31 "MRR_ObjDistXStd_31";
BA_ "CompuMethodName" SG_ 847 MRR_ObjRelVelXStd_31 "MRR_ObjRelVelXStd_31";
BA_ "ISignalName" SG_ 847 MRR_ObjRelVelXStd_31 "IMRR_ObjRelVelXStd_31";
BA_ "LongName" SG_ 847 MRR_ObjRelVelXStd_31 "Standard Deviation Of Relative Velocity X";
BA_ "SysSignalName" SG_ 847 MRR_ObjRelVelXStd_31 "MRR_ObjRelVelXStd_31";
BA_ "CompuMethodName" SG_ 847 MRR_ObjRelVelYStd_31 "MRR_ObjRelVelYStd_31";
BA_ "ISignalName" SG_ 847 MRR_ObjRelVelYStd_31 "IMRR_ObjRelVelYStd_31";
BA_ "LongName" SG_ 847 MRR_ObjRelVelYStd_31 "Standard Deviation Of Relative Velocity Y";
BA_ "SysSignalName" SG_ 847 MRR_ObjRelVelYStd_31 "MRR_ObjRelVelYStd_31";
BA_ "CompuMethodName" SG_ 847 MRR_ObjRAccelYStd_31 "MRR_ObjRAccelYStd_31";
BA_ "ISignalName" SG_ 847 MRR_ObjRAccelYStd_31 "IMRR_ObjRAccelYStd_31";
BA_ "LongName" SG_ 847 MRR_ObjRAccelYStd_31 "Standard Deviation Of Relative Acceleration Y";
BA_ "SysSignalName" SG_ 847 MRR_ObjRAccelYStd_31 "MRR_ObjRAccelYStd_31";
BA_ "CompuMethodName" SG_ 847 MRR_ObjRAccelXStd_31 "MRR_ObjRAccelXStd_31";
BA_ "ISignalName" SG_ 847 MRR_ObjRAccelXStd_31 "IMRR_ObjRAccelXStd_31";
BA_ "LongName" SG_ 847 MRR_ObjRAccelXStd_31 "Standard Deviation Of Relative Acceleration X";
BA_ "SysSignalName" SG_ 847 MRR_ObjRAccelXStd_31 "MRR_ObjRAccelXStd_31";
BA_ "CompuMethodName" SG_ 847 MRR_ObjFolSts_31 "MRR_ObjFolSts_31";
BA_ "ISignalName" SG_ 847 MRR_ObjFolSts_31 "IMRR_ObjFolSts_31";
BA_ "LongName" SG_ 847 MRR_ObjFolSts_31 "Object tracking status";
BA_ "SysSignalName" SG_ 847 MRR_ObjFolSts_31 "MRR_ObjFolSts_31";
BA_ "CompuMethodName" SG_ 847 MRR_ObjFusionSig_31 "MRR_ObjFusionSig_31";
BA_ "ISignalName" SG_ 847 MRR_ObjFusionSig_31 "IMRR_ObjFusionSig_31";
BA_ "LongName" SG_ 847 MRR_ObjFusionSig_31 "Signal To Indicate Fusion With Camera Or Not";
BA_ "SysSignalName" SG_ 847 MRR_ObjFusionSig_31 "MRR_ObjFusionSig_31";
BA_ "CompuMethodName" SG_ 847 MRR_ObjFusionCamID_31 "MRR_ObjFusionCamID_31";
BA_ "ISignalName" SG_ 847 MRR_ObjFusionCamID_31 "IMRR_ObjFusionCamID_31";
BA_ "LongName" SG_ 847 MRR_ObjFusionCamID_31 "Camera Object Id";
BA_ "SysSignalName" SG_ 847 MRR_ObjFusionCamID_31 "MRR_ObjFusionCamID_31";
BA_ "CompuMethodName" SG_ 847 MRR_Obj_CRC16Checksum_32 "MRR_Obj_CRC16Checksum_32";
BA_ "ISignalName" SG_ 847 MRR_Obj_CRC16Checksum_32 "IMRR_Obj_CRC16Checksum_32";
BA_ "LongName" SG_ 847 MRR_Obj_CRC16Checksum_32 "CRC80byte";
BA_ "SysSignalName" SG_ 847 MRR_Obj_CRC16Checksum_32 "MRR_Obj_CRC16Checksum_32";
BA_ "CompuMethodName" SG_ 847 MRR_Obj_MsgCounter_32 "MRR_Obj_MsgCounter_32";
BA_ "ISignalName" SG_ 847 MRR_Obj_MsgCounter_32 "IMRR_Obj_MsgCounter_32";
BA_ "LongName" SG_ 847 MRR_Obj_MsgCounter_32 "Alive counter 1byte4bit";
BA_ "SysSignalName" SG_ 847 MRR_Obj_MsgCounter_32 "MRR_Obj_MsgCounter_32";
BA_ "CompuMethodName" SG_ 847 MRR_ObjID_32 "MRR_ObjID_32";
BA_ "ISignalName" SG_ 847 MRR_ObjID_32 "IMRR_ObjID_32";
BA_ "LongName" SG_ 847 MRR_ObjID_32 "Id Is An Identifier Number That Allows For Tracking Of Persistent Objects Over Time";
BA_ "SysSignalName" SG_ 847 MRR_ObjID_32 "MRR_ObjID_32";
BA_ "CompuMethodName" SG_ 847 MRR_ObjObstacleProb_32 "MRR_ObjObstacleProb_32";
BA_ "ISignalName" SG_ 847 MRR_ObjObstacleProb_32 "IMRR_ObjObstacleProb_32";
BA_ "LongName" SG_ 847 MRR_ObjObstacleProb_32 "The Probability Of An Object Being An Obstacle";
BA_ "SysSignalName" SG_ 847 MRR_ObjObstacleProb_32 "MRR_ObjObstacleProb_32";
BA_ "CompuMethodName" SG_ 847 MRR_ObjExistProb_32 "MRR_ObjExistProb_32";
BA_ "ISignalName" SG_ 847 MRR_ObjExistProb_32 "IMRR_ObjExistProb_32";
BA_ "LongName" SG_ 847 MRR_ObjExistProb_32 "The Probability Of An Object To Exist In Reality";
BA_ "SysSignalName" SG_ 847 MRR_ObjExistProb_32 "MRR_ObjExistProb_32";
BA_ "CompuMethodName" SG_ 847 MRR_ObjDistY_32 "MRR_ObjDistY_32";
BA_ "ISignalName" SG_ 847 MRR_ObjDistY_32 "IMRR_ObjDistY_32";
BA_ "LongName" SG_ 847 MRR_ObjDistY_32 "Position Of Target Vehicle In Y Direction";
BA_ "SysSignalName" SG_ 847 MRR_ObjDistY_32 "MRR_ObjDistY_32";
BA_ "CompuMethodName" SG_ 847 MRR_ObjDistX_32 "MRR_ObjDistX_32";
BA_ "ISignalName" SG_ 847 MRR_ObjDistX_32 "IMRR_ObjDistX_32";
BA_ "LongName" SG_ 847 MRR_ObjDistX_32 "Position Of Target Vehicle In X Direction";
BA_ "SysSignalName" SG_ 847 MRR_ObjDistX_32 "MRR_ObjDistX_32";
BA_ "CompuMethodName" SG_ 847 MRR_ObjType_32 "MRR_ObjType_32";
BA_ "ISignalName" SG_ 847 MRR_ObjType_32 "IMRR_ObjType_32";
BA_ "LongName" SG_ 847 MRR_ObjType_32 "Class Of Object Type";
BA_ "SysSignalName" SG_ 847 MRR_ObjType_32 "MRR_ObjType_32";
BA_ "CompuMethodName" SG_ 847 MRR_ObjRelVelX_32 "MRR_ObjRelVelX_32";
BA_ "ISignalName" SG_ 847 MRR_ObjRelVelX_32 "IMRR_ObjRelVelX_32";
BA_ "LongName" SG_ 847 MRR_ObjRelVelX_32 "Relative Target Object Velocity In X Direction";
BA_ "SysSignalName" SG_ 847 MRR_ObjRelVelX_32 "MRR_ObjRelVelX_32";
BA_ "CompuMethodName" SG_ 847 MRR_ObjAccelX_32 "MRR_ObjAccelX_32";
BA_ "ISignalName" SG_ 847 MRR_ObjAccelX_32 "IMRR_ObjAccelX_32";
BA_ "LongName" SG_ 847 MRR_ObjAccelX_32 "Relative Target Object Acceleration In X Direction";
BA_ "SysSignalName" SG_ 847 MRR_ObjAccelX_32 "MRR_ObjAccelX_32";
BA_ "CompuMethodName" SG_ 847 MRR_ObjRelVelY_32 "MRR_ObjRelVelY_32";
BA_ "ISignalName" SG_ 847 MRR_ObjRelVelY_32 "IMRR_ObjRelVelY_32";
BA_ "LongName" SG_ 847 MRR_ObjRelVelY_32 "Relative Target Object Velocity In Y Direction";
BA_ "SysSignalName" SG_ 847 MRR_ObjRelVelY_32 "MRR_ObjRelVelY_32";
BA_ "CompuMethodName" SG_ 847 MRR_ObjAccelY_32 "MRR_ObjAccelY_32";
BA_ "ISignalName" SG_ 847 MRR_ObjAccelY_32 "IMRR_ObjAccelY_32";
BA_ "LongName" SG_ 847 MRR_ObjAccelY_32 "Relative Target Object Acceleration In Y Direction";
BA_ "SysSignalName" SG_ 847 MRR_ObjAccelY_32 "MRR_ObjAccelY_32";
BA_ "CompuMethodName" SG_ 847 MRR_ObjDistYStd_32 "MRR_ObjDistYStd_32";
BA_ "ISignalName" SG_ 847 MRR_ObjDistYStd_32 "IMRR_ObjDistYStd_32";
BA_ "LongName" SG_ 847 MRR_ObjDistYStd_32 "Standard Deviation Of Distance Y";
BA_ "SysSignalName" SG_ 847 MRR_ObjDistYStd_32 "MRR_ObjDistYStd_32";
BA_ "CompuMethodName" SG_ 847 MRR_ObjDistXStd_32 "MRR_ObjDistXStd_32";
BA_ "ISignalName" SG_ 847 MRR_ObjDistXStd_32 "IMRR_ObjDistXStd_32";
BA_ "LongName" SG_ 847 MRR_ObjDistXStd_32 "Standard Deviation Of Distance X";
BA_ "SysSignalName" SG_ 847 MRR_ObjDistXStd_32 "MRR_ObjDistXStd_32";
BA_ "CompuMethodName" SG_ 847 MRR_ObjRelVelXStd_32 "MRR_ObjRelVelXStd_32";
BA_ "ISignalName" SG_ 847 MRR_ObjRelVelXStd_32 "IMRR_ObjRelVelXStd_32";
BA_ "LongName" SG_ 847 MRR_ObjRelVelXStd_32 "Standard Deviation Of Relative Velocity X";
BA_ "SysSignalName" SG_ 847 MRR_ObjRelVelXStd_32 "MRR_ObjRelVelXStd_32";
BA_ "CompuMethodName" SG_ 847 MRR_ObjRelVelYStd_32 "MRR_ObjRelVelYStd_32";
BA_ "ISignalName" SG_ 847 MRR_ObjRelVelYStd_32 "IMRR_ObjRelVelYStd_32";
BA_ "LongName" SG_ 847 MRR_ObjRelVelYStd_32 "Standard Deviation Of Relative Velocity Y";
BA_ "SysSignalName" SG_ 847 MRR_ObjRelVelYStd_32 "MRR_ObjRelVelYStd_32";
BA_ "CompuMethodName" SG_ 847 MRR_ObjRAccelYStd_32 "MRR_ObjRAccelYStd_32";
BA_ "ISignalName" SG_ 847 MRR_ObjRAccelYStd_32 "IMRR_ObjRAccelYStd_32";
BA_ "LongName" SG_ 847 MRR_ObjRAccelYStd_32 "Standard Deviation Of Relative Acceleration Y";
BA_ "SysSignalName" SG_ 847 MRR_ObjRAccelYStd_32 "MRR_ObjRAccelYStd_32";
BA_ "CompuMethodName" SG_ 847 MRR_ObjRAccelXStd_32 "MRR_ObjRAccelXStd_32";
BA_ "ISignalName" SG_ 847 MRR_ObjRAccelXStd_32 "IMRR_ObjRAccelXStd_32";
BA_ "LongName" SG_ 847 MRR_ObjRAccelXStd_32 "Standard Deviation Of Relative Acceleration X";
BA_ "SysSignalName" SG_ 847 MRR_ObjRAccelXStd_32 "MRR_ObjRAccelXStd_32";
BA_ "CompuMethodName" SG_ 847 MRR_ObjFolSts_32 "MRR_ObjFolSts_32";
BA_ "ISignalName" SG_ 847 MRR_ObjFolSts_32 "IMRR_ObjFolSts_32";
BA_ "LongName" SG_ 847 MRR_ObjFolSts_32 "Object tracking status";
BA_ "SysSignalName" SG_ 847 MRR_ObjFolSts_32 "MRR_ObjFolSts_32";
BA_ "CompuMethodName" SG_ 847 MRR_ObjFusionSig_32 "MRR_ObjFusionSig_32";
BA_ "ISignalName" SG_ 847 MRR_ObjFusionSig_32 "IMRR_ObjFusionSig_32";
BA_ "LongName" SG_ 847 MRR_ObjFusionSig_32 "Signal To Indicate Fusion With Camera Or Not";
BA_ "SysSignalName" SG_ 847 MRR_ObjFusionSig_32 "MRR_ObjFusionSig_32";
BA_ "CompuMethodName" SG_ 847 MRR_ObjFusionCamID_32 "MRR_ObjFusionCamID_32";
BA_ "ISignalName" SG_ 847 MRR_ObjFusionCamID_32 "IMRR_ObjFusionCamID_32";
BA_ "LongName" SG_ 847 MRR_ObjFusionCamID_32 "Camera Object Id";
BA_ "SysSignalName" SG_ 847 MRR_ObjFusionCamID_32 "MRR_ObjFusionCamID_32";
BA_ "CompuMethodName" SG_ 847 MRR_ObjMovingSts_32 "MRR_ObjMovingSts_32";
BA_ "ISignalName" SG_ 847 MRR_ObjMovingSts_32 "IMRR_ObjMovingSts_32";
BA_ "LongName" SG_ 847 MRR_ObjMovingSts_32 "Object Moving Status";
BA_ "SysSignalName" SG_ 847 MRR_ObjMovingSts_32 "MRR_ObjMovingSts_32";
BA_ "CompuMethodName" SG_ 848 FDR_ADAS_LocalCANFD3_PDU17_CRC "FDR_ADAS_LocalCANFD3_PDU17_CRC";
BA_ "ISignalName" SG_ 848 FDR_ADAS_LocalCANFD3_PDU17_CRC "IFDR_ADAS_LocalCANFD3_PDU17_CRC";
BA_ "SysSignalName" SG_ 848 FDR_ADAS_LocalCANFD3_PDU17_CRC "FDR_ADAS_LocalCANFD3_PDU17_CRC";
BA_ "CompuMethodName" SG_ 848 FDR_ADAS_LocalCANFD3_PDU17_RC "FDR_ADAS_LocalCANFD3_PDU17_RC";
BA_ "ISignalName" SG_ 848 FDR_ADAS_LocalCANFD3_PDU17_RC "IFDR_ADAS_LocalCANFD3_PDU17_RC";
BA_ "SysSignalName" SG_ 848 FDR_ADAS_LocalCANFD3_PDU17_RC "FDR_ADAS_LocalCANFD3_PDU17_RC";
BA_ "CompuMethodName" SG_ 848 FDR_ADAS_LocalCANFD3_Group33_Res0 "FDR_ADAS_LocalCANFD3_Group33_Reserved1";
BA_ "GenSigStartValue" SG_ 848 FDR_ADAS_LocalCANFD3_Group33_Res0 15;
BA_ "ISignalName" SG_ 848 FDR_ADAS_LocalCANFD3_Group33_Res0 "IFDR_ADAS_LocalCANFD3_Group33_Reserved1";
BA_ "SysSignalName" SG_ 848 FDR_ADAS_LocalCANFD3_Group33_Res0 "FDR_ADAS_LocalCANFD3_Group33_Reserved1";
BA_ "SystemSignalLongSymbol" SG_ 848 FDR_ADAS_LocalCANFD3_Group33_Res0 "FDR_ADAS_LocalCANFD3_Group33_Reserved1";
BA_ "CompuMethodName" SG_ 848 FDR_ADAS_LocalCANFD3_Group33_Res1 "FDR_ADAS_LocalCANFD3_Group33_Reserved2";
BA_ "GenSigStartValue" SG_ 848 FDR_ADAS_LocalCANFD3_Group33_Res1 255;
BA_ "ISignalName" SG_ 848 FDR_ADAS_LocalCANFD3_Group33_Res1 "IFDR_ADAS_LocalCANFD3_Group33_Reserved2";
BA_ "SysSignalName" SG_ 848 FDR_ADAS_LocalCANFD3_Group33_Res1 "FDR_ADAS_LocalCANFD3_Group33_Reserved2";
BA_ "SystemSignalLongSymbol" SG_ 848 FDR_ADAS_LocalCANFD3_Group33_Res1 "FDR_ADAS_LocalCANFD3_Group33_Reserved2";
BA_ "CompuMethodName" SG_ 848 FDR_AEB_TargDx "FDR_AEB_TargDx";
BA_ "ISignalName" SG_ 848 FDR_AEB_TargDx "IFDR_AEB_TargDx";
BA_ "LongName" SG_ 848 FDR_AEB_TargDx "Position of target vehicle in x-direction";
BA_ "SysSignalName" SG_ 848 FDR_AEB_TargDx "FDR_AEB_TargDx";
BA_ "CompuMethodName" SG_ 848 FDR_AEB_TargAx "FDR_AEB_TargAx";
BA_ "ISignalName" SG_ 848 FDR_AEB_TargAx "IFDR_AEB_TargAx";
BA_ "LongName" SG_ 848 FDR_AEB_TargAx "Relative target accelerration  in x-direction";
BA_ "SysSignalName" SG_ 848 FDR_AEB_TargAx "FDR_AEB_TargAx";
BA_ "CompuMethodName" SG_ 848 FDR_AEB_TargAy "FDR_AEB_TargAy";
BA_ "ISignalName" SG_ 848 FDR_AEB_TargAy "IFDR_AEB_TargAy";
BA_ "LongName" SG_ 848 FDR_AEB_TargAy "Relative target accelerration  in y-direction";
BA_ "SysSignalName" SG_ 848 FDR_AEB_TargAy "FDR_AEB_TargAy";
BA_ "CompuMethodName" SG_ 848 FDR_AEB_TargVy "FDR_AEB_TargVy";
BA_ "ISignalName" SG_ 848 FDR_AEB_TargVy "IFDR_AEB_TargVy";
BA_ "LongName" SG_ 848 FDR_AEB_TargVy "Relative target object velocity in y-direction";
BA_ "SysSignalName" SG_ 848 FDR_AEB_TargVy "FDR_AEB_TargVy";
BA_ "CompuMethodName" SG_ 848 FDR_ADAS_LocalCANFD3_Group33_Res2 "FDR_ADAS_LocalCANFD3_Group33_Reserved3";
BA_ "GenSigStartValue" SG_ 848 FDR_ADAS_LocalCANFD3_Group33_Res2 7;
BA_ "ISignalName" SG_ 848 FDR_ADAS_LocalCANFD3_Group33_Res2 "IFDR_ADAS_LocalCANFD3_Group33_Reserved3";
BA_ "SysSignalName" SG_ 848 FDR_ADAS_LocalCANFD3_Group33_Res2 "FDR_ADAS_LocalCANFD3_Group33_Reserved3";
BA_ "SystemSignalLongSymbol" SG_ 848 FDR_ADAS_LocalCANFD3_Group33_Res2 "FDR_ADAS_LocalCANFD3_Group33_Reserved3";
BA_ "CompuMethodName" SG_ 848 FDR_ADAS_LocalCANFD3_Group33_Res3 "FDR_ADAS_LocalCANFD3_Group33_Reserved4";
BA_ "GenSigStartValue" SG_ 848 FDR_ADAS_LocalCANFD3_Group33_Res3 7;
BA_ "ISignalName" SG_ 848 FDR_ADAS_LocalCANFD3_Group33_Res3 "IFDR_ADAS_LocalCANFD3_Group33_Reserved4";
BA_ "SysSignalName" SG_ 848 FDR_ADAS_LocalCANFD3_Group33_Res3 "FDR_ADAS_LocalCANFD3_Group33_Reserved4";
BA_ "SystemSignalLongSymbol" SG_ 848 FDR_ADAS_LocalCANFD3_Group33_Res3 "FDR_ADAS_LocalCANFD3_Group33_Reserved4";
BA_ "CompuMethodName" SG_ 848 FDR_AEB_TargExistProb "FDR_AEB_TargExistProb";
BA_ "ISignalName" SG_ 848 FDR_AEB_TargExistProb "IFDR_AEB_TargExistProb";
BA_ "LongName" SG_ 848 FDR_AEB_TargExistProb "The probability of an object to exist in reality";
BA_ "SysSignalName" SG_ 848 FDR_AEB_TargExistProb "FDR_AEB_TargExistProb";
BA_ "CompuMethodName" SG_ 848 FDR_AEB_TargDy "FDR_AEB_TargDy";
BA_ "ISignalName" SG_ 848 FDR_AEB_TargDy "IFDR_AEB_TargDy";
BA_ "LongName" SG_ 848 FDR_AEB_TargDy "Position of target vehicle in y-direction";
BA_ "SysSignalName" SG_ 848 FDR_AEB_TargDy "FDR_AEB_TargDy";
BA_ "CompuMethodName" SG_ 848 FDR_AEB_TargVx "FDR_AEB_TargVx";
BA_ "ISignalName" SG_ 848 FDR_AEB_TargVx "IFDR_AEB_TargVx";
BA_ "LongName" SG_ 848 FDR_AEB_TargVx "Relative target object velocity in x-direction";
BA_ "SysSignalName" SG_ 848 FDR_AEB_TargVx "FDR_AEB_TargVx";
BA_ "CompuMethodName" SG_ 848 FDR_ADAS_LocalCANFD3_Group33_Res4 "FDR_ADAS_LocalCANFD3_Group33_Reserved5";
BA_ "GenSigStartValue" SG_ 848 FDR_ADAS_LocalCANFD3_Group33_Res4 255;
BA_ "ISignalName" SG_ 848 FDR_ADAS_LocalCANFD3_Group33_Res4 "IFDR_ADAS_LocalCANFD3_Group33_Reserved5";
BA_ "SysSignalName" SG_ 848 FDR_ADAS_LocalCANFD3_Group33_Res4 "FDR_ADAS_LocalCANFD3_Group33_Reserved5";
BA_ "SystemSignalLongSymbol" SG_ 848 FDR_ADAS_LocalCANFD3_Group33_Res4 "FDR_ADAS_LocalCANFD3_Group33_Reserved5";
BA_ "CompuMethodName" SG_ 848 FDR_ADAS_LocalCANFD3_Group33_Res5 "FDR_ADAS_LocalCANFD3_Group33_Reserved6";
BA_ "GenSigStartValue" SG_ 848 FDR_ADAS_LocalCANFD3_Group33_Res5 255;
BA_ "ISignalName" SG_ 848 FDR_ADAS_LocalCANFD3_Group33_Res5 "IFDR_ADAS_LocalCANFD3_Group33_Reserved6";
BA_ "SysSignalName" SG_ 848 FDR_ADAS_LocalCANFD3_Group33_Res5 "FDR_ADAS_LocalCANFD3_Group33_Reserved6";
BA_ "SystemSignalLongSymbol" SG_ 848 FDR_ADAS_LocalCANFD3_Group33_Res5 "FDR_ADAS_LocalCANFD3_Group33_Reserved6";
BA_ "CompuMethodName" SG_ 848 FDR_ADAS_LocalCANFD3_Group33_Res6 "FDR_ADAS_LocalCANFD3_Group33_Reserved7";
BA_ "GenSigStartValue" SG_ 848 FDR_ADAS_LocalCANFD3_Group33_Res6 255;
BA_ "ISignalName" SG_ 848 FDR_ADAS_LocalCANFD3_Group33_Res6 "IFDR_ADAS_LocalCANFD3_Group33_Reserved7";
BA_ "SysSignalName" SG_ 848 FDR_ADAS_LocalCANFD3_Group33_Res6 "FDR_ADAS_LocalCANFD3_Group33_Reserved7";
BA_ "SystemSignalLongSymbol" SG_ 848 FDR_ADAS_LocalCANFD3_Group33_Res6 "FDR_ADAS_LocalCANFD3_Group33_Reserved7";
BA_ "CompuMethodName" SG_ 849 FDRtoIPD_Rsrv01 "FDRtoIPD_Rsrv01";
BA_ "ISignalName" SG_ 849 FDRtoIPD_Rsrv01 "IFDRtoIPD_Rsrv01";
BA_ "LongName" SG_ 849 FDRtoIPD_Rsrv01 "FDR_to_IPD_Reserved01";
BA_ "SysSignalName" SG_ 849 FDRtoIPD_Rsrv01 "FDRtoIPD_Rsrv01";
BA_ "CompuMethodName" SG_ 849 FDRtoIPD_Rsrv05 "FDRtoIPD_Rsrv05";
BA_ "ISignalName" SG_ 849 FDRtoIPD_Rsrv05 "IFDRtoIPD_Rsrv05";
BA_ "LongName" SG_ 849 FDRtoIPD_Rsrv05 "FDR_to_IPD_Reserved05";
BA_ "SysSignalName" SG_ 849 FDRtoIPD_Rsrv05 "FDRtoIPD_Rsrv05";
BA_ "CompuMethodName" SG_ 849 FDRtoIPD_Rsrv04 "FDRtoIPD_Rsrv04";
BA_ "ISignalName" SG_ 849 FDRtoIPD_Rsrv04 "IFDRtoIPD_Rsrv04";
BA_ "LongName" SG_ 849 FDRtoIPD_Rsrv04 "FDR_to_IPD_Reserved04";
BA_ "SysSignalName" SG_ 849 FDRtoIPD_Rsrv04 "FDRtoIPD_Rsrv04";
BA_ "CompuMethodName" SG_ 849 FDRtoIPD_Rsrv02 "FDRtoIPD_Rsrv02";
BA_ "ISignalName" SG_ 849 FDRtoIPD_Rsrv02 "IFDRtoIPD_Rsrv02";
BA_ "LongName" SG_ 849 FDRtoIPD_Rsrv02 "FDR_to_IPD_Reserved02";
BA_ "SysSignalName" SG_ 849 FDRtoIPD_Rsrv02 "FDRtoIPD_Rsrv02";
BA_ "CompuMethodName" SG_ 849 FDRtoIPD_Rsrv07 "FDRtoIPD_Rsrv07";
BA_ "ISignalName" SG_ 849 FDRtoIPD_Rsrv07 "IFDRtoIPD_Rsrv07";
BA_ "LongName" SG_ 849 FDRtoIPD_Rsrv07 "FDR_to_IPD_Reserved07";
BA_ "SysSignalName" SG_ 849 FDRtoIPD_Rsrv07 "FDRtoIPD_Rsrv07";
BA_ "CompuMethodName" SG_ 849 FDRtoIPD_Rsrv06 "FDRtoIPD_Rsrv06";
BA_ "ISignalName" SG_ 849 FDRtoIPD_Rsrv06 "IFDRtoIPD_Rsrv06";
BA_ "LongName" SG_ 849 FDRtoIPD_Rsrv06 "FDR_to_IPD_Reserved06";
BA_ "SysSignalName" SG_ 849 FDRtoIPD_Rsrv06 "FDRtoIPD_Rsrv06";
BA_ "CompuMethodName" SG_ 849 FDRtoIPD_Rsrv09 "FDRtoIPD_Rsrv09";
BA_ "ISignalName" SG_ 849 FDRtoIPD_Rsrv09 "IFDRtoIPD_Rsrv09";
BA_ "LongName" SG_ 849 FDRtoIPD_Rsrv09 "FDR_to_IPD_Reserved09";
BA_ "SysSignalName" SG_ 849 FDRtoIPD_Rsrv09 "FDRtoIPD_Rsrv09";
BA_ "CompuMethodName" SG_ 849 FDRtoIPD_Rsrv08 "FDRtoIPD_Rsrv08";
BA_ "ISignalName" SG_ 849 FDRtoIPD_Rsrv08 "IFDRtoIPD_Rsrv08";
BA_ "LongName" SG_ 849 FDRtoIPD_Rsrv08 "FDR_to_IPD_Reserved08";
BA_ "SysSignalName" SG_ 849 FDRtoIPD_Rsrv08 "FDRtoIPD_Rsrv08";
BA_ "CompuMethodName" SG_ 849 FDRtoIPD_Rsrv10 "FDRtoIPD_Rsrv10";
BA_ "ISignalName" SG_ 849 FDRtoIPD_Rsrv10 "IFDRtoIPD_Rsrv10";
BA_ "LongName" SG_ 849 FDRtoIPD_Rsrv10 "FDR_to_IPD_Reserved10";
BA_ "SysSignalName" SG_ 849 FDRtoIPD_Rsrv10 "FDRtoIPD_Rsrv10";
BA_ "CompuMethodName" SG_ 849 FDRtoIPD_Rsrv11 "FDRtoIPD_Rsrv11";
BA_ "ISignalName" SG_ 849 FDRtoIPD_Rsrv11 "IFDRtoIPD_Rsrv11";
BA_ "LongName" SG_ 849 FDRtoIPD_Rsrv11 "FDR_to_IPD_Reserved11";
BA_ "SysSignalName" SG_ 849 FDRtoIPD_Rsrv11 "FDRtoIPD_Rsrv11";
BA_ "CompuMethodName" SG_ 849 FDRtoIPD_Rsrv12 "FDRtoIPD_Rsrv12";
BA_ "ISignalName" SG_ 849 FDRtoIPD_Rsrv12 "IFDRtoIPD_Rsrv12";
BA_ "LongName" SG_ 849 FDRtoIPD_Rsrv12 "FDR_to_IPD_Reserved12";
BA_ "SysSignalName" SG_ 849 FDRtoIPD_Rsrv12 "FDRtoIPD_Rsrv12";
BA_ "CompuMethodName" SG_ 849 FDRtoIPD_Rsrv03 "FDRtoIPD_Rsrv03";
BA_ "ISignalName" SG_ 849 FDRtoIPD_Rsrv03 "IFDRtoIPD_Rsrv03";
BA_ "LongName" SG_ 849 FDRtoIPD_Rsrv03 "FDR_to_IPD_Reserved03";
BA_ "SysSignalName" SG_ 849 FDRtoIPD_Rsrv03 "FDRtoIPD_Rsrv03";
VAL_ 840 MRR_ObjMovingSts_17 0 "MRR_ObjMovingSts_17_0_Stationary" 1 "MRR_ObjMovingSts_17_1_TrackStopppedFromMoving" 2 "MRR_ObjMovingSts_17_2_TrackMoving" 3 "MRR_ObjMovingSts_17_3_TrackOncoming" 4 "MRR_ObjMovingSts_17_4_TrackStoppedFromOncoming" 11 "MRR_ObjMovingSts_17_B_NoTrack" 14 "MRR_ObjMovingSts_17_E_Error" 15 "MRR_ObjMovingSts_17_F_NotAvailable";
VAL_ 840 MRR_ObjType_17 0 "MRR_ObjType_17_0_unknown" 3 "MRR_ObjType_17_3_pedestrian" 5 "MRR_ObjType_17_5_bicycle" 6 "MRR_ObjType_17_6_motorbike" 7 "MRR_ObjType_17_7_vehicle" 8 "MRR_ObjType_17_8_van" 9 "MRR_ObjType_17_9_truck" 15 "MRR_ObjType_17_F_init";
VAL_ 840 MRR_ObjFolSts_17 0 "MRR_ObjFolSts_17_0_invalid" 1 "MRR_ObjFolSts_17_1_New" 2 "MRR_ObjFolSts_17_2_Update" 3 "MRR_ObjFolSts_17_3_Predicted";
VAL_ 840 MRR_ObjFusionSig_17 0 "MRR_ObjFusionSig_17_0_RadarOnly" 1 "MRR_ObjFusionSig_17_1_FusionWithCamera";
VAL_ 840 MRR_ObjType_18 0 "MRR_ObjType_18_0_unknown" 3 "MRR_ObjType_18_3_pedestrian" 5 "MRR_ObjType_18_5_bicycle" 6 "MRR_ObjType_18_6_motorbike" 7 "MRR_ObjType_18_7_vehicle" 8 "MRR_ObjType_18_8_van" 9 "MRR_ObjType_18_9_truck" 15 "MRR_ObjType_18_F_init";
VAL_ 840 MRR_ObjFolSts_18 0 "MRR_ObjFolSts_18_0_invalid" 1 "MRR_ObjFolSts_18_1_New" 2 "MRR_ObjFolSts_18_2_Update" 3 "MRR_ObjFolSts_18_3_Predicted";
VAL_ 840 MRR_ObjFusionSig_18 0 "MRR_ObjFusionSig_18_0_RadarOnly" 1 "MRR_ObjFusionSig_18_1_FusionWithCamera";
VAL_ 840 MRR_ObjMovingSts_18 0 "MRR_ObjMovingSts_18_0_Stationary" 1 "MRR_ObjMovingSts_18_1_TrackStopppedFromMoving" 2 "MRR_ObjMovingSts_18_2_TrackMoving" 3 "MRR_ObjMovingSts_18_3_TrackOncoming" 4 "MRR_ObjMovingSts_18_4_TrackStoppedFromOncoming" 11 "MRR_ObjMovingSts_18_B_NoTrack" 14 "MRR_ObjMovingSts_18_E_Error" 15 "MRR_ObjMovingSts_18_F_NotAvailable";
VAL_ 841 MRR_ObjMovingSts_19 0 "MRR_ObjMovingSts_19_0_Stationary" 1 "MRR_ObjMovingSts_19_1_TrackStopppedFromMoving" 2 "MRR_ObjMovingSts_19_2_TrackMoving" 3 "MRR_ObjMovingSts_19_3_TrackOncoming" 4 "MRR_ObjMovingSts_19_4_TrackStoppedFromOncoming" 11 "MRR_ObjMovingSts_19_B_NoTrack" 14 "MRR_ObjMovingSts_19_E_Error" 15 "MRR_ObjMovingSts_19_F_NotAvailable";
VAL_ 841 MRR_ObjType_19 0 "MRR_ObjType_19_0_unknown" 3 "MRR_ObjType_19_3_pedestrian" 5 "MRR_ObjType_19_5_bicycle" 6 "MRR_ObjType_19_6_motorbike" 7 "MRR_ObjType_19_7_vehicle" 8 "MRR_ObjType_19_8_van" 9 "MRR_ObjType_19_9_truck" 15 "MRR_ObjType_19_F_init";
VAL_ 841 MRR_ObjFolSts_19 0 "MRR_ObjFolSts_19_0_invalid" 1 "MRR_ObjFolSts_19_1_New" 2 "MRR_ObjFolSts_19_2_Update" 3 "MRR_ObjFolSts_19_3_Predicted";
VAL_ 841 MRR_ObjFusionSig_19 0 "MRR_ObjFusionSig_19_0_RadarOnly" 1 "MRR_ObjFusionSig_19_1_FusionWithCamera";
VAL_ 841 MRR_ObjType_20 0 "MRR_ObjType_20_0_unknown" 3 "MRR_ObjType_20_3_pedestrian" 5 "MRR_ObjType_20_5_bicycle" 6 "MRR_ObjType_20_6_motorbike" 7 "MRR_ObjType_20_7_vehicle" 8 "MRR_ObjType_20_8_van" 9 "MRR_ObjType_20_9_truck" 15 "MRR_ObjType_20_F_init";
VAL_ 841 MRR_ObjFolSts_20 0 "MRR_ObjFolSts_20_0_invalid" 1 "MRR_ObjFolSts_20_1_New" 2 "MRR_ObjFolSts_20_2_Update" 3 "MRR_ObjFolSts_20_3_Predicted";
VAL_ 841 MRR_ObjFusionSig_20 0 "MRR_ObjFusionSig_20_0_RadarOnly" 1 "MRR_ObjFusionSig_20_1_FusionWithCamera";
VAL_ 841 MRR_ObjMovingSts_20 0 "MRR_ObjMovingSts_20_0_Stationary" 1 "MRR_ObjMovingSts_20_1_TrackStopppedFromMoving" 2 "MRR_ObjMovingSts_20_2_TrackMoving" 3 "MRR_ObjMovingSts_20_3_TrackOncoming" 4 "MRR_ObjMovingSts_20_4_TrackStoppedFromOncoming" 11 "MRR_ObjMovingSts_20_B_NoTrack" 14 "MRR_ObjMovingSts_20_E_Error" 15 "MRR_ObjMovingSts_20_F_NotAvailable";
VAL_ 842 MRR_ObjMovingSts_21 0 "MRR_ObjMovingSts_21_0_Stationary" 1 "MRR_ObjMovingSts_21_1_TrackStopppedFromMoving" 2 "MRR_ObjMovingSts_21_2_TrackMoving" 3 "MRR_ObjMovingSts_21_3_TrackOncoming" 4 "MRR_ObjMovingSts_21_4_TrackStoppedFromOncoming" 11 "MRR_ObjMovingSts_21_B_NoTrack" 14 "MRR_ObjMovingSts_21_E_Error" 15 "MRR_ObjMovingSts_21_F_NotAvailable";
VAL_ 842 MRR_ObjType_21 0 "MRR_ObjType_21_0_unknown" 3 "MRR_ObjType_21_3_pedestrian" 5 "MRR_ObjType_21_5_bicycle" 6 "MRR_ObjType_21_6_motorbike" 7 "MRR_ObjType_21_7_vehicle" 8 "MRR_ObjType_21_8_van" 9 "MRR_ObjType_21_9_truck" 15 "MRR_ObjType_21_F_init";
VAL_ 842 MRR_ObjFolSts_21 0 "MRR_ObjFolSts_21_0_invalid" 1 "MRR_ObjFolSts_21_1_New" 2 "MRR_ObjFolSts_21_2_Update" 3 "MRR_ObjFolSts_21_3_Predicted";
VAL_ 842 MRR_ObjFusionSig_21 0 "MRR_ObjFusionSig_21_0_RadarOnly" 1 "MRR_ObjFusionSig_21_1_FusionWithCamera";
VAL_ 842 MRR_ObjType_22 0 "MRR_ObjType_22_0_unknown" 3 "MRR_ObjType_22_3_pedestrian" 5 "MRR_ObjType_22_5_bicycle" 6 "MRR_ObjType_22_6_motorbike" 7 "MRR_ObjType_22_7_vehicle" 8 "MRR_ObjType_22_8_van" 9 "MRR_ObjType_22_9_truck" 15 "MRR_ObjType_22_F_init";
VAL_ 842 MRR_ObjFolSts_22 0 "MRR_ObjFolSts_22_0_invalid" 1 "MRR_ObjFolSts_22_1_New" 2 "MRR_ObjFolSts_22_2_Update" 3 "MRR_ObjFolSts_22_3_Predicted";
VAL_ 842 MRR_ObjFusionSig_22 0 "MRR_ObjFusionSig_22_0_RadarOnly" 1 "MRR_ObjFusionSig_22_1_FusionWithCamera";
VAL_ 842 MRR_ObjMovingSts_22 0 "MRR_ObjMovingSts_22_0_Stationary" 1 "MRR_ObjMovingSts_22_1_TrackStopppedFromMoving" 2 "MRR_ObjMovingSts_22_2_TrackMoving" 3 "MRR_ObjMovingSts_22_3_TrackOncoming" 4 "MRR_ObjMovingSts_22_4_TrackStoppedFromOncoming" 11 "MRR_ObjMovingSts_22_B_NoTrack" 14 "MRR_ObjMovingSts_22_E_Error" 15 "MRR_ObjMovingSts_22_F_NotAvailable";
VAL_ 843 MRR_ObjMovingSts_23 0 "MRR_ObjMovingSts_23_0_Stationary" 1 "MRR_ObjMovingSts_23_1_TrackStopppedFromMoving" 2 "MRR_ObjMovingSts_23_2_TrackMoving" 3 "MRR_ObjMovingSts_23_3_TrackOncoming" 4 "MRR_ObjMovingSts_23_4_TrackStoppedFromOncoming" 11 "MRR_ObjMovingSts_23_B_NoTrack" 14 "MRR_ObjMovingSts_23_E_Error" 15 "MRR_ObjMovingSts_23_F_NotAvailable";
VAL_ 843 MRR_ObjType_23 0 "MRR_ObjType_23_0_unknown" 3 "MRR_ObjType_23_3_pedestrian" 5 "MRR_ObjType_23_5_bicycle" 6 "MRR_ObjType_23_6_motorbike" 7 "MRR_ObjType_23_7_vehicle" 8 "MRR_ObjType_23_8_van" 9 "MRR_ObjType_23_9_truck" 15 "MRR_ObjType_23_F_init";
VAL_ 843 MRR_ObjFolSts_23 0 "MRR_ObjFolSts_23_0_invalid" 1 "MRR_ObjFolSts_23_1_New" 2 "MRR_ObjFolSts_23_2_Update" 3 "MRR_ObjFolSts_23_3_Predicted";
VAL_ 843 MRR_ObjFusionSig_23 0 "MRR_ObjFusionSig_23_0_RadarOnly" 1 "MRR_ObjFusionSig_23_1_FusionWithCamera";
VAL_ 843 MRR_ObjType_24 0 "MRR_ObjType_24_0_unknown" 3 "MRR_ObjType_24_3_pedestrian" 5 "MRR_ObjType_24_5_bicycle" 6 "MRR_ObjType_24_6_motorbike" 7 "MRR_ObjType_24_7_vehicle" 8 "MRR_ObjType_24_8_van" 9 "MRR_ObjType_24_9_truck" 15 "MRR_ObjType_24_F_init";
VAL_ 843 MRR_ObjFolSts_24 0 "MRR_ObjFolSts_24_0_invalid" 1 "MRR_ObjFolSts_24_1_New" 2 "MRR_ObjFolSts_24_2_Update" 3 "MRR_ObjFolSts_24_3_Predicted";
VAL_ 843 MRR_ObjFusionSig_24 0 "MRR_ObjFusionSig_24_0_RadarOnly" 1 "MRR_ObjFusionSig_24_1_FusionWithCamera";
VAL_ 843 MRR_ObjMovingSts_24 0 "MRR_ObjMovingSts_24_0_Stationary" 1 "MRR_ObjMovingSts_24_1_TrackStopppedFromMoving" 2 "MRR_ObjMovingSts_24_2_TrackMoving" 3 "MRR_ObjMovingSts_24_3_TrackOncoming" 4 "MRR_ObjMovingSts_24_4_TrackStoppedFromOncoming" 11 "MRR_ObjMovingSts_24_B_NoTrack" 14 "MRR_ObjMovingSts_24_E_Error" 15 "MRR_ObjMovingSts_24_F_NotAvailable";
VAL_ 844 MRR_ObjMovingSts_25 0 "MRR_ObjMovingSts_25_0_Stationary" 1 "MRR_ObjMovingSts_25_1_TrackStopppedFromMoving" 2 "MRR_ObjMovingSts_25_2_TrackMoving" 3 "MRR_ObjMovingSts_25_3_TrackOncoming" 4 "MRR_ObjMovingSts_25_4_TrackStoppedFromOncoming" 11 "MRR_ObjMovingSts_25_B_NoTrack" 14 "MRR_ObjMovingSts_25_E_Error" 15 "MRR_ObjMovingSts_25_F_NotAvailable";
VAL_ 844 MRR_ObjType_25 0 "MRR_ObjType_25_0_unknown" 3 "MRR_ObjType_25_3_pedestrian" 5 "MRR_ObjType_25_5_bicycle" 6 "MRR_ObjType_25_6_motorbike" 7 "MRR_ObjType_25_7_vehicle" 8 "MRR_ObjType_25_8_van" 9 "MRR_ObjType_25_9_truck" 15 "MRR_ObjType_25_F_init";
VAL_ 844 MRR_ObjFolSts_25 0 "MRR_ObjFolSts_25_0_invalid" 1 "MRR_ObjFolSts_25_1_New" 2 "MRR_ObjFolSts_25_2_Update" 3 "MRR_ObjFolSts_25_3_Predicted";
VAL_ 844 MRR_ObjFusionSig_25 0 "MRR_ObjFusionSig_25_0_RadarOnly" 1 "MRR_ObjFusionSig_25_1_FusionWithCamera";
VAL_ 844 MRR_ObjType_26 0 "MRR_ObjType_26_0_unknown" 3 "MRR_ObjType_26_3_pedestrian" 5 "MRR_ObjType_26_5_bicycle" 6 "MRR_ObjType_26_6_motorbike" 7 "MRR_ObjType_26_7_vehicle" 8 "MRR_ObjType_26_8_van" 9 "MRR_ObjType_26_9_truck" 15 "MRR_ObjType_26_F_init";
VAL_ 844 MRR_ObjFolSts_26 0 "MRR_ObjFolSts_26_0_invalid" 1 "MRR_ObjFolSts_26_1_New" 2 "MRR_ObjFolSts_26_2_Update" 3 "MRR_ObjFolSts_26_3_Predicted";
VAL_ 844 MRR_ObjFusionSig_26 0 "MRR_ObjFusionSig_26_0_RadarOnly" 1 "MRR_ObjFusionSig_26_1_FusionWithCamera";
VAL_ 844 MRR_ObjMovingSts_26 0 "MRR_ObjMovingSts_26_0_Stationary" 1 "MRR_ObjMovingSts_26_1_TrackStopppedFromMoving" 2 "MRR_ObjMovingSts_26_2_TrackMoving" 3 "MRR_ObjMovingSts_26_3_TrackOncoming" 4 "MRR_ObjMovingSts_26_4_TrackStoppedFromOncoming" 11 "MRR_ObjMovingSts_26_B_NoTrack" 14 "MRR_ObjMovingSts_26_E_Error" 15 "MRR_ObjMovingSts_26_F_NotAvailable";
VAL_ 845 MRR_ObjMovingSts_27 0 "MRR_ObjMovingSts_27_0_Stationary" 1 "MRR_ObjMovingSts_27_1_TrackStopppedFromMoving" 2 "MRR_ObjMovingSts_27_2_TrackMoving" 3 "MRR_ObjMovingSts_27_3_TrackOncoming" 4 "MRR_ObjMovingSts_27_4_TrackStoppedFromOncoming" 11 "MRR_ObjMovingSts_27_B_NoTrack" 14 "MRR_ObjMovingSts_27_E_Error" 15 "MRR_ObjMovingSts_27_F_NotAvailable";
VAL_ 845 MRR_ObjType_27 0 "MRR_ObjType_27_0_unknown" 3 "MRR_ObjType_27_3_pedestrian" 5 "MRR_ObjType_27_5_bicycle" 6 "MRR_ObjType_27_6_motorbike" 7 "MRR_ObjType_27_7_vehicle" 8 "MRR_ObjType_27_8_van" 9 "MRR_ObjType_27_9_truck" 15 "MRR_ObjType_27_F_init";
VAL_ 845 MRR_ObjFolSts_27 0 "MRR_ObjFolSts_27_0_invalid" 1 "MRR_ObjFolSts_27_1_New" 2 "MRR_ObjFolSts_27_2_Update" 3 "MRR_ObjFolSts_27_3_Predicted";
VAL_ 845 MRR_ObjFusionSig_27 0 "MRR_ObjFusionSig_27_0_RadarOnly" 1 "MRR_ObjFusionSig_27_1_FusionWithCamera";
VAL_ 845 MRR_ObjType_28 0 "MRR_ObjType_28_0_unknown" 3 "MRR_ObjType_28_3_pedestrian" 5 "MRR_ObjType_28_5_bicycle" 6 "MRR_ObjType_28_6_motorbike" 7 "MRR_ObjType_28_7_vehicle" 8 "MRR_ObjType_28_8_van" 9 "MRR_ObjType_28_9_truck" 15 "MRR_ObjType_28_F_init";
VAL_ 845 MRR_ObjFolSts_28 0 "MRR_ObjFolSts_28_0_invalid" 1 "MRR_ObjFolSts_28_1_New" 2 "MRR_ObjFolSts_28_2_Update" 3 "MRR_ObjFolSts_28_3_Predicted";
VAL_ 845 MRR_ObjFusionSig_28 0 "MRR_ObjFusionSig_28_0_RadarOnly" 1 "MRR_ObjFusionSig_28_1_FusionWithCamera";
VAL_ 845 MRR_ObjMovingSts_28 0 "MRR_ObjMovingSts_28_0_Stationary" 1 "MRR_ObjMovingSts_28_1_TrackStopppedFromMoving" 2 "MRR_ObjMovingSts_28_2_TrackMoving" 3 "MRR_ObjMovingSts_28_3_TrackOncoming" 4 "MRR_ObjMovingSts_28_4_TrackStoppedFromOncoming" 11 "MRR_ObjMovingSts_28_B_NoTrack" 14 "MRR_ObjMovingSts_28_E_Error" 15 "MRR_ObjMovingSts_28_F_NotAvailable";
VAL_ 846 MRR_ObjMovingSts_29 0 "MRR_ObjMovingSts_29_0_Stationary" 1 "MRR_ObjMovingSts_29_1_TrackStopppedFromMoving" 2 "MRR_ObjMovingSts_29_2_TrackMoving" 3 "MRR_ObjMovingSts_29_3_TrackOncoming" 4 "MRR_ObjMovingSts_29_4_TrackStoppedFromOncoming" 11 "MRR_ObjMovingSts_29_B_NoTrack" 14 "MRR_ObjMovingSts_29_E_Error" 15 "MRR_ObjMovingSts_29_F_NotAvailable";
VAL_ 846 MRR_ObjType_29 0 "MRR_ObjType_29_0_unknown" 3 "MRR_ObjType_29_3_pedestrian" 5 "MRR_ObjType_29_5_bicycle" 6 "MRR_ObjType_29_6_motorbike" 7 "MRR_ObjType_29_7_vehicle" 8 "MRR_ObjType_29_8_van" 9 "MRR_ObjType_29_9_truck" 15 "MRR_ObjType_29_F_init";
VAL_ 846 MRR_ObjFolSts_29 0 "MRR_ObjFolSts_29_0_invalid" 1 "MRR_ObjFolSts_29_1_New" 2 "MRR_ObjFolSts_29_2_Update" 3 "MRR_ObjFolSts_29_3_Predicted";
VAL_ 846 MRR_ObjFusionSig_29 0 "MRR_ObjFusionSig_29_0_RadarOnly" 1 "MRR_ObjFusionSig_29_1_FusionWithCamera";
VAL_ 846 MRR_ObjType_30 0 "MRR_ObjType_30_0_unknown" 3 "MRR_ObjType_30_3_pedestrian" 5 "MRR_ObjType_30_5_bicycle" 6 "MRR_ObjType_30_6_motorbike" 7 "MRR_ObjType_30_7_vehicle" 8 "MRR_ObjType_30_8_van" 9 "MRR_ObjType_30_9_truck" 15 "MRR_ObjType_30_F_init";
VAL_ 846 MRR_ObjFolSts_30 0 "MRR_ObjFolSts_30_0_invalid" 1 "MRR_ObjFolSts_30_1_New" 2 "MRR_ObjFolSts_30_2_Update" 3 "MRR_ObjFolSts_30_3_Predicted";
VAL_ 846 MRR_ObjFusionSig_30 0 "MRR_ObjFusionSig_30_0_RadarOnly" 1 "MRR_ObjFusionSig_30_1_FusionWithCamera";
VAL_ 846 MRR_ObjMovingSts_30 0 "MRR_ObjMovingSts_30_0_Stationary" 1 "MRR_ObjMovingSts_30_1_TrackStopppedFromMoving" 2 "MRR_ObjMovingSts_30_2_TrackMoving" 3 "MRR_ObjMovingSts_30_3_TrackOncoming" 4 "MRR_ObjMovingSts_30_4_TrackStoppedFromOncoming" 11 "MRR_ObjMovingSts_30_B_NoTrack" 14 "MRR_ObjMovingSts_30_E_Error" 15 "MRR_ObjMovingSts_30_F_NotAvailable";
VAL_ 847 MRR_ObjMovingSts_31 0 "MRR_ObjMovingSts_31_0_Stationary" 1 "MRR_ObjMovingSts_31_1_TrackStopppedFromMoving" 2 "MRR_ObjMovingSts_31_2_TrackMoving" 3 "MRR_ObjMovingSts_31_3_TrackOncoming" 4 "MRR_ObjMovingSts_31_4_TrackStoppedFromOncoming" 11 "MRR_ObjMovingSts_31_B_NoTrack" 14 "MRR_ObjMovingSts_31_E_Error" 15 "MRR_ObjMovingSts_31_F_NotAvailable";
VAL_ 847 MRR_ObjType_31 0 "MRR_ObjType_31_0_unknown" 3 "MRR_ObjType_31_3_pedestrian" 5 "MRR_ObjType_31_5_bicycle" 6 "MRR_ObjType_31_6_motorbike" 7 "MRR_ObjType_31_7_vehicle" 8 "MRR_ObjType_31_8_van" 9 "MRR_ObjType_31_9_truck" 15 "MRR_ObjType_31_F_init";
VAL_ 847 MRR_ObjFolSts_31 0 "MRR_ObjFolSts_31_0_invalid" 1 "MRR_ObjFolSts_31_1_New" 2 "MRR_ObjFolSts_31_2_Update" 3 "MRR_ObjFolSts_31_3_Predicted";
VAL_ 847 MRR_ObjFusionSig_31 0 "MRR_ObjFusionSig_31_0_RadarOnly" 1 "MRR_ObjFusionSig_31_1_FusionWithCamera";
VAL_ 847 MRR_ObjType_32 0 "MRR_ObjType_32_0_unknown" 3 "MRR_ObjType_32_3_pedestrian" 5 "MRR_ObjType_32_5_bicycle" 6 "MRR_ObjType_32_6_motorbike" 7 "MRR_ObjType_32_7_vehicle" 8 "MRR_ObjType_32_8_van" 9 "MRR_ObjType_32_9_truck" 15 "MRR_ObjType_32_F_init";
VAL_ 847 MRR_ObjFolSts_32 0 "MRR_ObjFolSts_32_0_invalid" 1 "MRR_ObjFolSts_32_1_New" 2 "MRR_ObjFolSts_32_2_Update" 3 "MRR_ObjFolSts_32_3_Predicted";
VAL_ 847 MRR_ObjFusionSig_32 0 "MRR_ObjFusionSig_32_0_RadarOnly" 1 "MRR_ObjFusionSig_32_1_FusionWithCamera";
VAL_ 847 MRR_ObjMovingSts_32 0 "MRR_ObjMovingSts_32_0_Stationary" 1 "MRR_ObjMovingSts_32_1_TrackStopppedFromMoving" 2 "MRR_ObjMovingSts_32_2_TrackMoving" 3 "MRR_ObjMovingSts_32_3_TrackOncoming" 4 "MRR_ObjMovingSts_32_4_TrackStoppedFromOncoming" 11 "MRR_ObjMovingSts_32_B_NoTrack" 14 "MRR_ObjMovingSts_32_E_Error" 15 "MRR_ObjMovingSts_32_F_NotAvailable";
SIG_GROUP_ 840 IFDR_ADAS_LocalCANFD3_Group17 1 : MRR_ObjAccelX_17 MRR_ObjAccelY_17 MRR_ObjDistXStd_17 MRR_ObjDistX_17 MRR_ObjDistYStd_17 MRR_ObjDistY_17 MRR_ObjExistProb_17 MRR_ObjFolSts_17 MRR_ObjFusionCamID_17 MRR_ObjFusionSig_17 MRR_ObjID_17 MRR_ObjMovingSts_17 MRR_ObjObstacleProb_17 MRR_ObjRAccelXStd_17 MRR_ObjRAccelYStd_17 MRR_ObjRelVelXStd_17 MRR_ObjRelVelX_17 MRR_ObjRelVelYStd_17 MRR_ObjRelVelY_17 MRR_ObjType_17 MRR_Obj_CRC16Checksum_17 MRR_Obj_MsgCounter_17;
SIG_GROUP_ 840 IFDR_ADAS_LocalCANFD3_Group18 2 : MRR_ObjAccelX_18 MRR_ObjAccelY_18 MRR_ObjDistXStd_18 MRR_ObjDistX_18 MRR_ObjDistYStd_18 MRR_ObjDistY_18 MRR_ObjExistProb_18 MRR_ObjFolSts_18 MRR_ObjFusionCamID_18 MRR_ObjFusionSig_18 MRR_ObjID_18 MRR_ObjMovingSts_18 MRR_ObjObstacleProb_18 MRR_ObjRAccelXStd_18 MRR_ObjRAccelYStd_18 MRR_ObjRelVelXStd_18 MRR_ObjRelVelX_18 MRR_ObjRelVelYStd_18 MRR_ObjRelVelY_18 MRR_ObjType_18 MRR_Obj_CRC16Checksum_18 MRR_Obj_MsgCounter_18;
SIG_GROUP_ 841 IFDR_ADAS_LocalCANFD3_Group19 1 : MRR_ObjAccelX_19 MRR_ObjAccelY_19 MRR_ObjDistXStd_19 MRR_ObjDistX_19 MRR_ObjDistYStd_19 MRR_ObjDistY_19 MRR_ObjExistProb_19 MRR_ObjFolSts_19 MRR_ObjFusionCamID_19 MRR_ObjFusionSig_19 MRR_ObjID_19 MRR_ObjMovingSts_19 MRR_ObjObstacleProb_19 MRR_ObjRAccelXStd_19 MRR_ObjRAccelYStd_19 MRR_ObjRelVelXStd_19 MRR_ObjRelVelX_19 MRR_ObjRelVelYStd_19 MRR_ObjRelVelY_19 MRR_ObjType_19 MRR_Obj_CRC16Checksum_19 MRR_Obj_MsgCounter_19;
SIG_GROUP_ 841 IFDR_ADAS_LocalCANFD3_Group20 2 : MRR_ObjAccelX_20 MRR_ObjAccelY_20 MRR_ObjDistXStd_20 MRR_ObjDistX_20 MRR_ObjDistYStd_20 MRR_ObjDistY_20 MRR_ObjExistProb_20 MRR_ObjFolSts_20 MRR_ObjFusionCamID_20 MRR_ObjFusionSig_20 MRR_ObjID_20 MRR_ObjMovingSts_20 MRR_ObjObstacleProb_20 MRR_ObjRAccelXStd_20 MRR_ObjRAccelYStd_20 MRR_ObjRelVelXStd_20 MRR_ObjRelVelX_20 MRR_ObjRelVelYStd_20 MRR_ObjRelVelY_20 MRR_ObjType_20 MRR_Obj_CRC16Checksum_20 MRR_Obj_MsgCounter_20;
SIG_GROUP_ 842 IFDR_ADAS_LocalCANFD3_Group21 1 : MRR_ObjAccelX_21 MRR_ObjAccelY_21 MRR_ObjDistXStd_21 MRR_ObjDistX_21 MRR_ObjDistYStd_21 MRR_ObjDistY_21 MRR_ObjExistProb_21 MRR_ObjFolSts_21 MRR_ObjFusionCamID_21 MRR_ObjFusionSig_21 MRR_ObjID_21 MRR_ObjMovingSts_21 MRR_ObjObstacleProb_21 MRR_ObjRAccelXStd_21 MRR_ObjRAccelYStd_21 MRR_ObjRelVelXStd_21 MRR_ObjRelVelX_21 MRR_ObjRelVelYStd_21 MRR_ObjRelVelY_21 MRR_ObjType_21 MRR_Obj_CRC16Checksum_21 MRR_Obj_MsgCounter_21;
SIG_GROUP_ 842 IFDR_ADAS_LocalCANFD3_Group22 2 : MRR_ObjAccelX_22 MRR_ObjAccelY_22 MRR_ObjDistXStd_22 MRR_ObjDistX_22 MRR_ObjDistYStd_22 MRR_ObjDistY_22 MRR_ObjExistProb_22 MRR_ObjFolSts_22 MRR_ObjFusionCamID_22 MRR_ObjFusionSig_22 MRR_ObjID_22 MRR_ObjMovingSts_22 MRR_ObjObstacleProb_22 MRR_ObjRAccelXStd_22 MRR_ObjRAccelYStd_22 MRR_ObjRelVelXStd_22 MRR_ObjRelVelX_22 MRR_ObjRelVelYStd_22 MRR_ObjRelVelY_22 MRR_ObjType_22 MRR_Obj_CRC16Checksum_22 MRR_Obj_MsgCounter_22;
SIG_GROUP_ 843 IFDR_ADAS_LocalCANFD3_Group23 1 : MRR_ObjAccelX_23 MRR_ObjAccelY_23 MRR_ObjDistXStd_23 MRR_ObjDistX_23 MRR_ObjDistYStd_23 MRR_ObjDistY_23 MRR_ObjExistProb_23 MRR_ObjFolSts_23 MRR_ObjFusionCamID_23 MRR_ObjFusionSig_23 MRR_ObjID_23 MRR_ObjMovingSts_23 MRR_ObjObstacleProb_23 MRR_ObjRAccelXStd_23 MRR_ObjRAccelYStd_23 MRR_ObjRelVelXStd_23 MRR_ObjRelVelX_23 MRR_ObjRelVelYStd_23 MRR_ObjRelVelY_23 MRR_ObjType_23 MRR_Obj_CRC16Checksum_23 MRR_Obj_MsgCounter_23;
SIG_GROUP_ 843 IFDR_ADAS_LocalCANFD3_Group24 2 : MRR_ObjAccelX_24 MRR_ObjAccelY_24 MRR_ObjDistXStd_24 MRR_ObjDistX_24 MRR_ObjDistYStd_24 MRR_ObjDistY_24 MRR_ObjExistProb_24 MRR_ObjFolSts_24 MRR_ObjFusionCamID_24 MRR_ObjFusionSig_24 MRR_ObjID_24 MRR_ObjMovingSts_24 MRR_ObjObstacleProb_24 MRR_ObjRAccelXStd_24 MRR_ObjRAccelYStd_24 MRR_ObjRelVelXStd_24 MRR_ObjRelVelX_24 MRR_ObjRelVelYStd_24 MRR_ObjRelVelY_24 MRR_ObjType_24 MRR_Obj_CRC16Checksum_24 MRR_Obj_MsgCounter_24;
SIG_GROUP_ 844 IFDR_ADAS_LocalCANFD3_Group25 1 : MRR_ObjAccelX_25 MRR_ObjAccelY_25 MRR_ObjDistXStd_25 MRR_ObjDistX_25 MRR_ObjDistYStd_25 MRR_ObjDistY_25 MRR_ObjExistProb_25 MRR_ObjFolSts_25 MRR_ObjFusionCamID_25 MRR_ObjFusionSig_25 MRR_ObjID_25 MRR_ObjMovingSts_25 MRR_ObjObstacleProb_25 MRR_ObjRAccelXStd_25 MRR_ObjRAccelYStd_25 MRR_ObjRelVelXStd_25 MRR_ObjRelVelX_25 MRR_ObjRelVelYStd_25 MRR_ObjRelVelY_25 MRR_ObjType_25 MRR_Obj_CRC16Checksum_25 MRR_Obj_MsgCounter_25;
SIG_GROUP_ 844 IFDR_ADAS_LocalCANFD3_Group26 2 : MRR_ObjAccelX_26 MRR_ObjAccelY_26 MRR_ObjDistXStd_26 MRR_ObjDistX_26 MRR_ObjDistYStd_26 MRR_ObjDistY_26 MRR_ObjExistProb_26 MRR_ObjFolSts_26 MRR_ObjFusionCamID_26 MRR_ObjFusionSig_26 MRR_ObjID_26 MRR_ObjMovingSts_26 MRR_ObjObstacleProb_26 MRR_ObjRAccelXStd_26 MRR_ObjRAccelYStd_26 MRR_ObjRelVelXStd_26 MRR_ObjRelVelX_26 MRR_ObjRelVelYStd_26 MRR_ObjRelVelY_26 MRR_ObjType_26 MRR_Obj_CRC16Checksum_26 MRR_Obj_MsgCounter_26;
SIG_GROUP_ 845 IFDR_ADAS_LocalCANFD3_Group27 1 : MRR_ObjAccelX_27 MRR_ObjAccelY_27 MRR_ObjDistXStd_27 MRR_ObjDistX_27 MRR_ObjDistYStd_27 MRR_ObjDistY_27 MRR_ObjExistProb_27 MRR_ObjFolSts_27 MRR_ObjFusionCamID_27 MRR_ObjFusionSig_27 MRR_ObjID_27 MRR_ObjMovingSts_27 MRR_ObjObstacleProb_27 MRR_ObjRAccelXStd_27 MRR_ObjRAccelYStd_27 MRR_ObjRelVelXStd_27 MRR_ObjRelVelX_27 MRR_ObjRelVelYStd_27 MRR_ObjRelVelY_27 MRR_ObjType_27 MRR_Obj_CRC16Checksum_27 MRR_Obj_MsgCounter_27;
SIG_GROUP_ 845 IFDR_ADAS_LocalCANFD3_Group28 2 : MRR_ObjAccelX_28 MRR_ObjAccelY_28 MRR_ObjDistXStd_28 MRR_ObjDistX_28 MRR_ObjDistYStd_28 MRR_ObjDistY_28 MRR_ObjExistProb_28 MRR_ObjFolSts_28 MRR_ObjFusionCamID_28 MRR_ObjFusionSig_28 MRR_ObjID_28 MRR_ObjMovingSts_28 MRR_ObjObstacleProb_28 MRR_ObjRAccelXStd_28 MRR_ObjRAccelYStd_28 MRR_ObjRelVelXStd_28 MRR_ObjRelVelX_28 MRR_ObjRelVelYStd_28 MRR_ObjRelVelY_28 MRR_ObjType_28 MRR_Obj_CRC16Checksum_28 MRR_Obj_MsgCounter_28;
SIG_GROUP_ 846 IFDR_ADAS_LocalCANFD3_Group29 1 : MRR_ObjAccelX_29 MRR_ObjAccelY_29 MRR_ObjDistXStd_29 MRR_ObjDistX_29 MRR_ObjDistYStd_29 MRR_ObjDistY_29 MRR_ObjExistProb_29 MRR_ObjFolSts_29 MRR_ObjFusionCamID_29 MRR_ObjFusionSig_29 MRR_ObjID_29 MRR_ObjMovingSts_29 MRR_ObjObstacleProb_29 MRR_ObjRAccelXStd_29 MRR_ObjRAccelYStd_29 MRR_ObjRelVelXStd_29 MRR_ObjRelVelX_29 MRR_ObjRelVelYStd_29 MRR_ObjRelVelY_29 MRR_ObjType_29 MRR_Obj_CRC16Checksum_29 MRR_Obj_MsgCounter_29;
SIG_GROUP_ 846 IFDR_ADAS_LocalCANFD3_Group30 2 : MRR_ObjAccelX_30 MRR_ObjAccelY_30 MRR_ObjDistXStd_30 MRR_ObjDistX_30 MRR_ObjDistYStd_30 MRR_ObjDistY_30 MRR_ObjExistProb_30 MRR_ObjFolSts_30 MRR_ObjFusionCamID_30 MRR_ObjFusionSig_30 MRR_ObjID_30 MRR_ObjMovingSts_30 MRR_ObjObstacleProb_30 MRR_ObjRAccelXStd_30 MRR_ObjRAccelYStd_30 MRR_ObjRelVelXStd_30 MRR_ObjRelVelX_30 MRR_ObjRelVelYStd_30 MRR_ObjRelVelY_30 MRR_ObjType_30 MRR_Obj_CRC16Checksum_30 MRR_Obj_MsgCounter_30;
SIG_GROUP_ 847 IFDR_ADAS_LocalCANFD3_Group31 1 : MRR_ObjAccelX_31 MRR_ObjAccelY_31 MRR_ObjDistXStd_31 MRR_ObjDistX_31 MRR_ObjDistYStd_31 MRR_ObjDistY_31 MRR_ObjExistProb_31 MRR_ObjFolSts_31 MRR_ObjFusionCamID_31 MRR_ObjFusionSig_31 MRR_ObjID_31 MRR_ObjMovingSts_31 MRR_ObjObstacleProb_31 MRR_ObjRAccelXStd_31 MRR_ObjRAccelYStd_31 MRR_ObjRelVelXStd_31 MRR_ObjRelVelX_31 MRR_ObjRelVelYStd_31 MRR_ObjRelVelY_31 MRR_ObjType_31 MRR_Obj_CRC16Checksum_31 MRR_Obj_MsgCounter_31;
SIG_GROUP_ 847 IFDR_ADAS_LocalCANFD3_Group32 2 : MRR_ObjAccelX_32 MRR_ObjAccelY_32 MRR_ObjDistXStd_32 MRR_ObjDistX_32 MRR_ObjDistYStd_32 MRR_ObjDistY_32 MRR_ObjExistProb_32 MRR_ObjFolSts_32 MRR_ObjFusionCamID_32 MRR_ObjFusionSig_32 MRR_ObjID_32 MRR_ObjMovingSts_32 MRR_ObjObstacleProb_32 MRR_ObjRAccelXStd_32 MRR_ObjRAccelYStd_32 MRR_ObjRelVelXStd_32 MRR_ObjRelVelX_32 MRR_ObjRelVelYStd_32 MRR_ObjRelVelY_32 MRR_ObjType_32 MRR_Obj_CRC16Checksum_32 MRR_Obj_MsgCounter_32;
SIG_GROUP_ 848 IFDR_ADAS_LocalCANFD3_Group33 1 : FDR_ADAS_LocalCANFD3_Group33_Res0 FDR_ADAS_LocalCANFD3_Group33_Res1 FDR_ADAS_LocalCANFD3_Group33_Res2 FDR_ADAS_LocalCANFD3_Group33_Res3 FDR_ADAS_LocalCANFD3_Group33_Res4 FDR_ADAS_LocalCANFD3_Group33_Res5 FDR_ADAS_LocalCANFD3_Group33_Res6 FDR_ADAS_LocalCANFD3_PDU17_CRC FDR_ADAS_LocalCANFD3_PDU17_RC FDR_AEB_TargAx FDR_AEB_TargAy FDR_AEB_TargDx FDR_AEB_TargDy FDR_AEB_TargExistProb FDR_AEB_TargVx FDR_AEB_TargVy;
